VERSION ""

NS_ :

BS_:

BU_: MRRFR External_Tool CADM MRRFL

BO_ 680 MRR_FL_Radar_Reset_Msg: 1 MRRFL
 SG_ MRR_FL_Radar_Reset : 7|1@0+ (1,0) [0|1] ""  CADM

BO_ 679 MRR_FR_Radar_Reset_Msg: 1 MRRFR
 SG_ MRR_FR_Radar_Reset : 7|1@0+ (1,0) [0|1] ""  CADM

BO_ 762 MRR_FL_Radar_PartNumber: 64 MRRFL
 SG_ MRR_FL_EBOM_SW_PN_Part2 : 367|40@0+ (1,0) [0|1099511627775] ""  CADM
 SG_ MRR_FL_EBOM_SW_PN_Part1 : 327|40@0+ (1,0) [0|1099511627775] ""  CADM
 SG_ MRR_FL_ECU_SerialNumber_Part2 : 159|56@0+ (1,0) [0|7.20575940379279E+016] ""  CADM
 SG_ MRR_FL_ECU_SerialNumber_Part1 : 95|64@0+ (1,0) [0|1.84467440737096E+019] ""  CADM
 SG_ MRR_FL_EBOM_ECU_PN_Part2 : 447|40@0+ (1,0) [0|1099511627775] ""  CADM
 SG_ MRR_FL_EBOM_ECU_PN_Part1 : 407|40@0+ (1,0) [0|1099511627775] ""  CADM
 SG_ MRR_FL_SupplManuf_ECU_SW_VesrNum : 311|16@0+ (1,0) [0|65535] ""  CADM
 SG_ MRR_FL_SupplManuf_ECU_HW_VesrNum : 303|8@0+ (1,0) [0|255] ""  CADM
 SG_ MRR_FL_SupplManuf_ECU_SW_PN_2 : 263|40@0+ (1,0) [0|1099511627775] ""  CADM
 SG_ MRR_FL_SupplManuf_ECU_SW_PN_1 : 215|48@0+ (1,0) [0|281474976710655] ""  CADM
 SG_ MRR_FL_SupplManuf_ECU_HW_PN_2 : 55|40@0+ (1,0) [0|1099511627775] ""  CADM
 SG_ MRR_FL_SupplManuf_ECU_HW_PN_1 : 7|48@0+ (1,0) [0|281474976710655] ""  CADM

BO_ 692 MRR_FR_Radar_PartNumber: 64 MRRFR
 SG_ MRR_FR_EBOM_SW_PN_Part2 : 367|40@0+ (1,0) [0|1099511627775] ""  CADM
 SG_ MRR_FR_EBOM_SW_PN_Part1 : 327|40@0+ (1,0) [0|1099511627775] ""  CADM
 SG_ MRR_FR_ECU_SerialNumber_Part2 : 159|56@0+ (1,0) [0|7.20575940379279E+016] ""  CADM
 SG_ MRR_FR_ECU_SerialNumber_Part1 : 95|64@0+ (1,0) [0|1.84467440737096E+019] ""  CADM
 SG_ MRR_FR_EBOM_ECU_PN_Part2 : 447|40@0+ (1,0) [0|1099511627775] ""  CADM
 SG_ MRR_FR_EBOM_ECU_PN_Part1 : 407|40@0+ (1,0) [0|1099511627775] ""  CADM
 SG_ MRR_FR_SupplManuf_ECU_SW_VesrNum : 311|16@0+ (1,0) [0|65535] ""  CADM
 SG_ MRR_FR_SupplManuf_ECU_HW_VesrNum : 303|8@0+ (1,0) [0|255] ""  CADM
 SG_ MRR_FR_SupplManuf_ECU_SW_PN_2 : 263|40@0+ (1,0) [0|1099511627775] ""  CADM
 SG_ MRR_FR_SupplManuf_ECU_SW_PN_1 : 215|48@0+ (1,0) [0|281474976710655] ""  CADM
 SG_ MRR_FR_SupplManuf_ECU_HW_PN_2 : 55|40@0+ (1,0) [0|1099511627775] ""  CADM
 SG_ MRR_FR_SupplManuf_ECU_HW_PN_1 : 7|48@0+ (1,0) [0|281474976710655] ""  CADM

BO_ 37 MRR_FR_Angle_Adjustment_Table: 20 CADM
 SG_ MRR_FR_AAT_MC : 139|4@0+ (1,0) [0|15] ""  MRRFR
 SG_ MRR_FR_AAT_CRC : 151|16@0+ (1,0) [0|65535] ""  MRRFR
 SG_ MRR_FR_POS_80 : 135|8@0- (0.1,0) [-5|5] "deg"  MRRFR
 SG_ MRR_FR_POS_70 : 127|8@0- (0.1,0) [-5|5] "deg"  MRRFR
 SG_ MRR_FR_POS_60 : 119|8@0- (0.1,0) [-5|5] "deg"  MRRFR
 SG_ MRR_FR_POS_50 : 111|8@0- (0.1,0) [-5|5] "deg"  MRRFR
 SG_ MRR_FR_POS_40 : 103|8@0- (0.1,0) [-5|5] "deg"  MRRFR
 SG_ MRR_FR_POS_30 : 95|8@0- (0.1,0) [-5|5] "deg"  MRRFR
 SG_ MRR_FR_POS_20 : 87|8@0- (0.1,0) [-5|5] "deg"  MRRFR
 SG_ MRR_FR_POS_10 : 79|8@0- (0.1,0) [-5|5] "deg"  MRRFR
 SG_ MRR_FR_0 : 71|8@0- (0.1,0) [-5|5] "deg"  MRRFR
 SG_ MRR_FR_NEG_10 : 63|8@0- (0.1,0) [-5|5] "deg"  MRRFR
 SG_ MRR_FR_NEG_20 : 55|8@0- (0.1,0) [-5|5] "deg"  MRRFR
 SG_ MRR_FR_NEG_30 : 47|8@0- (0.1,0) [-5|5] "deg"  MRRFR
 SG_ MRR_FR_NEG_40 : 39|8@0- (0.1,0) [-5|5] "deg"  MRRFR
 SG_ MRR_FR_NEG_50 : 31|8@0- (0.1,0) [-5|5] "deg"  MRRFR
 SG_ MRR_FR_NEG_60 : 23|8@0- (0.1,0) [-5|5] "deg"  MRRFR
 SG_ MRR_FR_NEG_70 : 15|8@0- (0.1,0) [-5|5] "deg"  MRRFR
 SG_ MRR_FR_NEG_80 : 7|8@0- (0.1,0) [-5|5] "deg"  MRRFR

BO_ 36 MRR_FL_Angle_Adjustment_Table: 20 CADM
 SG_ MRR_FL_AAT_CRC : 151|16@0+ (1,0) [0|65535] ""  MRRFL
 SG_ MRR_FL_AAT_MC : 139|4@0+ (1,0) [0|15] ""  MRRFL
 SG_ MRR_FL_POS_80 : 135|8@0- (0.1,0) [-5|5] "deg"  MRRFL
 SG_ MRR_FL_POS_70 : 127|8@0- (0.1,0) [-5|5] "deg"  MRRFL
 SG_ MRR_FL_POS_60 : 119|8@0- (0.1,0) [-5|5] "deg"  MRRFL
 SG_ MRR_FL_POS_50 : 111|8@0- (0.1,0) [-5|5] "deg"  MRRFL
 SG_ MRR_FL_POS_40 : 103|8@0- (0.1,0) [-5|5] "deg"  MRRFL
 SG_ MRR_FL_POS_30 : 95|8@0- (0.1,0) [-5|5] "deg"  MRRFL
 SG_ MRR_FL_POS_20 : 87|8@0- (0.1,0) [-5|5] "deg"  MRRFL
 SG_ MRR_FL_POS_10 : 79|8@0- (0.1,0) [-5|5] "deg"  MRRFL
 SG_ MRR_FL_0 : 71|8@0- (0.1,0) [-5|5] "deg"  MRRFL
 SG_ MRR_FL_NEG_80 : 7|8@0- (0.1,0) [-5|5] "deg"  MRRFL
 SG_ MRR_FL_NEG_70 : 15|8@0- (0.1,0) [-5|5] "deg"  MRRFL
 SG_ MRR_FL_NEG_60 : 23|8@0- (0.1,0) [-5|5] "deg"  MRRFL
 SG_ MRR_FL_NEG_50 : 31|8@0- (0.1,0) [-5|5] "deg"  MRRFL
 SG_ MRR_FL_NEG_40 : 39|8@0- (0.1,0) [-5|5] "deg"  MRRFL
 SG_ MRR_FL_NEG_30 : 47|8@0- (0.1,0) [-5|5] "deg"  MRRFL
 SG_ MRR_FL_NEG_20 : 55|8@0- (0.1,0) [-5|5] "deg"  MRRFL
 SG_ MRR_FL_NEG_10 : 63|8@0- (0.1,0) [-5|5] "deg"  MRRFL

BO_ 673 MRR_CADM_TracksChange: 1 CADM
 SG_ MRR_f_Radar_Unreasonable : 7|1@0+ (1,0) [0|1] ""  MRRFL,MRRFR

BO_ 768 MRR_FL_Detection_001_007: 64 MRRFL
 SG_ MRR_FL_CAN_DET_MID_TARGET_007 : 462|1@0+ (1,0) [0|1] ""  CADM
 SG_ MRR_FL_CAN_DET_MID_TARGET_006 : 461|1@0+ (1,0) [0|1] ""  CADM
 SG_ MRR_FL_CAN_DET_MID_TARGET_005 : 460|1@0+ (1,0) [0|1] ""  CADM
 SG_ MRR_FL_CAN_DET_MID_TARGET_004 : 459|1@0+ (1,0) [0|1] ""  CADM
 SG_ MRR_FL_CAN_DET_MID_TARGET_003 : 458|1@0+ (1,0) [0|1] ""  CADM
 SG_ MRR_FL_CAN_DET_MID_TARGET_002 : 457|1@0+ (1,0) [0|1] ""  CADM
 SG_ MRR_FL_CAN_DET_MID_TARGET_001 : 456|1@0+ (1,0) [0|1] ""  CADM
 SG_ MRR_FL_CAN_DET_Near_TARGET_007 : 454|1@0+ (1,0) [0|1] ""  CADM
 SG_ MRR_FL_CAN_DET_Near_TARGET_006 : 453|1@0+ (1,0) [0|1] ""  CADM
 SG_ MRR_FL_CAN_DET_Near_TARGET_005 : 452|1@0+ (1,0) [0|1] ""  CADM
 SG_ MRR_FL_CAN_DET_Near_TARGET_004 : 451|1@0+ (1,0) [0|1] ""  CADM
 SG_ MRR_FL_CAN_DET_Near_TARGET_003 : 450|1@0+ (1,0) [0|1] ""  CADM
 SG_ MRR_FL_CAN_DET_Near_TARGET_002 : 449|1@0+ (1,0) [0|1] ""  CADM
 SG_ MRR_FL_CAN_DET_Near_TARGET_001 : 448|1@0+ (1,0) [0|1] ""  CADM
 SG_ MRR_FL_CAN_DET_ELEVATION_001 : 63|7@0+ (0.002748,-0.1745) [-0.1745|0.174496] "rad"  CADM
 SG_ MRR_FL_CAN_DET_CONFID_AZIMUTH_00 : 33|2@0+ (1,0) [0|3] ""  CADM
 SG_ MRR_FL_CAN_DET_SUPER_RES_TARGET_ : 56|1@0+ (1,0) [0|1] ""  CADM
 SG_ MRR_FL_CAN_DET_CONFID_ELEVATION_ : 49|1@0+ (1,0) [0|1] ""  CADM
 SG_ MRR_FL_CAN_DET_HOST_VEH_CLUTTER_ : 48|1@0+ (1,0) [0|1] ""  CADM
 SG_ MRR_FL_CAN_DET_VALID_LEVEL_001 : 0|1@0+ (1,0) [0|1] ""  CADM
 SG_ MRR_FL_CAN_DET_AZIMUTH_001 : 47|14@0+ (0.0003834,-3.1416) [-3.1416|3.1396422] "rad"  CADM
 SG_ MRR_FL_CAN_DET_RANGE_001 : 31|14@0+ (0.015625,0) [0|255.984375] "m"  CADM
 SG_ MRR_FL_CAN_DET_RANGE_RATE_001 : 15|14@0+ (0.015625,-128) [-128|127.984375] "m/s"  CADM
 SG_ MRR_FL_CAN_DET_AMPLITUDE_001 : 7|7@0+ (1,-64) [-64|63] "dBsm"  CADM
 SG_ MRR_FL_CAN_SCAN_INDEX_2LSB_001 : 17|2@0+ (1,0) [0|3] ""  CADM
 SG_ MRR_FL_DET_MC_001 : 491|4@0+ (1,0) [0|15] ""  CADM
 SG_ MRR_FL_DET_CRC_001 : 503|16@0+ (1,0) [0|65535] ""  CADM
 SG_ MRR_FL_CAN_DET_ELEVATION_007 : 447|7@0+ (0.002748,-0.1745) [-0.1745|0.174496] "rad"  CADM
 SG_ MRR_FL_CAN_DET_SUPER_RES_TA_0000 : 440|1@0+ (1,0) [0|1] ""  CADM
 SG_ MRR_FL_CAN_DET_AZIMUTH_007 : 431|14@0+ (0.0003834,-3.1416) [-3.1416|3.1396422] "rad"  CADM
 SG_ MRR_FL_CAN_DET_CONFID_ELEVA_0000 : 433|1@0+ (1,0) [0|1] ""  CADM
 SG_ MRR_FL_CAN_DET_HOST_VEH_CLU_0000 : 432|1@0+ (1,0) [0|1] ""  CADM
 SG_ MRR_FL_CAN_DET_RANGE_007 : 415|14@0+ (0.015625,0) [0|255.984375] "m"  CADM
 SG_ MRR_FL_CAN_DET_CONFID_AZIMU_0000 : 417|2@0+ (1,0) [0|3] ""  CADM
 SG_ MRR_FL_CAN_DET_RANGE_RATE_007 : 399|14@0+ (0.015625,-128) [-128|127.984375] "m/s"  CADM
 SG_ MRR_FL_CAN_SCAN_INDEX_2LSB_007 : 401|2@0+ (1,0) [0|3] ""  CADM
 SG_ MRR_FL_CAN_DET_AMPLITUDE_007 : 391|7@0+ (1,-64) [-64|63] "dBsm"  CADM
 SG_ MRR_FL_CAN_DET_VALID_LEVEL_007 : 384|1@0+ (1,0) [0|1] ""  CADM
 SG_ MRR_FL_CAN_DET_ELEVATION_006 : 383|7@0+ (0.002748,-0.1745) [-0.1745|0.174496] "rad"  CADM
 SG_ MRR_FL_CAN_DET_SUPER_RES_TA_0001 : 376|1@0+ (1,0) [0|1] ""  CADM
 SG_ MRR_FL_CAN_DET_AZIMUTH_006 : 367|14@0+ (0.0003834,-3.1416) [-3.1416|3.1396422] "rad"  CADM
 SG_ MRR_FL_CAN_DET_CONFID_ELEVA_0001 : 369|1@0+ (1,0) [0|1] ""  CADM
 SG_ MRR_FL_CAN_DET_HOST_VEH_CLU_0001 : 368|1@0+ (1,0) [0|1] ""  CADM
 SG_ MRR_FL_CAN_DET_RANGE_006 : 351|14@0+ (0.015625,0) [0|255.984375] "m"  CADM
 SG_ MRR_FL_CAN_DET_CONFID_AZIMU_0001 : 353|2@0+ (1,0) [0|3] ""  CADM
 SG_ MRR_FL_CAN_DET_RANGE_RATE_006 : 335|14@0+ (0.015625,-128) [-128|127.984375] "m/s"  CADM
 SG_ MRR_FL_CAN_SCAN_INDEX_2LSB_006 : 337|2@0+ (1,0) [0|3] ""  CADM
 SG_ MRR_FL_CAN_DET_AMPLITUDE_006 : 327|7@0+ (1,-64) [-64|63] "dBsm"  CADM
 SG_ MRR_FL_CAN_DET_VALID_LEVEL_006 : 320|1@0+ (1,0) [0|1] ""  CADM
 SG_ MRR_FL_CAN_DET_ELEVATION_005 : 319|7@0+ (0.002748,-0.1745) [-0.1745|0.174496] "rad"  CADM
 SG_ MRR_FL_CAN_DET_SUPER_RES_TA_0002 : 312|1@0+ (1,0) [0|1] ""  CADM
 SG_ MRR_FL_CAN_DET_AZIMUTH_005 : 303|14@0+ (0.0003834,-3.1416) [-3.1416|3.1396422] "rad"  CADM
 SG_ MRR_FL_CAN_DET_CONFID_ELEVA_0002 : 305|1@0+ (1,0) [0|1] ""  CADM
 SG_ MRR_FL_CAN_DET_HOST_VEH_CLU_0002 : 304|1@0+ (1,0) [0|1] ""  CADM
 SG_ MRR_FL_CAN_DET_RANGE_005 : 287|14@0+ (0.015625,0) [0|255.984375] "m"  CADM
 SG_ MRR_FL_CAN_DET_CONFID_AZIMU_0002 : 289|2@0+ (1,0) [0|3] ""  CADM
 SG_ MRR_FL_CAN_DET_RANGE_RATE_005 : 271|14@0+ (0.015625,-128) [-128|127.984375] "m/s"  CADM
 SG_ MRR_FL_CAN_SCAN_INDEX_2LSB_005 : 273|2@0+ (1,0) [0|3] ""  CADM
 SG_ MRR_FL_CAN_DET_AMPLITUDE_005 : 263|7@0+ (1,-64) [-64|63] "dBsm"  CADM
 SG_ MRR_FL_CAN_DET_VALID_LEVEL_005 : 256|1@0+ (1,0) [0|1] ""  CADM
 SG_ MRR_FL_CAN_DET_ELEVATION_004 : 255|7@0+ (0.002748,-0.1745) [-0.1745|0.174496] "rad"  CADM
 SG_ MRR_FL_CAN_DET_SUPER_RES_TA_0003 : 248|1@0+ (1,0) [0|1] ""  CADM
 SG_ MRR_FL_CAN_DET_AZIMUTH_004 : 239|14@0+ (0.0003834,-3.1416) [-3.1416|3.1396422] "rad"  CADM
 SG_ MRR_FL_CAN_DET_CONFID_ELEVA_0003 : 241|1@0+ (1,0) [0|1] ""  CADM
 SG_ MRR_FL_CAN_DET_HOST_VEH_CLU_0003 : 240|1@0+ (1,0) [0|1] ""  CADM
 SG_ MRR_FL_CAN_DET_RANGE_004 : 223|14@0+ (0.015625,0) [0|255.984375] "m"  CADM
 SG_ MRR_FL_CAN_DET_CONFID_AZIMU_0003 : 225|2@0+ (1,0) [0|3] ""  CADM
 SG_ MRR_FL_CAN_DET_RANGE_RATE_004 : 207|14@0+ (0.015625,-128) [-128|127.984375] "m/s"  CADM
 SG_ MRR_FL_CAN_SCAN_INDEX_2LSB_004 : 209|2@0+ (1,0) [0|3] ""  CADM
 SG_ MRR_FL_CAN_DET_AMPLITUDE_004 : 199|7@0+ (1,-64) [-64|63] "dBsm"  CADM
 SG_ MRR_FL_CAN_DET_VALID_LEVEL_004 : 192|1@0+ (1,0) [0|1] ""  CADM
 SG_ MRR_FL_CAN_DET_ELEVATION_003 : 191|7@0+ (0.002748,-0.1745) [-0.1745|0.174496] "rad"  CADM
 SG_ MRR_FL_CAN_DET_SUPER_RES_TA_0004 : 184|1@0+ (1,0) [0|1] ""  CADM
 SG_ MRR_FL_CAN_DET_AZIMUTH_003 : 175|14@0+ (0.0003834,-3.1416) [-3.1416|3.1396422] "rad"  CADM
 SG_ MRR_FL_CAN_DET_CONFID_ELEVA_0004 : 177|1@0+ (1,0) [0|1] ""  CADM
 SG_ MRR_FL_CAN_DET_HOST_VEH_CLU_0004 : 176|1@0+ (1,0) [0|1] ""  CADM
 SG_ MRR_FL_CAN_DET_RANGE_003 : 159|14@0+ (0.015625,0) [0|255.984375] "m"  CADM
 SG_ MRR_FL_CAN_DET_CONFID_AZIMU_0004 : 161|2@0+ (1,0) [0|3] ""  CADM
 SG_ MRR_FL_CAN_DET_RANGE_RATE_003 : 143|14@0+ (0.015625,-128) [-128|127.984375] "m/s"  CADM
 SG_ MRR_FL_CAN_SCAN_INDEX_2LSB_003 : 145|2@0+ (1,0) [0|3] ""  CADM
 SG_ MRR_FL_CAN_DET_AMPLITUDE_003 : 135|7@0+ (1,-64) [-64|63] "dBsm"  CADM
 SG_ MRR_FL_CAN_DET_VALID_LEVEL_003 : 128|1@0+ (1,0) [0|1] ""  CADM
 SG_ MRR_FL_CAN_DET_ELEVATION_002 : 127|7@0+ (0.002748,-0.1745) [-0.1745|0.174496] "rad"  CADM
 SG_ MRR_FL_CAN_DET_SUPER_RES_TA_0005 : 120|1@0+ (1,0) [0|1] ""  CADM
 SG_ MRR_FL_CAN_DET_AZIMUTH_002 : 111|14@0+ (0.0003834,-3.1416) [-3.1416|3.1396422] "rad"  CADM
 SG_ MRR_FL_CAN_DET_CONFID_ELEVA_0005 : 113|1@0+ (1,0) [0|1] ""  CADM
 SG_ MRR_FL_CAN_DET_HOST_VEH_CLU_0005 : 112|1@0+ (1,0) [0|1] ""  CADM
 SG_ MRR_FL_CAN_DET_RANGE_002 : 95|14@0+ (0.015625,0) [0|255.984375] "m"  CADM
 SG_ MRR_FL_CAN_DET_CONFID_AZIMU_0005 : 97|2@0+ (1,0) [0|3] ""  CADM
 SG_ MRR_FL_CAN_DET_RANGE_RATE_002 : 79|14@0+ (0.015625,-128) [-128|127.984375] "m/s"  CADM
 SG_ MRR_FL_CAN_SCAN_INDEX_2LSB_002 : 81|2@0+ (1,0) [0|3] ""  CADM
 SG_ MRR_FL_CAN_DET_AMPLITUDE_002 : 71|7@0+ (1,-64) [-64|63] "dBsm"  CADM
 SG_ MRR_FL_CAN_DET_VALID_LEVEL_002 : 64|1@0+ (1,0) [0|1] ""  CADM

BO_ 1346 MRR_Radar_Cfg_Parameters: 64 CADM
 SG_ SensorCfg_MRRFR_AlignRngTolVert : 431|8@0- (0.1,0) [-8|8] "deg"  MRRFL,MRRFR
 SG_ SensorCfg_MRRFL_AlignRngTolVert : 423|8@0- (0.1,0) [-8|8] "deg"  MRRFL,MRRFR
 SG_ SensorCfg_MRRRR_AlignRngTolVert : 415|8@0- (0.1,0) [-8|8] "deg" Vector__XXX
 SG_ SensorCfg_MRRRL_AlignRngTolVert : 407|8@0- (0.1,0) [-8|8] "deg" Vector__XXX
 SG_ SensorCfg_MRRFR_AlignRngTolHorz : 399|8@0- (0.1,0) [-8|8] "deg"  MRRFL,MRRFR
 SG_ SensorCfg_MRRFL_AlignRngTolHorz : 391|8@0- (0.1,0) [-8|8] "deg"  MRRFR,MRRFL
 SG_ SensorCfg_MRRRR_AlignRngTolHorz : 383|8@0- (0.1,0) [-8|8] "deg" Vector__XXX
 SG_ SensorCfg_MRRRL_AlignRngTolHorz : 375|8@0- (0.1,0) [-8|8] "deg" Vector__XXX
 SG_ MRR_SENSR_CFG_CRC : 503|16@0+ (1,0) [0|65535] ""  MRRFL,MRRFR
 SG_ SensorCfg_MRRRR_Pitch : 211|20@0- (1.526E-005,0) [-6|6] "deg" Vector__XXX
 SG_ SensorCfg_MRRFL_Pitch : 239|20@0- (1.526E-005,0) [-6|6] "deg"  MRRFL,MRRFR
 SG_ SensorCfg_MRRFR_Pitch : 251|20@0- (1.526E-005,0) [-6|6] "deg"  MRRFL,MRRFR
 SG_ SensorCfg_MRRRL_Pitch : 199|20@0- (1.526E-005,0) [-6|6] "deg" Vector__XXX
 SG_ SensorCfg_MRRRL_LatPos : 7|16@0- (1,0) [-1000|1000] "mm" Vector__XXX
 SG_ SensorCfg_MRRRR_LatPos : 23|16@0- (1,0) [-1000|1000] "mm" Vector__XXX
 SG_ SensorCfg_MRRFL_LatPos : 39|16@0- (1,0) [-1000|1000] "mm"  MRRFR,MRRFL
 SG_ SensorCfg_MRRFR_LatPos : 55|16@0- (1,0) [-1000|1000] "mm"  MRRFR,MRRFL
 SG_ SensorCfg_MRRRL_LongPos : 71|16@0- (1,0) [-6300|0] "mm" Vector__XXX
 SG_ SensorCfg_MRRRR_LongPos : 87|16@0- (1,0) [-6300|0] "mm" Vector__XXX
 SG_ SensorCfg_MRRFL_LongPos : 103|16@0- (1,0) [-6300|0] "mm"  MRRFR,MRRFL
 SG_ SensorCfg_MRRFR_LongPos : 119|16@0- (1,0) [-6300|0] "mm"  MRRFR,MRRFL
 SG_ SensorCfg_MRRRL_VertPos : 135|16@0+ (1,0) [0|2550] "mm" Vector__XXX
 SG_ SensorCfg_MRRRR_VertPos : 151|16@0+ (1,0) [0|2550] "mm" Vector__XXX
 SG_ SensorCfg_MRRFL_VertPos : 167|16@0+ (1,0) [0|2550] "mm"  MRRFR,MRRFL
 SG_ SensorCfg_MRRFR_VertPos : 183|16@0+ (1,0) [0|2550] "mm"  MRRFR,MRRFL
 SG_ SensorCfg_MRRRL_Yaw : 279|16@0- (0.01,0) [-180|180] "deg" Vector__XXX
 SG_ SensorCfg_MRRRR_Yaw : 295|16@0- (0.01,0) [-180|180] "deg" Vector__XXX
 SG_ SensorCfg_MRRFL_Yaw : 311|16@0- (0.01,0) [-180|180] "deg"  MRRFR,MRRFL
 SG_ SensorCfg_MRRFR_Yaw : 327|16@0- (0.01,0) [-180|180] "deg"  MRRFR,MRRFL
 SG_ SensorCfg_MRRRL_Orientation : 343|8@0- (1,0) [-1|1] "" Vector__XXX
 SG_ SensorCfg_MRRRR_Orientation : 351|8@0- (1,0) [-1|1] "" Vector__XXX
 SG_ SensorCfg_MRRFL_Orientation : 359|8@0- (1,0) [-1|1] ""  MRRFR,MRRFL
 SG_ SensorCfg_MRRFR_Orientation : 367|8@0- (1,0) [-1|1] ""  MRRFR,MRRFL

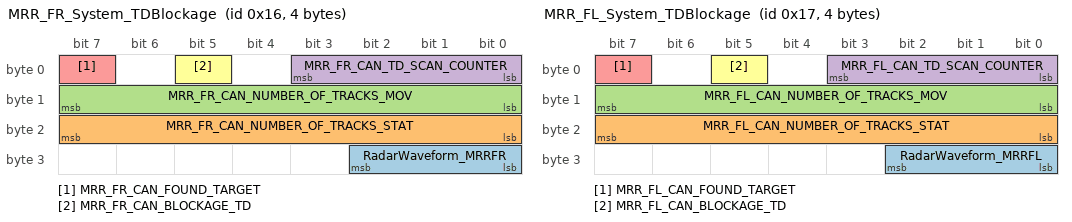
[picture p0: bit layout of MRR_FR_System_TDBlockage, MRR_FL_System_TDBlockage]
BO_ 22 MRR_FR_System_TDBlockage: 4 CADM
 SG_ RadarWaveform_MRRFR : 26|3@0+ (1,0) [0|7] ""  External_Tool,MRRFR
 SG_ MRR_FR_CAN_NUMBER_OF_TRACKS_STAT : 23|8@0+ (1,0) [0|255] ""  MRRFR,External_Tool
 SG_ MRR_FR_CAN_NUMBER_OF_TRACKS_MOV : 15|8@0+ (1,0) [0|255] ""  MRRFR,External_Tool
 SG_ MRR_FR_CAN_TD_SCAN_COUNTER : 3|4@0+ (1,0) [0|15] ""  MRRFR,External_Tool
 SG_ MRR_FR_CAN_FOUND_TARGET : 7|1@0+ (1,0) [0|1] ""  MRRFR,External_Tool
 SG_ MRR_FR_CAN_BLOCKAGE_TD : 5|1@0+ (1,0) [0|1] ""  MRRFR,External_Tool

BO_ 23 MRR_FL_System_TDBlockage: 4 CADM
 SG_ RadarWaveform_MRRFL : 26|3@0+ (1,0) [0|7] ""  External_Tool,MRRFL
 SG_ MRR_FL_CAN_NUMBER_OF_TRACKS_STAT : 23|8@0+ (1,0) [0|255] ""  MRRFL,External_Tool
 SG_ MRR_FL_CAN_NUMBER_OF_TRACKS_MOV : 15|8@0+ (1,0) [0|255] ""  MRRFL,External_Tool
 SG_ MRR_FL_CAN_TD_SCAN_COUNTER : 3|4@0+ (1,0) [0|15] ""  External_Tool,MRRFL
 SG_ MRR_FL_CAN_FOUND_TARGET : 7|1@0+ (1,0) [0|1] ""  External_Tool,MRRFL
 SG_ MRR_FL_CAN_BLOCKAGE_TD : 5|1@0+ (1,0) [0|1] ""  External_Tool,MRRFL

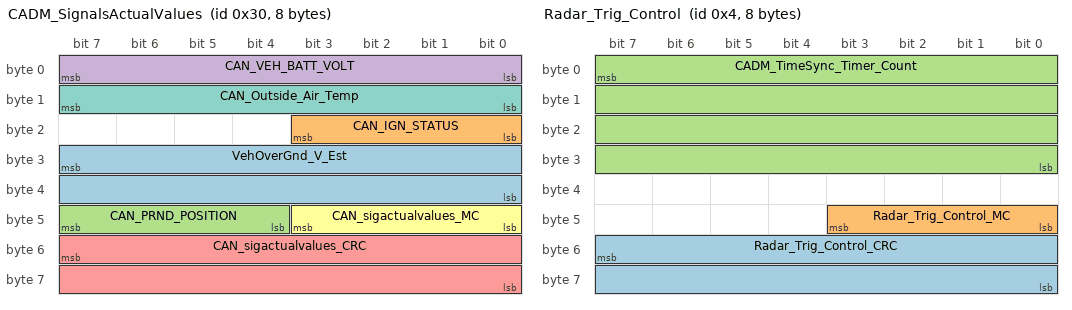
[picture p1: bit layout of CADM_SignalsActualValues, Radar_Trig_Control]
BO_ 48 CADM_SignalsActualValues: 8 CADM
 SG_ VehOverGnd_V_Est : 31|16@0+ (0.01,0) [0|655.35] "kph"  MRRFL,MRRFR
 SG_ CAN_IGN_STATUS : 19|4@0+ (1,0) [0|15] ""  MRRFL,MRRFR
 SG_ CAN_PRND_POSITION : 47|4@0+ (1,0) [0|15] ""  MRRFL,MRRFR
 SG_ CAN_VEH_BATT_VOLT : 7|8@0+ (0.0625,0) [0|15.875] "V"  MRRFL,MRRFR
 SG_ CAN_sigactualvalues_CRC : 55|16@0+ (1,0) [0|65535] ""  MRRFL,MRRFR
 SG_ CAN_sigactualvalues_MC : 43|4@0+ (1,0) [0|15] ""  MRRFL,MRRFR
 SG_ CAN_Outside_Air_Temp : 15|8@0+ (0.5,-40) [-40|87.5] "C"  MRRFR,MRRFL

BO_ 185 VEHICLE_STATE_MSG: 24 CADM
 SG_ CAN_CADM_Master : 57|2@0+ (1,0) [0|3] ""  External_Tool,MRRFL,MRRFR
 SG_ CAN_VEHICLE_SPEED : 135|11@0+ (0.0625,0) [0|127.9375] "m/s"  External_Tool,MRRFL,MRRFR
 SG_ CAN_STEERING_ANGLE : 119|14@0+ (0.1,0) [0|1638.3] "deg"  External_Tool,MRRFL,MRRFR
 SG_ CAN_VEHICLE_MODE : 107|4@0+ (1,0) [0|15] ""  External_Tool,MRRFL,MRRFR
 SG_ CAN_WIPER_STATUS : 42|1@0+ (1,0) [0|1] ""  External_Tool,MRRFL,MRRFR
 SG_ CAN_YAW_RATE : 103|12@0+ (0.0625,-128) [-128|127.9375] "deg/s"  External_Tool,MRRFL,MRRFR
 SG_ CAN_STEERING_ANGLE_SIGN : 7|1@0+ (1,0) [0|1] ""  External_Tool,MRRFL,MRRFR
 SG_ CAN_YAW_RATE_VALIDITY : 5|1@0+ (1,0) [0|1] ""  External_Tool,MRRFL,MRRFR
 SG_ CAN_VEHICLE_STAT : 6|1@0+ (1,0) [0|1] ""  External_Tool,MRRFL,MRRFR
 SG_ CAN_CADM_DrivingDirection : 9|2@0+ (1,0) [0|1] ""  External_Tool,MRRFL,MRRFR
 SG_ CAN_VEHICLE_SPEED_VALIDITY : 11|1@0+ (1,0) [0|1] ""  External_Tool,MRRFL,MRRFR
 SG_ CAN_VEHICLE_SPEED_DIRECTION : 10|1@0+ (1,0) [0|1] ""  External_Tool,MRRFL,MRRFR
 SG_ CAN_VEHICLE_SPEED_CALC_QF : 41|2@0+ (1,0) [0|3] ""  External_Tool,MRRFL,MRRFR
 SG_ CAN_VEHICLE_SPEED_CALC : 87|14@0+ (0.01,0) [0|100] "m/s"  External_Tool,MRRFL,MRRFR
 SG_ CAN_YAW_RATE_CALC : 71|13@0+ (0.03125,-100) [-100|100] "deg/s"  External_Tool,MRRFL,MRRFR
 SG_ CAN_YAW_RATE_CALC_QF : 59|2@0+ (1,0) [0|3] ""  External_Tool,MRRFL,MRRFR
 SG_ VEH_STATE_MSG_CRC : 183|16@0+ (1,0) [0|65535] ""  External_Tool,MRRFL,MRRFR
 SG_ VEH_STATE_MSG_MC : 171|4@0+ (1,0) [0|15] ""  External_Tool,MRRFL,MRRFR
 SG_ Yaw_Rate_Reference : 55|12@0- (0.03663,0) [-75|75] "deg/s"  MRRFL,MRRFR
 SG_ Yaw_Rate_Reference_Valid : 12|1@0+ (1,0) [0|1] "boolean"  MRRFL,MRRFR
 SG_ CAN_VEH_LONG_ACCEL_QF : 14|2@0+ (1,0) [0|3] ""  MRRFR,MRRFL,External_Tool
 SG_ CAN_VEH_LONG_ACCEL : 39|13@0+ (0.01,-40) [-40|41.89] "m/s^2"  MRRFR,MRRFL,External_Tool
 SG_ CAN_STEERING_WHL_ANGLE : 23|15@0+ (0.1,-1600) [-1600|1676.7] "deg"  MRRFR,MRRFL,External_Tool
 SG_ CAN_STEERING_WHL_ANGLE_QF : 2|1@0+ (1,0) [0|1] ""  MRRFR,MRRFL,External_Tool
 SG_ CAN_BRAKE_PEDAL : 1|2@0+ (1,0) [0|2] ""  MRRFR,MRRFL,External_Tool
 SG_ CAN_TURN_SIGNAL_STATUS : 4|2@0+ (1,0) [0|3] ""  MRRFR,MRRFL,External_Tool

BO_ 1795 SAT_CADM_VIN: 32 CADM
 SG_ k_radar_azimuth_polarity : 207|8@0- (1,0) [-2|1] ""  MRRFL,MRRFR
 SG_ CAN_FA_VERT_UPPER_LIMIT : 199|8@0- (0.0625,0) [-8|7.9375] ""  MRRFL,MRRFR
 SG_ CAN_FA_VERT_LOWER_LIMIT : 191|8@0- (0.0625,0) [-8|7.9375] ""  MRRFL,MRRFR
 SG_ CAN_FA_VERT_GROUND_OFFSET : 183|8@0- (0.0625,0) [-8|7.9375] ""  MRRFL,MRRFR
 SG_ SAT_CAN_ODOMETER : 143|20@0+ (1,0) [0|1048575] "km"  MRRFL,MRRFR
 SG_ SAT_VIN_part3 : 135|8@0+ (1,0) [0|255] ""  MRRFR,MRRFL
 SG_ SAT_VIN_part2 : 71|64@0+ (1,0) [0|1.84467E+019] ""  MRRFR,MRRFL
 SG_ SAT_VIN_part1 : 7|64@0+ (1,0) [0|1.84467E+019] ""  MRRFR,MRRFL

BO_ 16 MRR_FL_System_Control: 8 External_Tool
 SG_ MRR_FL_CAN_INST_MODE : 7|16@0+ (1,0) [0|65535] ""  MRRFL

BO_ 17 MRR_FR_System_Control: 8 External_Tool
 SG_ MRR_FR_CAN_INST_MODE : 7|16@0+ (1,0) [0|65535] ""  MRRFR

BO_ 1796 CADM_SWVersion: 12 CADM
 SG_ CAN_INTF_MINOR_VERSION : 74|3@0+ (1,0) [0|7] ""  MRRFL,MRRFR
 SG_ CAN_INTF_MAJOR_VERSION : 79|5@0+ (1,0) [0|31] ""  MRRFL,MRRFR
 SG_ CAN_PCAN_MINOR_CADM_HOST : 67|4@0+ (1,0) [0|15] ""  MRRFL,MRRFR
 SG_ CAN_PCAN_MAJOR_CADM_HOST : 71|4@0+ (1,0) [0|15] ""  MRRFL,MRRFR
 SG_ CADM_Field_Rev : 55|16@0+ (1,0) [0|65535] ""  MRRFR,MRRFL
 SG_ CADM_SW_Promote_Rev : 39|16@0+ (1,0) [0|65535] ""  MRRFR,MRRFL
 SG_ CADM_SW_Release_Rev : 23|16@0+ (1,0) [0|65535] ""  MRRFR,MRRFL
 SG_ CAN_PCAN_MINOR_VER : 15|8@0+ (1,0) [0|255] ""  MRRFR,MRRFL
 SG_ CAN_PCAN_MAJOR_VER : 7|8@0+ (1,0) [0|255] ""  MRRFR,MRRFL

BO_ 395 MRR_FL_Header_AlignmentState: 16 MRRFL
 SG_ MRR_FL_CAN_VRTCL_ALIGN_UPDATES_N : 87|16@0+ (1,0) [0|65535] ""  CADM,External_Tool
 SG_ MRR_FL_CAN_HRZNTL_ALIGN_UPDATES_ : 71|16@0+ (1,0) [0|65535] ""  CADM,External_Tool
 SG_ MRR_FL_Header_AlignmentState_CRC : 119|16@0+ (1,0) [0|65535] ""  CADM,External_Tool
 SG_ MRR_FL_Header_AlignmentState_MC : 107|4@0+ (1,0) [0|15] ""  CADM,External_Tool
 SG_ MRR_FL_Horizontal_Alignment_Stat : 27|4@0+ (1,0) [0|15] ""  CADM,External_Tool
 SG_ MRR_FL_Vertical_Alignment_Status : 59|4@0+ (1,0) [0|15] ""  CADM,External_Tool
 SG_ MRR_FL_Vertical_Alignment_State : 44|3@0+ (1,0) [0|7] ""  CADM,External_Tool
 SG_ MRR_FL_Horizontal_Alignment_0000 : 12|3@0+ (1,0) [0|7] ""  CADM,External_Tool
 SG_ MRR_FL_Align_Vertical_Ref : 55|10@0+ (0.000170608920038546,-0.0872664625997165) [-0.0872664625997165|0.0872664625997165] "Rad"  CADM,External_Tool
 SG_ MRR_FL_Align_Vertical_QF : 41|2@0+ (1,0) [0|3] ""  CADM,External_Tool
 SG_ MRR_FL_Align_Vertical_Angle : 39|10@0+ (0.000170608920038546,-0.0872664625997165) [-0.0872664625997165|0.0872664625997165] "Rad"  CADM,External_Tool
 SG_ MRR_FL_Align_Horizontal_Angle : 7|10@0+ (0.000341217840077093,-0.174532925199433) [-0.174532925199433|0.174532925199433] "Rad"  CADM,External_Tool
 SG_ MRR_FL_Align_Horizontal_Ref : 23|10@0+ (0.000341217840077093,-0.174532925199433) [-0.174532925199433|0.174532925199433] "Rad"  CADM,External_Tool
 SG_ MRR_FL_Align_Horizontal_QF : 9|2@0+ (1,0) [0|3] ""  CADM,External_Tool

BO_ 459 MRR_FR_Header_AlignmentState: 16 MRRFR
 SG_ MRR_FR_CAN_VRTCL_ALIGN_UPDATES_N : 87|16@0+ (1,0) [0|65535] ""  CADM,External_Tool
 SG_ MRR_FR_CAN_HRZNTL_ALIGN_UPDATES_ : 71|16@0+ (1,0) [0|65535] ""  CADM,External_Tool
 SG_ MRR_FR_Header_AlignmentState_CRC : 119|16@0+ (1,0) [0|65535] ""  CADM,External_Tool
 SG_ MRR_FR_Header_AlignmentState_MC : 107|4@0+ (1,0) [0|15] ""  CADM,External_Tool
 SG_ MRR_FR_Horizontal_Alignment_Stat : 27|4@0+ (1,0) [0|15] ""  CADM,External_Tool
 SG_ MRR_FR_Vertical_Alignment_Status : 59|4@0+ (1,0) [0|15] ""  CADM,External_Tool
 SG_ MRR_FR_Vertical_Alignment_State : 44|3@0+ (1,0) [0|7] ""  CADM,External_Tool
 SG_ MRR_FR_Horizontal_Alignment_0000 : 12|3@0+ (1,0) [0|7] ""  CADM,External_Tool
 SG_ MRR_FR_Align_Vertical_Ref : 55|10@0+ (0.000170608920038546,-0.0872664625997165) [-0.0872664625997165|0.0872664625997165] "Rad"  CADM,External_Tool
 SG_ MRR_FR_Align_Vertical_QF : 41|2@0+ (1,0) [0|3] ""  CADM,External_Tool
 SG_ MRR_FR_Align_Vertical_Angle : 39|10@0+ (0.000170608920038546,-0.0872664625997165) [-0.0872664625997165|0.0872664625997165] "Rad"  CADM,External_Tool
 SG_ MRR_FR_Align_Horizontal_Angle : 7|10@0+ (0.000341217840077093,-0.174532925199433) [-0.174532925199433|0.174532925199433] "Rad"  CADM,External_Tool
 SG_ MRR_FR_Align_Horizontal_Ref : 23|10@0+ (0.000341217840077093,-0.174532925199433) [-0.174532925199433|0.174532925199433] "Rad"  CADM,External_Tool
 SG_ MRR_FR_Align_Horizontal_QF : 9|2@0+ (1,0) [0|3] ""  CADM,External_Tool

BO_ 4 Radar_Trig_Control: 8 CADM
 SG_ Radar_Trig_Control_CRC : 55|16@0+ (1,0) [0|65535] ""  MRRFL,MRRFR
 SG_ Radar_Trig_Control_MC : 43|4@0+ (1,0) [0|15] ""  MRRFL,MRRFR
 SG_ CADM_TimeSync_Timer_Count : 7|32@0+ (1,0) [0|4294967295] "us"  MRRFR,MRRFL

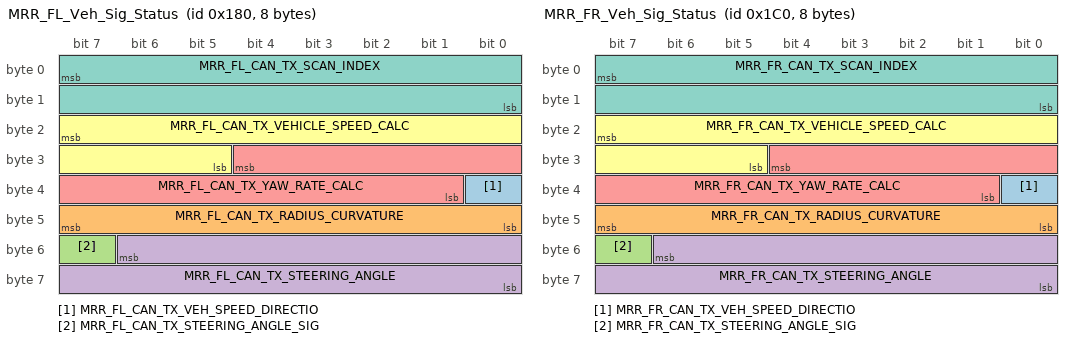
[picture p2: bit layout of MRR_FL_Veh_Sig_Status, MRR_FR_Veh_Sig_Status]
BO_ 384 MRR_FL_Veh_Sig_Status: 8 MRRFL
 SG_ MRR_FL_CAN_TX_VEH_SPEED_DIRECTIO : 32|1@0+ (1,0) [0|1] ""  CADM
 SG_ MRR_FL_CAN_TX_RADIUS_CURVATURE : 47|8@0- (25,0) [-3200|3175] "m"  CADM
 SG_ MRR_FL_CAN_TX_STEERING_ANGLE_SIG : 55|1@0+ (1,0) [0|1] ""  CADM
 SG_ MRR_FL_CAN_TX_STEERING_ANGLE : 54|15@0+ (1,0) [0|32767] "deg"  CADM
 SG_ MRR_FL_CAN_TX_YAW_RATE_CALC : 28|12@0- (0.0625,0) [-128|127.9375] "deg/s"  CADM
 SG_ MRR_FL_CAN_TX_VEHICLE_SPEED_CALC : 23|11@0+ (0.0625,0) [0|127.9375] "m/s"  CADM
 SG_ MRR_FL_CAN_TX_SCAN_INDEX : 7|16@0+ (1,0) [0|65535] ""  CADM

BO_ 385 MRR_FL_HW_Version_Status: 64 MRRFL
 SG_ MRR_FL_Dolphin_Chip_ID_Part2 : 327|64@0+ (1,0) [0|1.84467440737096E+019] ""  CADM,External_Tool
 SG_ MRR_FL_Dolphin_Chip_ID_Part1 : 263|64@0+ (1,0) [0|1.84467440737096E+019] ""  CADM,External_Tool
 SG_ MRR_FL_RRU_Chip_ID_Part4 : 199|64@0+ (1,0) [0|1.84467440737096E+019] ""  CADM,External_Tool
 SG_ MRR_FL_RRU_Chip_ID_Part3 : 135|64@0+ (1,0) [0|1.84467440737096E+019] ""  CADM,External_Tool
 SG_ MRR_FL_RRU_Chip_ID_Part2 : 71|64@0+ (1,0) [0|1.84467440737096E+019] ""  CADM,External_Tool
 SG_ MRR_FL_RRU_Chip_ID_Part1 : 7|64@0+ (1,0) [0|1.84467440737096E+019] ""  CADM,External_Tool
 SG_ MRR_FL_CAN_TX_HW_VERSION : 391|4@0+ (1,0) [0|15] ""  CADM,External_Tool

BO_ 386 MRR_FL_SW_Version_Status: 48 MRRFL
 SG_ MRR_FL_CAN_PCAN_PROTOCOL_PROMOTE : 263|8@0+ (1,0) [0|255] ""  CADM,External_Tool
 SG_ MRR_FL_CAN_TX_SW_VERSION_DSP : 295|24@0+ (1,0) [0|16777215] ""  CADM
 SG_ MRR_FL_CAN_TX_SW_VERSION_ARM : 271|24@0+ (1,0) [0|16777215] ""  CADM
 SG_ MRR_FL_CAN_TX_PCAN_PROTOCOL_MINO : 243|8@0+ (1,0) [0|255] ""  CADM
 SG_ MRR_FL_CAN_TX_PCAN_PROTOCOL_MAJO : 247|4@0+ (1,0) [0|15] ""  CADM
 SG_ MRR_FL_CAN_Dyn_Align_Algorithm_V : 223|8@0+ (1,0) [0|255] ""  External_Tool,CADM
 SG_ MRR_FL_CAN_Dyn_Align_Algori_0000 : 231|8@0+ (1,0) [0|255] ""  External_Tool,CADM
 SG_ MRR_FL_CAN_Dyn_Align_Algori_0001 : 239|8@0+ (1,0) [0|255] ""  External_Tool,CADM
 SG_ MRR_FL_Core_Radar_BB_Version_Fie : 215|8@0+ (1,0) [0|255] ""  CADM
 SG_ MRR_FL_Core_Radar_BB_Version_Pro : 207|8@0+ (1,0) [0|255] ""  CADM
 SG_ MRR_FL_Core_Radar_BB_Version_Min : 199|8@0+ (1,0) [0|255] ""  CADM
 SG_ MRR_FL_Core_Radar_BB_Version_Maj : 191|8@0+ (1,0) [0|255] ""  CADM
 SG_ MRR_FL_CAN_USC_Field : 183|8@0+ (1,0) [0|255] ""  CADM
 SG_ MRR_FL_CAN_USC_Promote : 175|8@0+ (1,0) [0|255] ""  CADM
 SG_ MRR_FL_CAN_USC_Minor : 167|8@0+ (1,0) [0|255] ""  CADM
 SG_ MRR_FL_CAN_USC_Major : 159|8@0+ (1,0) [0|255] ""  CADM
 SG_ MRR_FL_CAN_SMC_Field : 151|8@0+ (1,0) [0|255] ""  CADM
 SG_ MRR_FL_CAN_SMC_Promote : 143|8@0+ (1,0) [0|255] ""  CADM
 SG_ MRR_FL_CAN_SMC_Minor : 135|8@0+ (1,0) [0|255] ""  CADM
 SG_ MRR_FL_CAN_SMC_Major : 127|8@0+ (1,0) [0|255] ""  CADM
 SG_ MRR_FL_CAN_TX_Field : 23|8@0+ (1,0) [0|255] ""  CADM
 SG_ MRR_FL_CAN_TX_Promote : 13|6@0+ (1,0) [0|63] ""  CADM
 SG_ MRR_FL_CAN_TX_Major : 3|6@0+ (1,0) [0|63] ""  CADM
 SG_ MRR_FL_CAN_TX_Hardware : 7|4@0+ (1,0) [0|15] ""  CADM
 SG_ MRR_FL_CAN_TX_SERIAL_NUMBER_SEQU : 35|12@0+ (1,0) [0|4095] ""  CADM
 SG_ MRR_FL_CAN_TX_SERIAL_NUM_JULIAN_ : 38|3@0+ (1,2014) [2014|2021] ""  CADM
 SG_ MRR_FL_CAN_TX_SERIAL_NUM_JU_0000 : 31|9@0+ (1,0) [0|511] ""  CADM
 SG_ MRR_FL_CAN_TX_ARM_THROUGHPUT : 63|5@0+ (3.2258,0) [0|99.9998] ""  CADM
 SG_ MRR_FL_CAN_TX_SYSTEM_STATUS : 58|3@0+ (1,0) [0|7] ""  CADM
 SG_ MRR_FL_CAN_TX_LOOK_TYPE_1 : 50|1@0+ (1,0) [0|1] ""  CADM
 SG_ MRR_FL_CAN_TX_OVERHEAT_ERROR : 51|1@0+ (1,0) [0|1] ""  CADM
 SG_ MRR_FL_CAN_TX_RANGE_PERF_ERROR : 52|1@0+ (1,0) [0|1] ""  CADM
 SG_ MRR_FL_CAN_TX_COMM_ERROR : 53|1@0+ (1,0) [0|1] ""  CADM
 SG_ MRR_FL_CAN_TX_INTERNAL_ERROR : 54|1@0+ (1,0) [0|1] ""  CADM
 SG_ MRR_FL_CAN_TX_XCVR_OPERATIONAL : 55|1@0+ (1,0) [0|1] ""  CADM
 SG_ MRR_FL_CAN_PBL_Field_Revision : 119|8@0+ (1,0) [0|255] ""  CADM
 SG_ MRR_FL_CAN_PBL_Promote_Revision : 111|8@0+ (1,0) [0|255] ""  CADM
 SG_ MRR_FL_CAN_SW_Field_Revision : 87|8@0+ (1,0) [0|255] ""  CADM
 SG_ MRR_FL_CAN_SW_Promote_Revision : 79|8@0+ (1,0) [0|255] ""  CADM
 SG_ MRR_FL_CAN_SW_Field : 95|8@0+ (1,0) [0|255] ""  CADM
 SG_ MRR_FL_CAN_SW_Release_Revision : 71|8@0+ (1,0) [0|255] ""  CADM
 SG_ MRR_FL_CAN_PBL_Release_Revision : 103|8@0+ (1,0) [0|255] ""  CADM

BO_ 387 MRR_FL_Alignment_Status: 12 MRRFL
 SG_ MRR_FL_Alignment_Status_CRC : 87|16@0+ (1,0) [0|65535] ""  CADM
 SG_ MRR_FL_Alignment_Status_MC : 75|4@0+ (1,0) [0|15] ""  CADM
 SG_ MRR_FL_CAN_TX_DRIVING_ENVIRONMEN : 41|2@0+ (1,0) [0|3] ""  CADM
 SG_ MRR_FL_CAN_TX_ROLLING_COUNT_1 : 33|2@0+ (1,0) [0|3] ""  CADM
 SG_ MRR_FL_CAN_TX_Temperature : 63|8@0+ (1,-50) [-50|205] "degC"  CADM
 SG_ MRR_FL_CAN_TX_YAW_RATE_BIAS : 55|8@0- (0.125,0) [-16|15.875] ""  CADM
 SG_ MRR_FL_CAN_TX_VEH_SPD_COMP_FACTO : 47|6@0- (0.001953125,1) [0.9375|1.060546875] ""  CADM
 SG_ MRR_FL_CAN_TX_AUTO_ALIGN_QUA_FAC : 35|2@0+ (1,0) [0|3] ""  CADM
 SG_ MRR_FL_CAN_TX_Alignment_MODE : 39|4@0+ (1,0) [0|15] ""  CADM
 SG_ MRR_FL_CAN_TX_CURRENT_MISALIGN_A : 23|16@0- (0.0009765625,0) [-32|31.9990234375] "Deg"  CADM
 SG_ MRR_FL_CAN_TX_SAVED_MISALIGN_ANG : 7|16@0- (0.0009765625,0) [-32|31.9990234375] "Deg"  CADM

BO_ 388 MRR_FL_Active_Fault_Status: 20 MRRFL
 SG_ MRR_FL_TO_SystemTDBlockage_Flt : 87|1@0+ (1,0) [0|1] ""  CADM
 SG_ MRR_FL_TO_CADMSWVersion_Flt : 95|1@0+ (1,0) [0|1] ""  CADM
 SG_ MRR_FL_TO_RADARCfgParameter_Flt : 94|1@0+ (1,0) [0|1] ""  CADM
 SG_ MRR_FL_TO_SATCADMVIN_Flt : 93|1@0+ (1,0) [0|1] ""  CADM
 SG_ MRR_FL_TO_CADMTracksChange_Flt : 92|1@0+ (1,0) [0|1] ""  CADM
 SG_ MRR_FL_Active_Fault_Status_CRC : 151|16@0+ (1,0) [0|65535] ""  CADM
 SG_ MRR_FL_Active_Fault_Status_MC : 139|4@0+ (1,0) [0|15] ""  CADM
 SG_ MRR_FL_Dolphin_Flt : 71|1@0+ (1,0) [0|1] ""  CADM
 SG_ MRR_FL_RRUCore_Flt : 70|1@0+ (1,0) [0|1] ""  CADM
 SG_ MRR_FL_RRUBIST_Flt : 72|1@0+ (1,0) [0|1] ""  CADM
 SG_ MRR_FL_PINPosition_Flt : 69|1@0+ (1,0) [0|1] ""  CADM
 SG_ MRR_FL_PCANDataRangeChk_Flt : 68|1@0+ (1,0) [0|1] ""  CADM
 SG_ MRR_FL_TO_AngleAdjustmentTable_F : 88|1@0+ (1,0) [0|1] ""  CADM
 SG_ MRR_FL_TO_CADMSgnlActlVal_Flt : 86|1@0+ (1,0) [0|1] ""  CADM
 SG_ MRR_FL_TO_TrigControl_Flt : 85|1@0+ (1,0) [0|1] ""  CADM
 SG_ MRR_FL_TO_VehicleState_Flt : 84|1@0+ (1,0) [0|1] ""  CADM
 SG_ MRR_FL_MC_AngleAdjTable_Flt : 83|1@0+ (1,0) [0|1] ""  CADM
 SG_ MRR_FL_CRC_AngleAdjTable_Flt : 82|1@0+ (1,0) [0|1] ""  CADM
 SG_ MRR_FL_MC_VehicleState_Flt : 81|1@0+ (1,0) [0|1] ""  CADM
 SG_ MRR_FL_CRC_VehicleState_Flt : 80|1@0+ (1,0) [0|1] ""  CADM
 SG_ MRR_FL_MC_TrigControl_Flt : 79|1@0+ (1,0) [0|1] ""  CADM
 SG_ MRR_FL_CRC_TrigControl_Flt : 78|1@0+ (1,0) [0|1] ""  CADM
 SG_ MRR_FL_CRC_RadarCfgParameter_Flt : 75|1@0+ (1,0) [0|1] ""  CADM
 SG_ MRR_FL_MC_CADMSgnlActlVal_Flt : 74|1@0+ (1,0) [0|1] ""  CADM
 SG_ MRR_FL_CRC_CADMSgnlActlVal_Flt : 73|1@0+ (1,0) [0|1] ""  CADM
 SG_ MRR_FL_VINSignalCompare_Flt : 66|1@0+ (1,0) [0|1] ""  CADM
 SG_ MRR_FL_BatteryLow_Flt : 63|1@0+ (1,0) [0|1] ""  CADM
 SG_ MRR_FL_BatteryHigh_Flt : 62|1@0+ (1,0) [0|1] ""  CADM
 SG_ MRR_FL_Core0_To_Core1_IPC_Flt : 60|1@0+ (1,0) [0|1] ""  CADM
 SG_ MRR_FL_Core1_To_Core0_IPC_Flt : 61|1@0+ (1,0) [0|1] ""  CADM
 SG_ MRR_FL_Core1_To_Core2_IPC_Flt : 59|1@0+ (1,0) [0|1] ""  CADM
 SG_ MRR_FL_Core2_To_Core1_IPC_Flt : 58|1@0+ (1,0) [0|1] ""  CADM
 SG_ MRR_FL_Core2_To_Core0_IPC_Flt : 57|1@0+ (1,0) [0|1] ""  CADM
 SG_ MRR_FL_Core2Halted_Flt : 19|1@0+ (1,0) [0|1] ""  CADM
 SG_ MRR_FL_Core1Halted_Flt : 18|1@0+ (1,0) [0|1] ""  CADM
 SG_ MRR_FL_LocalOscPower_Flt : 50|1@0+ (1,0) [0|1] ""  CADM
 SG_ MRR_FL_DSPLoopOverrun_Flt : 54|1@0+ (1,0) [0|1] ""  CADM
 SG_ MRR_FL_TransmitterPower_Flt : 49|1@0+ (1,0) [0|1] ""  CADM
 SG_ MRR_FL_Core0_To_Core2_IPC_Flt : 56|1@0+ (1,0) [0|1] ""  CADM
 SG_ MRR_FL_XCVRDeviceSPI_Flt : 45|1@0+ (1,0) [0|1] ""  CADM
 SG_ MRR_FL_MNRBlockage_Flt : 40|1@0+ (1,0) [0|1] ""  CADM
 SG_ MRR_FL_TransmitterTempHigh_Flt : 38|1@0+ (1,0) [0|1] ""  CADM
 SG_ MRR_FL_AlignRoutineFailed_Flt : 37|1@0+ (1,0) [0|1] ""  CADM
 SG_ MRR_FL_MicroTempHigh_Flt : 35|1@0+ (1,0) [0|1] ""  CADM
 SG_ MRR_FL_HAlignOutofRange_Flt : 33|1@0+ (1,0) [0|1] ""  CADM
 SG_ MRR_FL_v1p1_SupplyOutOfRange_Flt : 30|1@0+ (1,0) [0|1] ""  CADM
 SG_ MRR_FL_v1p25_SupplyOutOfRange_Fl : 29|1@0+ (1,0) [0|1] ""  CADM
 SG_ MRR_FL_v1p8_SupplyOutOfRange_Flt : 28|1@0+ (1,0) [0|1] ""  CADM
 SG_ MRR_FL_v2p3_SupplyOutOfRange_Flt : 27|1@0+ (1,0) [0|1] ""  CADM
 SG_ MRR_FL_v_5_SupplyOutOfRange_Flt : 24|1@0+ (1,0) [0|1] ""  CADM
 SG_ MRR_FL_TransmitterID_Flt : 23|1@0+ (1,0) [0|1] ""  CADM
 SG_ MRR_FL_PCANBusOff_Flt : 16|1@0+ (1,0) [0|1] ""  CADM
 SG_ MRR_FL_InstructionSetCheck_Flt : 13|1@0+ (1,0) [0|1] ""  CADM
 SG_ MRR_FL_StackOverflow_Flt : 12|1@0+ (1,0) [0|1] ""  CADM
 SG_ MRR_FL_Watchdog_Flt : 11|1@0+ (1,0) [0|1] ""  CADM
 SG_ MRR_FL_PLLLock_Flt : 10|1@0+ (1,0) [0|1] ""  CADM
 SG_ MRR_FL_RAMMemoryTest_Flt : 8|1@0+ (1,0) [0|1] ""  CADM
 SG_ MRR_FL_USCValidation_Flt : 7|1@0+ (1,0) [0|1] ""  CADM
 SG_ MRR_FL_SMCChecksum_Flt : 4|1@0+ (1,0) [0|1] ""  CADM
 SG_ MRR_FL_KeepAliveChecksum_Flt : 2|1@0+ (1,0) [0|1] ""  CADM
 SG_ MRR_FL_ApplicationFlashChksum_Fl : 0|1@0+ (1,0) [0|1] ""  CADM

BO_ 389 MRR_FL_Error_Status: 32 MRRFL
 SG_ MRR_FL_XBAR_cfg_failure : 255|1@0+ (1,0) [0|1] ""  External_Tool
 SG_ MRR_FL_Stack_OVF_fault_reason : 247|3@0+ (1,0) [0|7] ""  External_Tool
 SG_ MRR_FL_App_flash_checksum_reason : 244|3@0+ (1,0) [0|7] ""  External_Tool
 SG_ MRR_FL_KAM_fault_reason : 241|2@0+ (1,0) [0|3] ""  External_Tool
 SG_ MRR_FL_RRU_Self_Test_Faults_reas : 239|8@0+ (1,0) [0|255] ""  External_Tool
 SG_ MRR_FL_RRU_Core_Faults_reason3 : 231|8@0+ (1,0) [0|255] ""  External_Tool
 SG_ MRR_FL_RRU_Core_Faults_reason2 : 167|64@0+ (1,0) [0|1.84467440737096E+019] ""  External_Tool
 SG_ MRR_FL_RRU_Core_Faults_reason1 : 103|64@0+ (1,0) [0|1.84467440737096E+019] ""  External_Tool
 SG_ MRR_FL_Rx_Radar_Mount_Msg_Fault : 88|1@0+ (1,0) [0|1] ""  External_Tool
 SG_ MRR_FL_Dolphin_Fault_Detection : 87|8@0+ (1,0) [0|63] ""  External_Tool
 SG_ MRR_FL_RRU_Self_Test_Faults_0000 : 79|8@0+ (1,0) [0|255] ""  External_Tool
 SG_ MRR_FL_RRU_Core_Faults_reason0 : 71|8@0+ (1,0) [0|255] ""  External_Tool
 SG_ MRR_FL_USC_Load_Error : 59|1@0+ (1,0) [0|1] ""  External_Tool
 SG_ MRR_FL_SMC_Load_Error : 58|1@0+ (1,0) [0|1] ""  External_Tool
 SG_ MRR_FL_TX_Temperature_Flt : 57|1@0+ (1,0) [0|1] ""  External_Tool
 SG_ MRR_FL_Dsp_Unit_Cal_Blk_Chcksm_E : 56|1@0+ (1,0) [0|1] ""  External_Tool
 SG_ MRR_FL_Dsp_Unit_Cal_Checksum_Err : 55|1@0+ (1,0) [0|1] ""  External_Tool
 SG_ MRR_FL_Vertical_Misalignment_err : 54|1@0+ (1,0) [0|1] ""  External_Tool
 SG_ MRR_FL_RTN_SPI_Transfer_Error : 53|1@0+ (1,0) [0|1] ""  External_Tool
 SG_ MRR_FL_RRN_SPI_Transfer_Error : 52|1@0+ (1,0) [0|1] ""  External_Tool
 SG_ MRR_FL_Linearizer_SPI_Transfer_E : 51|1@0+ (1,0) [0|1] ""  External_Tool
 SG_ MRR_FL_ADC_SPI_Transfer_Error : 50|1@0+ (1,0) [0|1] ""  External_Tool
 SG_ MRR_FL_Transmitter_ID_Error : 49|1@0+ (1,0) [0|1] ""  External_Tool
 SG_ MRR_FL_Dsp_Loop_Overrun_Error : 48|1@0+ (1,0) [0|1] ""  External_Tool
 SG_ MRR_FL_Saturated_Tuning_Freq_Err : 47|1@0+ (1,0) [0|1] ""  External_Tool
 SG_ MRR_FL_Radar_Data_sync_error : 46|1@0+ (1,0) [0|1] ""  External_Tool
 SG_ MRR_FL_Dsp_Tuning_Sensitivity_Er : 45|1@0+ (1,0) [0|1] ""  External_Tool
 SG_ MRR_FL_Radar_LO_Power_Error : 44|1@0+ (1,0) [0|1] ""  External_Tool
 SG_ MRR_FL_Radar_TX_Power_Error : 43|1@0+ (1,0) [0|1] ""  External_Tool
 SG_ MRR_FL_Timer_Create_Error : 6|1@0+ (1,0) [0|1] ""  External_Tool
 SG_ MRR_FL_Thread_Create_Error : 2|1@0+ (1,0) [0|1] ""  External_Tool
 SG_ MRR_FL_ARM_Calibration_Error : 9|1@0+ (1,0) [0|1] ""  External_Tool
 SG_ MRR_FL_SPI_FEE_Error : 14|1@0+ (1,0) [0|1] ""  External_Tool
 SG_ MRR_FL_SPI_Comm_Error : 13|1@0+ (1,0) [0|1] ""  External_Tool
 SG_ MRR_FL_Socket_Write_Error : 39|1@0+ (1,0) [0|1] ""  External_Tool
 SG_ MRR_FL_Socket_Read_error : 38|1@0+ (1,0) [0|1] ""  External_Tool
 SG_ MRR_FL_Socket_Init_Error : 37|1@0+ (1,0) [0|1] ""  External_Tool
 SG_ MRR_FL_Signal_Wait_Error : 4|1@0+ (1,0) [0|1] ""  External_Tool
 SG_ MRR_FL_Signal_Send_Error : 5|1@0+ (1,0) [0|1] ""  External_Tool
 SG_ MRR_FL_Signal_Create_Error : 3|1@0+ (1,0) [0|1] ""  External_Tool
 SG_ MRR_FL_Shared_Mem_Write_Error : 21|1@0+ (1,0) [0|1] ""  External_Tool
 SG_ MRR_FL_Shared_Mem_Read_Error : 20|1@0+ (1,0) [0|1] ""  External_Tool
 SG_ MRR_FL_Shared_Mem_Config_Error : 19|1@0+ (1,0) [0|1] ""  External_Tool
 SG_ MRR_FL_Share_Mem_Init_Error : 18|1@0+ (1,0) [0|1] ""  External_Tool
 SG_ MRR_FL_RAM_Test_Error : 1|1@0+ (1,0) [0|1] ""  External_Tool
 SG_ MRR_FL_Num_Errors : 63|1@0+ (1,0) [0|1] ""  External_Tool
 SG_ MRR_FL_MMAP_Memory_Error : 40|1@0+ (1,0) [0|1] ""  External_Tool
 SG_ MRR_FL_ISR_Attach_Error : 36|1@0+ (1,0) [0|1] ""  External_Tool
 SG_ MRR_FL_IPC_DRV_Write_Error : 29|1@0+ (1,0) [0|1] ""  External_Tool
 SG_ MRR_FL_IPC_DRV_Trigger_Error : 31|1@0+ (1,0) [0|1] ""  External_Tool
 SG_ MRR_FL_IPC_DRV_Sync_Error : 30|1@0+ (1,0) [0|1] ""  External_Tool
 SG_ MRR_FL_IPC_DRV_Read_Error : 28|1@0+ (1,0) [0|1] ""  External_Tool
 SG_ MRR_FL_IPC_DRV_Init_Error : 27|1@0+ (1,0) [0|1] ""  External_Tool
 SG_ MRR_FL_Interrupt_Enable_Error : 42|1@0+ (1,0) [0|1] ""  External_Tool
 SG_ MRR_FL_HIL_Format_Error : 41|1@0+ (1,0) [0|1] ""  External_Tool
 SG_ MRR_FL_Flash_Filesystem_Error : 7|1@0+ (1,0) [0|1] ""  External_Tool
 SG_ MRR_FL_Error_none : 0|1@0+ (1,0) [0|1] ""  External_Tool
 SG_ MRR_FL_Dsp_Load_Read_Error : 34|1@0+ (1,0) [0|1] ""  External_Tool
 SG_ MRR_FL_Dsp_Load_Open_Error : 33|1@0+ (1,0) [0|1] ""  External_Tool
 SG_ MRR_FL_Dsp_Load_Address_Error : 35|1@0+ (1,0) [0|1] ""  External_Tool
 SG_ MRR_FL_Dsp_ISP_Write_Error : 17|1@0+ (1,0) [0|1] ""  External_Tool
 SG_ MRR_FL_Dsp_IPC_Read_Error : 16|1@0+ (1,0) [0|1] ""  External_Tool
 SG_ MRR_FL_Dsp_IPC_Init : 15|1@0+ (1,0) [0|1] ""  External_Tool
 SG_ MRR_FL_Dsp_Init_Error : 32|1@0+ (1,0) [0|1] ""  External_Tool
 SG_ MRR_FL_Dsp_DRV_Start_Error : 26|1@0+ (1,0) [0|1] ""  External_Tool
 SG_ MRR_FL_Dsp_DRV_Load_Error : 25|1@0+ (1,0) [0|1] ""  External_Tool
 SG_ MRR_FL_Dsp_DRV_Init_Error : 22|1@0+ (1,0) [0|1] ""  External_Tool
 SG_ MRR_FL_Dsp_DRV_Init2_error : 24|1@0+ (1,0) [0|1] ""  External_Tool
 SG_ MRR_FL_Dsp_DRV_Init1_error : 23|1@0+ (1,0) [0|1] ""  External_Tool
 SG_ MRR_FL_CAN_XMT_Error : 10|1@0+ (1,0) [0|1] ""  External_Tool
 SG_ MRR_FL_CAN_RCV_Error : 11|1@0+ (1,0) [0|1] ""  External_Tool
 SG_ MRR_FL_CAN_Hardware_Error : 12|1@0+ (1,0) [0|1] ""  External_Tool
 SG_ MRR_FL_Always_True : 62|1@0+ (1,0) [0|1] ""  External_Tool

BO_ 392 MRR_FL_Header_SensorCoverage: 12 MRRFL
 SG_ MRR_FL_Radar_Spec_Status_MC : 75|4@0+ (1,0) [0|15] ""  External_Tool,CADM
 SG_ MRR_FL_Radar_Spec_Status_CRC : 87|16@0+ (1,0) [0|65535] ""  CADM,External_Tool
 SG_ MRR_CAN_RadarWaveform_FL : 79|3@0+ (1,0) [0|7] ""  CADM,External_Tool
 SG_ MRR_FL_CAN_RANGE_COVERAGE : 7|14@0+ (0.015625,0) [0|255.984375] "m"  External_Tool,CADM
 SG_ MRR_FL_CAN_DOPPLER_COVERAGE : 23|14@0+ (0.015625,0) [0|255.984375] "m/s"  External_Tool,CADM
 SG_ MRR_FL_CAN_FOV_HOR : 39|8@0+ (1,0) [0|255] "deg"  External_Tool,CADM
 SG_ MRR_FL_CAN_FOV_VER : 47|8@0+ (1,0) [0|255] "deg"  External_Tool,CADM

BO_ 397 MRR_FL_Status_Temp_Volt: 12 MRRFL
 SG_ MRR_FL_CAN_Dolphin_AFC : 95|8@0+ (1,-50) [-50|205] "C"  CADM,External_Tool
 SG_ MRR_FL_CAN_Dolphin_Tx3 : 87|8@0+ (1,-50) [-50|205] "C"  CADM,External_Tool
 SG_ MRR_FL_CAN_Dolphin_Tx2 : 79|8@0+ (1,-50) [-50|205] "C"  CADM,External_Tool
 SG_ MRR_FL_CAN_1_8_V : 71|8@0+ (0.08,0) [0|20.4] "V"  External_Tool
 SG_ MRR_FL_CAN_BATT_VOLTS : 63|8@0+ (0.08,0) [0|20.4] "V"  External_Tool
 SG_ MRR_FL_CAN_1_25_V : 55|8@0+ (0.08,0) [0|20.4] "V"  External_Tool
 SG_ MRR_FL_CAN_5_V : 47|8@0+ (0.08,0) [0|20.4] "V"  External_Tool
 SG_ MRR_FL_CAN_1_1_V : 31|8@0+ (0.08,0) [0|20.4] "V"  External_Tool
 SG_ MRR_FL_CAN_2_3_V : 15|8@0+ (0.08,0) [0|20.4] "V"  External_Tool
 SG_ MRR_FL_CAN_Dolphin_Tx1 : 39|8@0+ (1,-50) [-50|205] "C"  CADM,External_Tool
 SG_ MRR_FL_CAN_RRU_Temp1 : 7|8@0+ (1,-50) [-50|205] "C"  CADM,External_Tool

BO_ 448 MRR_FR_Veh_Sig_Status: 8 MRRFR
 SG_ MRR_FR_CAN_TX_VEH_SPEED_DIRECTIO : 32|1@0+ (1,0) [0|1] ""  CADM
 SG_ MRR_FR_CAN_TX_RADIUS_CURVATURE : 47|8@0- (25,0) [-3200|3175] "m"  CADM
 SG_ MRR_FR_CAN_TX_STEERING_ANGLE_SIG : 55|1@0+ (1,0) [0|1] ""  CADM
 SG_ MRR_FR_CAN_TX_STEERING_ANGLE : 54|15@0+ (1,0) [0|32767] "deg"  CADM
 SG_ MRR_FR_CAN_TX_YAW_RATE_CALC : 28|12@0- (0.0625,0) [-128|127.9375] "deg/s"  CADM
 SG_ MRR_FR_CAN_TX_VEHICLE_SPEED_CALC : 23|11@0+ (0.0625,0) [0|127.9375] "m/s"  CADM
 SG_ MRR_FR_CAN_TX_SCAN_INDEX : 7|16@0+ (1,0) [0|65535] ""  CADM

BO_ 449 MRR_FR_HW_Version_Status: 64 MRRFR
 SG_ MRR_FR_Dolphin_Chip_ID_Part2 : 327|64@0+ (1,0) [0|1.84467440737096E+019] ""  CADM,External_Tool
 SG_ MRR_FR_Dolphin_Chip_ID_Part1 : 263|64@0+ (1,0) [0|1.84467440737096E+019] ""  CADM,External_Tool
 SG_ MRR_FR_RRU_Chip_ID_Part4 : 199|64@0+ (1,0) [0|1.84467440737096E+019] ""  CADM,External_Tool
 SG_ MRR_FR_RRU_Chip_ID_Part3 : 135|64@0+ (1,0) [0|1.84467440737096E+019] ""  CADM,External_Tool
 SG_ MRR_FR_RRU_Chip_ID_Part2 : 71|64@0+ (1,0) [0|1.84467440737096E+019] ""  CADM,External_Tool
 SG_ MRR_FR_RRU_Chip_ID_Part1 : 7|64@0+ (1,0) [0|1.84467440737096E+019] ""  CADM,External_Tool
 SG_ MRR_FR_CAN_TX_HW_VERSION : 391|4@0+ (1,0) [0|15] ""  CADM,External_Tool

BO_ 450 MRR_FR_SW_Version_Status: 48 MRRFR
 SG_ MRR_FR_CAN_PCAN_PROTOCOL_PROMOTE : 263|8@0+ (1,0) [0|255] ""  CADM,External_Tool
 SG_ MRR_FR_CAN_TX_SW_VERSION_DSP : 295|24@0+ (1,0) [0|16777215] ""  External_Tool,CADM
 SG_ MRR_FR_CAN_TX_SW_VERSION_ARM : 271|24@0+ (1,0) [0|16777215] ""  External_Tool,CADM
 SG_ MRR_FR_CAN_TX_PCAN_PROTOCOL_MINO : 243|8@0+ (1,0) [0|255] ""  External_Tool,CADM
 SG_ MRR_FR_CAN_TX_PCAN_PROTOCOL_MAJO : 247|4@0+ (1,0) [0|15] ""  External_Tool,CADM
 SG_ MRR_FR_CAN_Dyn_Align_Algorithm_V : 223|8@0+ (1,0) [0|255] ""  External_Tool,CADM
 SG_ MRR_FR_CAN_Dyn_Align_Algori_0000 : 231|8@0+ (1,0) [0|255] ""  External_Tool,CADM
 SG_ MRR_FR_CAN_Dyn_Align_Algori_0001 : 239|8@0+ (1,0) [0|255] ""  External_Tool,CADM
 SG_ MRR_FR_Core_Radar_BB_Version_Fie : 215|8@0+ (1,0) [0|255] ""  CADM
 SG_ MRR_FR_Core_Radar_BB_Version_Pro : 207|8@0+ (1,0) [0|255] ""  CADM
 SG_ MRR_FR_Core_Radar_BB_Version_Min : 199|8@0+ (1,0) [0|255] ""  CADM
 SG_ MRR_FR_Core_Radar_BB_Version_Maj : 191|8@0+ (1,0) [0|255] ""  CADM
 SG_ MRR_FR_CAN_USC_Field : 183|8@0+ (1,0) [0|255] ""  CADM
 SG_ MRR_FR_CAN_USC_Promote : 175|8@0+ (1,0) [0|255] ""  CADM
 SG_ MRR_FR_CAN_USC_Minor : 167|8@0+ (1,0) [0|255] ""  CADM
 SG_ MRR_FR_CAN_USC_Major : 159|8@0+ (1,0) [0|255] ""  CADM
 SG_ MRR_FR_CAN_SMC_Field : 151|8@0+ (1,0) [0|255] ""  CADM
 SG_ MRR_FR_CAN_SMC_Promote : 143|8@0+ (1,0) [0|255] ""  CADM
 SG_ MRR_FR_CAN_SMC_Minor : 135|8@0+ (1,0) [0|255] ""  CADM
 SG_ MRR_FR_CAN_SMC_Major : 127|8@0+ (1,0) [0|255] ""  CADM
 SG_ MRR_FR_CAN_TX_Field : 23|8@0+ (1,0) [0|255] ""  CADM
 SG_ MRR_FR_CAN_TX_Promote : 13|6@0+ (1,0) [0|63] ""  CADM
 SG_ MRR_FR_CAN_TX_Major : 3|6@0+ (1,0) [0|63] ""  CADM
 SG_ MRR_FR_CAN_TX_Hardware : 7|4@0+ (1,0) [0|15] ""  CADM
 SG_ MRR_FR_CAN_TX_SERIAL_NUMBER_SEQU : 35|12@0+ (1,0) [0|4095] ""  CADM
 SG_ MRR_FR_CAN_TX_SERIAL_NUM_JULIAN_ : 38|3@0+ (1,2014) [2014|2021] ""  CADM
 SG_ MRR_FR_CAN_TX_SERIAL_NUM_JU_0000 : 31|9@0+ (1,0) [0|511] ""  CADM
 SG_ MRR_FR_CAN_TX_ARM_THROUGHPUT : 63|5@0+ (3.2258,0) [0|99.9998] ""  CADM
 SG_ MRR_FR_CAN_TX_SYSTEM_STATUS : 58|3@0+ (1,0) [0|7] ""  CADM
 SG_ MRR_FR_CAN_TX_LOOK_TYPE_1 : 50|1@0+ (1,0) [0|1] ""  CADM
 SG_ MRR_FR_CAN_TX_OVERHEAT_ERROR : 51|1@0+ (1,0) [0|1] ""  CADM
 SG_ MRR_FR_CAN_TX_RANGE_PERF_ERROR : 52|1@0+ (1,0) [0|1] ""  CADM
 SG_ MRR_FR_CAN_TX_COMM_ERROR : 53|1@0+ (1,0) [0|1] ""  CADM
 SG_ MRR_FR_CAN_TX_INTERNAL_ERROR : 54|1@0+ (1,0) [0|1] ""  CADM
 SG_ MRR_FR_CAN_TX_XCVR_OPERATIONAL : 55|1@0+ (1,0) [0|1] ""  CADM
 SG_ MRR_FR_CAN_PBL_Field_Revision : 119|8@0+ (1,0) [0|255] ""  CADM
 SG_ MRR_FR_CAN_PBL_Promote_Revision : 111|8@0+ (1,0) [0|255] ""  CADM
 SG_ MRR_FR_CAN_SW_Field_Revision : 87|8@0+ (1,0) [0|255] ""  CADM
 SG_ MRR_FR_CAN_SW_Promote_Revision : 79|8@0+ (1,0) [0|255] ""  CADM
 SG_ MRR_FR_CAN_SW_Field : 95|8@0+ (1,0) [0|255] ""  CADM
 SG_ MRR_FR_CAN_SW_Release_Revision : 71|8@0+ (1,0) [0|255] ""  CADM
 SG_ MRR_FR_CAN_PBL_Release_Revision : 103|8@0+ (1,0) [0|255] ""  CADM

BO_ 451 MRR_FR_Alignment_Status: 12 MRRFR
 SG_ MRR_FR_Alignment_Status_CRC : 87|16@0+ (1,0) [0|65535] ""  CADM
 SG_ MRR_FR_Alignment_Status_MC : 75|4@0+ (1,0) [0|15] ""  CADM
 SG_ MRR_FR_CAN_TX_DRIVING_ENVIRONMEN : 41|2@0+ (1,0) [0|3] ""  CADM
 SG_ MRR_FR_CAN_TX_ROLLING_COUNT_1 : 33|2@0+ (1,0) [0|3] ""  CADM
 SG_ MRR_FR_CAN_TX_Temperature : 63|8@0+ (1,-50) [-50|205] "degC"  CADM
 SG_ MRR_FR_CAN_TX_YAW_RATE_BIAS : 55|8@0- (0.125,0) [-16|15.875] ""  CADM
 SG_ MRR_FR_CAN_TX_VEH_SPD_COMP_FACTO : 47|6@0- (0.001953125,1) [0.9375|1.060546875] ""  CADM
 SG_ MRR_FR_CAN_TX_AUTO_ALIGN_QUA_FAC : 35|2@0+ (1,0) [0|3] ""  CADM
 SG_ MRR_FR_CAN_TX_Alignment_MODE : 39|4@0+ (1,0) [0|15] ""  CADM
 SG_ MRR_FR_CAN_TX_CURRENT_MISALIGN_A : 23|16@0- (0.0009765625,0) [-32|31.9990234375] "Deg"  CADM
 SG_ MRR_FR_CAN_TX_SAVED_MISALIGN_ANG : 7|16@0- (0.0009765625,0) [-32|31.9990234375] "Deg"  CADM

BO_ 452 MRR_FR_Active_Fault_Status: 20 MRRFR
 SG_ MRR_FR_TO_SystemTDBlockage_Flt : 87|1@0+ (1,0) [0|1] ""  CADM
 SG_ MRR_FR_TO_CADMSWVersion_Flt : 95|1@0+ (1,0) [0|1] ""  CADM
 SG_ MRR_FR_TO_RADARCfgParameter_Flt : 94|1@0+ (1,0) [0|1] ""  CADM
 SG_ MRR_FR_TO_SATCADMVIN_Flt : 93|1@0+ (1,0) [0|1] ""  CADM
 SG_ MRR_FR_TO_CADMTracksChange_Flt : 92|1@0+ (1,0) [0|1] ""  CADM
 SG_ MRR_FR_Active_Fault_Status_CRC : 151|16@0+ (1,0) [0|65535] ""  CADM
 SG_ MRR_FR_Active_Fault_Status_MC : 139|4@0+ (1,0) [0|15] ""  CADM
 SG_ MRR_FR_Dolphin_Flt : 71|1@0+ (1,0) [0|1] ""  CADM
 SG_ MRR_FR_RRUCore_Flt : 70|1@0+ (1,0) [0|1] ""  CADM
 SG_ MRR_FR_RRUBIST_Flt : 72|1@0+ (1,0) [0|1] ""  CADM
 SG_ MRR_FR_PINPosition_Flt : 69|1@0+ (1,0) [0|1] ""  CADM
 SG_ MRR_FR_PCANDataRangeChk_Flt : 68|1@0+ (1,0) [0|1] ""  CADM
 SG_ MRR_FR_TO_AngleAdjustmentTable_F : 88|1@0+ (1,0) [0|1] ""  CADM
 SG_ MRR_FR_TO_CADMSgnlActlVal_Flt : 86|1@0+ (1,0) [0|1] ""  CADM
 SG_ MRR_FR_TO_TrigControl_Flt : 85|1@0+ (1,0) [0|1] ""  CADM
 SG_ MRR_FR_TO_VehicleState_Flt : 84|1@0+ (1,0) [0|1] ""  CADM
 SG_ MRR_FR_MC_AngleAdjTable_Flt : 83|1@0+ (1,0) [0|1] ""  CADM
 SG_ MRR_FR_CRC_AngleAdjTable_Flt : 82|1@0+ (1,0) [0|1] ""  CADM
 SG_ MRR_FR_MC_VehicleState_Flt : 81|1@0+ (1,0) [0|1] ""  CADM
 SG_ MRR_FR_CRC_VehicleState_Flt : 80|1@0+ (1,0) [0|1] ""  CADM
 SG_ MRR_FR_MC_TrigControl_Flt : 79|1@0+ (1,0) [0|1] ""  CADM
 SG_ MRR_FR_CRC_TrigControl_Flt : 78|1@0+ (1,0) [0|1] ""  CADM
 SG_ MRR_FR_CRC_RadarCfgParameter_Flt : 75|1@0+ (1,0) [0|1] ""  CADM
 SG_ MRR_FR_MC_CADMSgnlActlVal_Flt : 74|1@0+ (1,0) [0|1] ""  CADM
 SG_ MRR_FR_CRC_CADMSgnlActlVal_Flt : 73|1@0+ (1,0) [0|1] ""  CADM
 SG_ MRR_FR_VINSignalCompare_Flt : 66|1@0+ (1,0) [0|1] ""  CADM
 SG_ MRR_FR_BatteryLow_Flt : 63|1@0+ (1,0) [0|1] ""  CADM
 SG_ MRR_FR_BatteryHigh_Flt : 62|1@0+ (1,0) [0|1] ""  CADM
 SG_ MRR_FR_Core0_To_Core1_IPC_Flt : 60|1@0+ (1,0) [0|1] ""  CADM
 SG_ MRR_FR_Core1_To_Core0_IPC_Flt : 61|1@0+ (1,0) [0|1] ""  CADM
 SG_ MRR_FR_Core1_To_Core2_IPC_Flt : 59|1@0+ (1,0) [0|1] ""  CADM
 SG_ MRR_FR_Core2_To_Core1_IPC_Flt : 58|1@0+ (1,0) [0|1] ""  CADM
 SG_ MRR_FR_Core2_To_Core0_IPC_Flt : 57|1@0+ (1,0) [0|1] ""  CADM
 SG_ MRR_FR_Core2Halted_Flt : 19|1@0+ (1,0) [0|1] ""  CADM
 SG_ MRR_FR_Core1Halted_Flt : 18|1@0+ (1,0) [0|1] ""  CADM
 SG_ MRR_FR_LocalOscPower_Flt : 50|1@0+ (1,0) [0|1] ""  CADM
 SG_ MRR_FR_DSPLoopOverrun_Flt : 54|1@0+ (1,0) [0|1] ""  CADM
 SG_ MRR_FR_TransmitterPower_Flt : 49|1@0+ (1,0) [0|1] ""  CADM
 SG_ MRR_FR_Core0_To_Core2_IPC_Flt : 56|1@0+ (1,0) [0|1] ""  CADM
 SG_ MRR_FR_XCVRDeviceSPI_Flt : 45|1@0+ (1,0) [0|1] ""  CADM
 SG_ MRR_FR_MNRBlockage_Flt : 40|1@0+ (1,0) [0|1] ""  CADM
 SG_ MRR_FR_TransmitterTempHigh_Flt : 38|1@0+ (1,0) [0|1] ""  CADM
 SG_ MRR_FR_AlignRoutineFailed_Flt : 37|1@0+ (1,0) [0|1] ""  CADM
 SG_ MRR_FR_MicroTempHigh_Flt : 35|1@0+ (1,0) [0|1] ""  CADM
 SG_ MRR_FR_HAlignOutofRange_Flt : 33|1@0+ (1,0) [0|1] ""  CADM
 SG_ MRR_FR_v1p1_SupplyOutOfRange_Flt : 30|1@0+ (1,0) [0|1] ""  CADM
 SG_ MRR_FR_v1p25_SupplyOutOfRange_Fl : 29|1@0+ (1,0) [0|1] ""  CADM
 SG_ MRR_FR_v1p8_SupplyOutOfRange_Flt : 28|1@0+ (1,0) [0|1] ""  CADM
 SG_ MRR_FR_v2p3_SupplyOutOfRange_Flt : 27|1@0+ (1,0) [0|1] ""  CADM
 SG_ MRR_FR_v_5_SupplyOutOfRange_Flt : 24|1@0+ (1,0) [0|1] ""  CADM
 SG_ MRR_FR_TransmitterID_Flt : 23|1@0+ (1,0) [0|1] ""  CADM
 SG_ MRR_FR_PCANBusOff_Flt : 16|1@0+ (1,0) [0|1] ""  CADM
 SG_ MRR_FR_InstructionSetCheck_Flt : 13|1@0+ (1,0) [0|1] ""  CADM
 SG_ MRR_FR_StackOverflow_Flt : 12|1@0+ (1,0) [0|1] ""  CADM
 SG_ MRR_FR_Watchdog_Flt : 11|1@0+ (1,0) [0|1] ""  CADM
 SG_ MRR_FR_PLLLock_Flt : 10|1@0+ (1,0) [0|1] ""  CADM
 SG_ MRR_FR_RAMMemoryTest_Flt : 8|1@0+ (1,0) [0|1] ""  CADM
 SG_ MRR_FR_USCValidation_Flt : 7|1@0+ (1,0) [0|1] ""  CADM
 SG_ MRR_FR_SMCChecksum_Flt : 4|1@0+ (1,0) [0|1] ""  CADM
 SG_ MRR_FR_KeepAliveChecksum_Flt : 2|1@0+ (1,0) [0|1] ""  CADM
 SG_ MRR_FR_ApplicationFlashChksum_Fl : 0|1@0+ (1,0) [0|1] ""  CADM

BO_ 453 MRR_FR_Error_Status: 32 MRRFR
 SG_ MRR_FR_XBAR_cfg_failure : 255|1@0+ (1,0) [0|1] ""  External_Tool
 SG_ MRR_FR_Stack_OVF_fault_reason : 247|3@0+ (1,0) [0|7] ""  External_Tool
 SG_ MRR_FR_App_flash_checksum_reason : 244|3@0+ (1,0) [0|7] ""  External_Tool
 SG_ MRR_FR_KAM_fault_reason : 241|2@0+ (1,0) [0|3] ""  External_Tool
 SG_ MRR_FR_RRU_Self_Test_Faults_reas : 239|8@0+ (1,0) [0|255] ""  External_Tool
 SG_ MRR_FR_RRU_Core_Faults_reason3 : 231|8@0+ (1,0) [0|255] ""  External_Tool
 SG_ MRR_FR_RRU_Core_Faults_reason2 : 167|64@0+ (1,0) [0|1.84467440737096E+019] ""  External_Tool
 SG_ MRR_FR_RRU_Core_Faults_reason1 : 103|64@0+ (1,0) [0|1.84467440737096E+019] ""  External_Tool
 SG_ MRR_FR_Rx_Radar_Mount_Msg_Fault : 88|1@0+ (1,0) [0|1] ""  External_Tool
 SG_ MRR_FR_Dolphin_Fault_Detection : 87|8@0+ (1,0) [0|63] ""  External_Tool
 SG_ MRR_FR_RRU_Self_Test_Faults_0000 : 79|8@0+ (1,0) [0|255] ""  External_Tool
 SG_ MRR_FR_RRU_Core_Faults_reason0 : 71|8@0+ (1,0) [0|255] ""  External_Tool
 SG_ MRR_FR_USC_Load_Error : 59|1@0+ (1,0) [0|1] ""  External_Tool
 SG_ MRR_FR_SMC_Load_Error : 58|1@0+ (1,0) [0|1] ""  External_Tool
 SG_ MRR_FR_TX_Temperature_Flt : 57|1@0+ (1,0) [0|1] ""  External_Tool
 SG_ MRR_FR_Dsp_Unit_Cal_Blk_Chcksm_E : 56|1@0+ (1,0) [0|1] ""  External_Tool
 SG_ MRR_FR_Dsp_Unit_Cal_Checksum_Err : 55|1@0+ (1,0) [0|1] ""  External_Tool
 SG_ MRR_FR_Vertical_Misalignment_err : 54|1@0+ (1,0) [0|1] ""  External_Tool
 SG_ MRR_FR_RTN_SPI_Transfer_Error : 53|1@0+ (1,0) [0|1] ""  External_Tool
 SG_ MRR_FR_RRN_SPI_Transfer_Error : 52|1@0+ (1,0) [0|1] ""  External_Tool
 SG_ MRR_FR_Linearizer_SPI_Transfer_E : 51|1@0+ (1,0) [0|1] ""  External_Tool
 SG_ MRR_FR_ADC_SPI_Transfer_Error : 50|1@0+ (1,0) [0|1] ""  External_Tool
 SG_ MRR_FR_Transmitter_ID_Error : 49|1@0+ (1,0) [0|1] ""  External_Tool
 SG_ MRR_FR_Dsp_Loop_Overrun_Error : 48|1@0+ (1,0) [0|1] ""  External_Tool
 SG_ MRR_FR_Saturated_Tuning_Freq_Err : 47|1@0+ (1,0) [0|1] ""  External_Tool
 SG_ MRR_FR_Radar_Data_sync_error : 46|1@0+ (1,0) [0|1] ""  External_Tool
 SG_ MRR_FR_Dsp_Tuning_Sensitivity_Er : 45|1@0+ (1,0) [0|1] ""  External_Tool
 SG_ MRR_FR_Radar_LO_Power_Error : 44|1@0+ (1,0) [0|1] ""  External_Tool
 SG_ MRR_FR_Radar_TX_Power_Error : 43|1@0+ (1,0) [0|1] ""  External_Tool
 SG_ MRR_FR_Timer_Create_Error : 6|1@0+ (1,0) [0|1] ""  External_Tool
 SG_ MRR_FR_Thread_Create_Error : 2|1@0+ (1,0) [0|1] ""  External_Tool
 SG_ MRR_FR_ARM_Calibration_Error : 9|1@0+ (1,0) [0|1] ""  External_Tool
 SG_ MRR_FR_SPI_FEE_Error : 14|1@0+ (1,0) [0|1] ""  External_Tool
 SG_ MRR_FR_SPI_Comm_Error : 13|1@0+ (1,0) [0|1] ""  External_Tool
 SG_ MRR_FR_Socket_Write_Error : 39|1@0+ (1,0) [0|1] ""  External_Tool
 SG_ MRR_FR_Socket_Read_error : 38|1@0+ (1,0) [0|1] ""  External_Tool
 SG_ MRR_FR_Socket_Init_Error : 37|1@0+ (1,0) [0|1] ""  External_Tool
 SG_ MRR_FR_Signal_Wait_Error : 4|1@0+ (1,0) [0|1] ""  External_Tool
 SG_ MRR_FR_Signal_Send_Error : 5|1@0+ (1,0) [0|1] ""  External_Tool
 SG_ MRR_FR_Signal_Create_Error : 3|1@0+ (1,0) [0|1] ""  External_Tool
 SG_ MRR_FR_Shared_Mem_Write_Error : 21|1@0+ (1,0) [0|1] ""  External_Tool
 SG_ MRR_FR_Shared_Mem_Read_Error : 20|1@0+ (1,0) [0|1] ""  External_Tool
 SG_ MRR_FR_Shared_Mem_Config_Error : 19|1@0+ (1,0) [0|1] ""  External_Tool
 SG_ MRR_FR_Share_Mem_Init_Error : 18|1@0+ (1,0) [0|1] ""  External_Tool
 SG_ MRR_FR_RAM_Test_Error : 1|1@0+ (1,0) [0|1] ""  External_Tool
 SG_ MRR_FR_Num_Errors : 63|1@0+ (1,0) [0|1] ""  External_Tool
 SG_ MRR_FR_MMAP_Memory_Error : 40|1@0+ (1,0) [0|1] ""  External_Tool
 SG_ MRR_FR_ISR_Attach_Error : 36|1@0+ (1,0) [0|1] ""  External_Tool
 SG_ MRR_FR_IPC_DRV_Write_Error : 29|1@0+ (1,0) [0|1] ""  External_Tool
 SG_ MRR_FR_IPC_DRV_Trigger_Error : 31|1@0+ (1,0) [0|1] ""  External_Tool
 SG_ MRR_FR_IPC_DRV_Sync_Error : 30|1@0+ (1,0) [0|1] ""  External_Tool
 SG_ MRR_FR_IPC_DRV_Read_Error : 28|1@0+ (1,0) [0|1] ""  External_Tool
 SG_ MRR_FR_IPC_DRV_Init_Error : 27|1@0+ (1,0) [0|1] ""  External_Tool
 SG_ MRR_FR_Interrupt_Enable_Error : 42|1@0+ (1,0) [0|1] ""  External_Tool
 SG_ MRR_FR_HIL_Format_Error : 41|1@0+ (1,0) [0|1] ""  External_Tool
 SG_ MRR_FR_Flash_Filesystem_Error : 7|1@0+ (1,0) [0|1] ""  External_Tool
 SG_ MRR_FR_Error_none : 0|1@0+ (1,0) [0|1] ""  External_Tool
 SG_ MRR_FR_Dsp_Load_Read_Error : 34|1@0+ (1,0) [0|1] ""  External_Tool
 SG_ MRR_FR_Dsp_Load_Open_Error : 33|1@0+ (1,0) [0|1] ""  External_Tool
 SG_ MRR_FR_Dsp_Load_Address_Error : 35|1@0+ (1,0) [0|1] ""  External_Tool
 SG_ MRR_FR_Dsp_ISP_Write_Error : 17|1@0+ (1,0) [0|1] ""  External_Tool
 SG_ MRR_FR_Dsp_IPC_Read_Error : 16|1@0+ (1,0) [0|1] ""  External_Tool
 SG_ MRR_FR_Dsp_IPC_Init : 15|1@0+ (1,0) [0|1] ""  External_Tool
 SG_ MRR_FR_Dsp_Init_Error : 32|1@0+ (1,0) [0|1] ""  External_Tool
 SG_ MRR_FR_Dsp_DRV_Start_Error : 26|1@0+ (1,0) [0|1] ""  External_Tool
 SG_ MRR_FR_Dsp_DRV_Load_Error : 25|1@0+ (1,0) [0|1] ""  External_Tool
 SG_ MRR_FR_Dsp_DRV_Init_Error : 22|1@0+ (1,0) [0|1] ""  External_Tool
 SG_ MRR_FR_Dsp_DRV_Init2_error : 24|1@0+ (1,0) [0|1] ""  External_Tool
 SG_ MRR_FR_Dsp_DRV_Init1_error : 23|1@0+ (1,0) [0|1] ""  External_Tool
 SG_ MRR_FR_CAN_XMT_Error : 10|1@0+ (1,0) [0|1] ""  External_Tool
 SG_ MRR_FR_CAN_RCV_Error : 11|1@0+ (1,0) [0|1] ""  External_Tool
 SG_ MRR_FR_CAN_Hardware_Error : 12|1@0+ (1,0) [0|1] ""  External_Tool
 SG_ MRR_FR_Always_True : 62|1@0+ (1,0) [0|1] ""  External_Tool

CM_ "CAN bus that communicates the Short Range Radars with CADM";
BA_DEF_ SG_  "NWM_WakeupAllowed" ENUM  "0 No","1 Yes";
BA_DEF_ BO_  "GenMsgTimeoutTime" INT 0 2500;
BA_DEF_ BO_  "WakeupMessage" ENUM  "0 No","1 Yes";
BA_DEF_ BU_  "NmNodeType" ENUM  "0 Master","1 Slave15","2 Slave30","3 None";
BA_DEF_  "NmAsrBaseAddress" HEX 1280 1343;
BA_DEF_ SG_  "SignalDescription" STRING ;
BA_DEF_ SG_  "GenSigTimeoutTime_ABS_ESC" INT 0 100000;
BA_DEF_ SG_  "UsedOnPgmDBC" ENUM  "No","Yes";
BA_DEF_ BU_  "IL" ENUM  "No","Yes";
BA_DEF_  "VersionNumber_B" STRING ;
BA_DEF_ BU_  "NodeLayerModules" STRING ;
BA_DEF_ BO_  "VFrameFormat" ENUM  "StandardCAN","ExtendedCAN","reserved","reserved","reserved","reserved","reserved","reserved","reserved","reserved","reserved","reserved","reserved","reserved","StandardCAN_FD","ExtendedCAN_FD";
BA_DEF_ BO_  "DiagConnection" INT 0 65535;
BA_DEF_ BO_  "CanTpBs" INT 0 255;
BA_DEF_ BO_  "EventRateOfChange" INT 10 10000;
BA_DEF_ BO_  "DiagState" ENUM  "No","Yes";
BA_DEF_ BO_  "DiagRequest" ENUM  "No","Yes";
BA_DEF_ BO_  "DiagResponse" ENUM  "No","Yes";
BA_DEF_ BU_  "NmNode" ENUM  "Yes";
BA_DEF_ BU_  "TpOwnSystemEcuNumber" HEX 0 255;
BA_DEF_  "NetworkSpeed" ENUM  "500kBits/s","125kBit/s","2MBits/s";
BA_DEF_  "NmAsrMessageCount" INT 1 256;
BA_DEF_  "VersionDay" INT 1 31;
BA_DEF_  "Manufacturer" STRING ;
BA_DEF_  "VersionMonth" INT 1 12;
BA_DEF_  "VersionYear" INT 2000 3000;
BA_DEF_ SG_  "GenSigCycleTime" INT 0 0;
BA_DEF_ SG_  "GenSigVtName" STRING ;
BA_DEF_ SG_  "GenSigVtEn" STRING ;
BA_DEF_  "GenNetworkMuxEn" STRING ;
BA_DEF_  "GenNetworkBaudrate" STRING ;
BA_DEF_  "GenNetworkName" STRING ;
BA_DEF_ SG_  "GenSigCmt" STRING ;
BA_DEF_  "GenRevisionDate" STRING ;
BA_DEF_  "GenRevision" STRING ;
BA_DEF_  "GenDescription" STRING ;
BA_DEF_  "GenCompany" STRING ;
BA_DEF_  "GenAuthor" STRING ;
BA_DEF_ SG_  "GenSigSendType" ENUM  "Cyclic","OnWrite","vector_leerstring","OnChange","vector_leerstring","IfActive","vector_leerstring","NoSigSendType";
BA_DEF_ SG_  "GenSigInactiveValue" INT 0 100000;
BA_DEF_ SG_  "GenSigMissingSourceValue" INT 0 1000000000;
BA_DEF_ SG_  "GenSigStartValue" INT 0 1000000000;
BA_DEF_ BO_  "GenMsgILSupport" ENUM  "No","Yes";
BA_DEF_ BO_  "GenMsgSendType" ENUM  "FixedPeriodic","Event","EnabledPeriodic","NotUsed","NotUsed","EventPeriodic","NotUsed","NotUsed","NoMsgSendType";
BA_DEF_ BO_  "GenMsgCycleTime" INT 0 100000;
BA_DEF_ BO_  "GenMsgNrOfRepetition" INT 0 100;
BA_DEF_ BU_  "PowerType" ENUM  "Switched","Latched","Sleep","vector_leerstring","vector_leerstring";
BA_DEF_ BU_  "NodeStartUpTime" INT 0 10000;
BA_DEF_ BU_  "NodeWakeUpTime" INT 0 10000;
BA_DEF_  "DBName" STRING ;
BA_DEF_  "BusType" STRING ;
BA_DEF_ SG_  "SystemSignalLongSymbol" STRING ;
BA_DEF_DEF_  "NWM_WakeupAllowed" "0 No";
BA_DEF_DEF_  "GenMsgTimeoutTime" 2500;
BA_DEF_DEF_  "WakeupMessage" "0 No";
BA_DEF_DEF_  "NmNodeType" "3 None";
BA_DEF_DEF_  "NmAsrBaseAddress" 1280;
BA_DEF_DEF_  "SignalDescription" "";
BA_DEF_DEF_  "GenSigTimeoutTime_ABS_ESC" 0;
BA_DEF_DEF_  "UsedOnPgmDBC" "Yes";
BA_DEF_DEF_  "IL" "Yes";
BA_DEF_DEF_  "VersionNumber_B" "B_1";
BA_DEF_DEF_  "NodeLayerModules" "CANoeILNLFiat.dll";
BA_DEF_DEF_  "VFrameFormat" "StandardCAN_FD";
BA_DEF_DEF_  "DiagConnection" 0;
BA_DEF_DEF_  "CanTpBs" 255;
BA_DEF_DEF_  "EventRateOfChange" 10000;
BA_DEF_DEF_  "DiagState" "No";
BA_DEF_DEF_  "DiagRequest" "No";
BA_DEF_DEF_  "DiagResponse" "No";
BA_DEF_DEF_  "NmNode" "Yes";
BA_DEF_DEF_  "TpOwnSystemEcuNumber" 0;
BA_DEF_DEF_  "NetworkSpeed" "2MBits/s";
BA_DEF_DEF_  "NmAsrMessageCount" 256;
BA_DEF_DEF_  "VersionDay" 29;
BA_DEF_DEF_  "Manufacturer" "FCA";
BA_DEF_DEF_  "VersionMonth" 6;
BA_DEF_DEF_  "VersionYear" 2020;
BA_DEF_DEF_  "GenSigCycleTime" 0;
BA_DEF_DEF_  "GenSigVtName" "";
BA_DEF_DEF_  "GenSigVtEn" "";
BA_DEF_DEF_  "GenNetworkMuxEn" "FALSE";
BA_DEF_DEF_  "GenNetworkBaudrate" "500 kbps";
BA_DEF_DEF_  "GenNetworkName" "CADM_PCAN_SB2";
BA_DEF_DEF_  "GenSigCmt" "";
BA_DEF_DEF_  "GenRevisionDate" "29th June 2020";
BA_DEF_DEF_  "GenRevision" "v07.01.00";
BA_DEF_DEF_  "GenDescription" "SB2 CAN bus that supports communication between Radars and CADM Lo";
BA_DEF_DEF_  "GenCompany" "APTIV";
BA_DEF_DEF_  "GenAuthor" "Pradyumna Vasudevan";
BA_DEF_DEF_  "GenSigSendType" "NoSigSendType";
BA_DEF_DEF_  "GenSigInactiveValue" 0;
BA_DEF_DEF_  "GenSigMissingSourceValue" 0;
BA_DEF_DEF_  "GenSigStartValue" 0;
BA_DEF_DEF_  "GenMsgILSupport" "Yes";
BA_DEF_DEF_  "GenMsgSendType" "NoMsgSendType";
BA_DEF_DEF_  "GenMsgCycleTime" 0;
BA_DEF_DEF_  "GenMsgNrOfRepetition" 0;
BA_DEF_DEF_  "PowerType" "Switched";
BA_DEF_DEF_  "NodeStartUpTime" 250;
BA_DEF_DEF_  "NodeWakeUpTime" 10;
BA_DEF_DEF_  "DBName" "";
BA_DEF_DEF_  "BusType" "CAN FD";
BA_DEF_DEF_  "SystemSignalLongSymbol" "";
BA_ "GenRevision" "v07.02.01";
BA_ "VersionMonth" 9;
BA_ "VersionYear" 2021;
BA_ "GenCompany" "Aptiv";
BA_ "GenDescription" "The CAN that communicates  data between Corner Radars and CADM";
BA_ "GenNetworkBaudrate" "500000";
BA_ "VersionDay" 13;
BA_ "GenRevisionDate" "September 13th 2021";
BA_ "GenAuthor" "Victor M. Gonzalez";
BA_ "DBName" "CADM_PCAN_SB2";
BA_ "GenMsgTimeoutTime" BO_ 680 0;
BA_ "GenMsgCycleTime" BO_ 680 100;
BA_ "GenMsgSendType" BO_ 680 0;
BA_ "GenMsgTimeoutTime" BO_ 679 0;
BA_ "GenMsgCycleTime" BO_ 679 100;
BA_ "GenMsgSendType" BO_ 679 0;
BA_ "GenMsgTimeoutTime" BO_ 762 0;
BA_ "GenMsgCycleTime" BO_ 762 1000;
BA_ "GenMsgSendType" BO_ 762 0;
BA_ "GenMsgTimeoutTime" BO_ 692 0;
BA_ "GenMsgCycleTime" BO_ 692 1000;
BA_ "GenMsgSendType" BO_ 692 0;
BA_ "GenMsgTimeoutTime" BO_ 37 0;
BA_ "GenMsgSendType" BO_ 37 0;
BA_ "GenMsgCycleTime" BO_ 37 50;
BA_ "GenMsgTimeoutTime" BO_ 36 0;
BA_ "GenMsgSendType" BO_ 36 0;
BA_ "GenMsgCycleTime" BO_ 36 50;
BA_ "GenMsgTimeoutTime" BO_ 673 0;
BA_ "GenMsgSendType" BO_ 673 0;
BA_ "GenMsgCycleTime" BO_ 673 1000;
BA_ "GenMsgTimeoutTime" BO_ 768 0;
BA_ "GenMsgSendType" BO_ 768 1;
BA_ "GenMsgTimeoutTime" BO_ 1346 0;
BA_ "GenMsgSendType" BO_ 1346 0;
BA_ "GenMsgCycleTime" BO_ 1346 1000;
BA_ "GenMsgTimeoutTime" BO_ 22 0;
BA_ "GenMsgCycleTime" BO_ 22 25;
BA_ "GenMsgSendType" BO_ 22 0;
BA_ "GenMsgTimeoutTime" BO_ 23 0;
BA_ "GenMsgCycleTime" BO_ 23 25;
BA_ "GenMsgSendType" BO_ 23 0;
BA_ "GenMsgTimeoutTime" BO_ 48 0;
BA_ "GenMsgCycleTime" BO_ 48 25;
BA_ "GenMsgSendType" BO_ 48 0;
BA_ "GenMsgTimeoutTime" BO_ 185 0;
BA_ "GenMsgCycleTime" BO_ 185 10;
BA_ "GenMsgSendType" BO_ 185 0;
BA_ "GenMsgTimeoutTime" BO_ 1795 0;
BA_ "GenMsgCycleTime" BO_ 1795 1000;
BA_ "GenMsgSendType" BO_ 1795 0;
BA_ "GenMsgTimeoutTime" BO_ 16 0;
BA_ "GenMsgSendType" BO_ 16 1;
BA_ "GenMsgTimeoutTime" BO_ 17 0;
BA_ "GenMsgSendType" BO_ 17 1;
BA_ "GenMsgTimeoutTime" BO_ 1796 0;
BA_ "GenMsgCycleTime" BO_ 1796 1000;
BA_ "GenMsgSendType" BO_ 1796 0;
BA_ "GenMsgTimeoutTime" BO_ 395 0;
BA_ "GenMsgSendType" BO_ 395 1;
BA_ "GenMsgTimeoutTime" BO_ 459 0;
BA_ "GenMsgSendType" BO_ 459 1;
BA_ "GenMsgTimeoutTime" BO_ 4 0;
BA_ "GenMsgSendType" BO_ 4 0;
BA_ "GenMsgCycleTime" BO_ 4 50;
BA_ "GenMsgTimeoutTime" BO_ 384 0;
BA_ "GenMsgSendType" BO_ 384 1;
BA_ "GenMsgTimeoutTime" BO_ 385 0;
BA_ "GenMsgSendType" BO_ 385 0;
BA_ "GenMsgCycleTime" BO_ 385 1000;
BA_ "GenMsgTimeoutTime" BO_ 386 0;
BA_ "GenMsgSendType" BO_ 386 0;
BA_ "GenMsgCycleTime" BO_ 386 1000;
BA_ "GenMsgTimeoutTime" BO_ 387 0;
BA_ "GenMsgSendType" BO_ 387 0;
BA_ "GenMsgCycleTime" BO_ 387 50;
BA_ "GenMsgTimeoutTime" BO_ 388 0;
BA_ "GenMsgSendType" BO_ 388 0;
BA_ "GenMsgCycleTime" BO_ 388 20;
BA_ "GenMsgTimeoutTime" BO_ 389 0;
BA_ "GenMsgSendType" BO_ 389 0;
BA_ "GenMsgCycleTime" BO_ 389 20;
BA_ "GenMsgTimeoutTime" BO_ 392 0;
BA_ "GenMsgSendType" BO_ 392 1;
BA_ "GenMsgTimeoutTime" BO_ 397 0;
BA_ "GenMsgCycleTime" BO_ 397 100;
BA_ "GenMsgSendType" BO_ 397 0;
BA_ "GenMsgTimeoutTime" BO_ 448 0;
BA_ "GenMsgSendType" BO_ 448 1;
BA_ "GenMsgTimeoutTime" BO_ 449 0;
BA_ "GenMsgSendType" BO_ 449 0;
BA_ "GenMsgCycleTime" BO_ 449 1000;
BA_ "GenMsgTimeoutTime" BO_ 450 0;
BA_ "GenMsgSendType" BO_ 450 0;
BA_ "GenMsgCycleTime" BO_ 450 1000;
BA_ "GenMsgTimeoutTime" BO_ 451 0;
BA_ "GenMsgSendType" BO_ 451 0;
BA_ "GenMsgCycleTime" BO_ 451 50;
BA_ "GenMsgTimeoutTime" BO_ 452 0;
BA_ "GenMsgSendType" BO_ 452 0;
BA_ "GenMsgCycleTime" BO_ 452 20;
BA_ "GenMsgTimeoutTime" BO_ 453 0;
BA_ "GenMsgSendType" BO_ 453 0;
BA_ "GenMsgCycleTime" BO_ 453 20;
BA_ "GenSigCycleTime" SG_ 680 MRR_FL_Radar_Reset 100;
BA_ "GenSigSendType" SG_ 680 MRR_FL_Radar_Reset 0;
BA_ "GenSigCycleTime" SG_ 679 MRR_FR_Radar_Reset 100;
BA_ "GenSigSendType" SG_ 679 MRR_FR_Radar_Reset 0;
BA_ "GenSigSendType" SG_ 762 MRR_FL_EBOM_SW_PN_Part2 0;
BA_ "GenSigCycleTime" SG_ 762 MRR_FL_EBOM_SW_PN_Part2 1000;
BA_ "GenSigCycleTime" SG_ 762 MRR_FL_EBOM_SW_PN_Part1 1000;
BA_ "GenSigSendType" SG_ 762 MRR_FL_EBOM_SW_PN_Part1 0;
BA_ "GenSigCycleTime" SG_ 762 MRR_FL_ECU_SerialNumber_Part2 1000;
BA_ "GenSigSendType" SG_ 762 MRR_FL_ECU_SerialNumber_Part2 0;
BA_ "GenSigCycleTime" SG_ 762 MRR_FL_ECU_SerialNumber_Part1 1000;
BA_ "GenSigSendType" SG_ 762 MRR_FL_ECU_SerialNumber_Part1 0;
BA_ "GenSigCycleTime" SG_ 762 MRR_FL_EBOM_ECU_PN_Part2 1000;
BA_ "GenSigSendType" SG_ 762 MRR_FL_EBOM_ECU_PN_Part2 0;
BA_ "GenSigCycleTime" SG_ 762 MRR_FL_EBOM_ECU_PN_Part1 1000;
BA_ "GenSigSendType" SG_ 762 MRR_FL_EBOM_ECU_PN_Part1 0;
BA_ "GenSigSendType" SG_ 762 MRR_FL_SupplManuf_ECU_SW_VesrNum 0;
BA_ "GenSigCycleTime" SG_ 762 MRR_FL_SupplManuf_ECU_SW_VesrNum 1000;
BA_ "GenSigSendType" SG_ 762 MRR_FL_SupplManuf_ECU_HW_VesrNum 0;
BA_ "GenSigCycleTime" SG_ 762 MRR_FL_SupplManuf_ECU_HW_VesrNum 1000;
BA_ "GenSigSendType" SG_ 762 MRR_FL_SupplManuf_ECU_SW_PN_2 0;
BA_ "GenSigCycleTime" SG_ 762 MRR_FL_SupplManuf_ECU_SW_PN_2 1000;
BA_ "GenSigSendType" SG_ 762 MRR_FL_SupplManuf_ECU_SW_PN_1 0;
BA_ "GenSigCycleTime" SG_ 762 MRR_FL_SupplManuf_ECU_SW_PN_1 1000;
BA_ "GenSigSendType" SG_ 762 MRR_FL_SupplManuf_ECU_HW_PN_2 0;
BA_ "GenSigCycleTime" SG_ 762 MRR_FL_SupplManuf_ECU_HW_PN_2 1000;
BA_ "GenSigSendType" SG_ 762 MRR_FL_SupplManuf_ECU_HW_PN_1 0;
BA_ "GenSigCycleTime" SG_ 762 MRR_FL_SupplManuf_ECU_HW_PN_1 1000;
BA_ "GenSigSendType" SG_ 692 MRR_FR_EBOM_SW_PN_Part2 0;
BA_ "GenSigCycleTime" SG_ 692 MRR_FR_EBOM_SW_PN_Part2 1000;
BA_ "GenSigSendType" SG_ 692 MRR_FR_EBOM_SW_PN_Part1 0;
BA_ "GenSigCycleTime" SG_ 692 MRR_FR_EBOM_SW_PN_Part1 1000;
BA_ "GenSigSendType" SG_ 692 MRR_FR_ECU_SerialNumber_Part2 0;
BA_ "GenSigCycleTime" SG_ 692 MRR_FR_ECU_SerialNumber_Part2 1000;
BA_ "GenSigSendType" SG_ 692 MRR_FR_ECU_SerialNumber_Part1 0;
BA_ "GenSigCycleTime" SG_ 692 MRR_FR_ECU_SerialNumber_Part1 1000;
BA_ "GenSigSendType" SG_ 692 MRR_FR_EBOM_ECU_PN_Part2 0;
BA_ "GenSigCycleTime" SG_ 692 MRR_FR_EBOM_ECU_PN_Part2 1000;
BA_ "GenSigSendType" SG_ 692 MRR_FR_EBOM_ECU_PN_Part1 0;
BA_ "GenSigCycleTime" SG_ 692 MRR_FR_EBOM_ECU_PN_Part1 1000;
BA_ "GenSigSendType" SG_ 692 MRR_FR_SupplManuf_ECU_SW_VesrNum 0;
BA_ "GenSigCycleTime" SG_ 692 MRR_FR_SupplManuf_ECU_SW_VesrNum 1000;
BA_ "GenSigCycleTime" SG_ 692 MRR_FR_SupplManuf_ECU_HW_VesrNum 1000;
BA_ "GenSigSendType" SG_ 692 MRR_FR_SupplManuf_ECU_HW_VesrNum 0;
BA_ "GenSigCycleTime" SG_ 692 MRR_FR_SupplManuf_ECU_SW_PN_2 1000;
BA_ "GenSigSendType" SG_ 692 MRR_FR_SupplManuf_ECU_SW_PN_2 0;
BA_ "GenSigCycleTime" SG_ 692 MRR_FR_SupplManuf_ECU_SW_PN_1 1000;
BA_ "GenSigSendType" SG_ 692 MRR_FR_SupplManuf_ECU_SW_PN_1 0;
BA_ "GenSigCycleTime" SG_ 692 MRR_FR_SupplManuf_ECU_HW_PN_2 1000;
BA_ "GenSigSendType" SG_ 692 MRR_FR_SupplManuf_ECU_HW_PN_2 0;
BA_ "GenSigCycleTime" SG_ 692 MRR_FR_SupplManuf_ECU_HW_PN_1 1000;
BA_ "GenSigSendType" SG_ 692 MRR_FR_SupplManuf_ECU_HW_PN_1 0;
BA_ "GenSigCycleTime" SG_ 37 MRR_FR_AAT_MC 50;
BA_ "GenSigSendType" SG_ 37 MRR_FR_AAT_MC 0;
BA_ "GenSigCycleTime" SG_ 37 MRR_FR_AAT_CRC 50;
BA_ "GenSigSendType" SG_ 37 MRR_FR_AAT_CRC 0;
BA_ "GenSigCycleTime" SG_ 37 MRR_FR_POS_80 50;
BA_ "GenSigSendType" SG_ 37 MRR_FR_POS_80 0;
BA_ "GenSigCycleTime" SG_ 37 MRR_FR_POS_70 50;
BA_ "GenSigSendType" SG_ 37 MRR_FR_POS_70 0;
BA_ "GenSigCycleTime" SG_ 37 MRR_FR_POS_60 50;
BA_ "GenSigSendType" SG_ 37 MRR_FR_POS_60 0;
BA_ "GenSigCycleTime" SG_ 37 MRR_FR_POS_50 50;
BA_ "GenSigSendType" SG_ 37 MRR_FR_POS_50 0;
BA_ "GenSigCycleTime" SG_ 37 MRR_FR_POS_40 50;
BA_ "GenSigSendType" SG_ 37 MRR_FR_POS_40 0;
BA_ "GenSigCycleTime" SG_ 37 MRR_FR_POS_30 50;
BA_ "GenSigSendType" SG_ 37 MRR_FR_POS_30 0;
BA_ "GenSigCycleTime" SG_ 37 MRR_FR_POS_20 50;
BA_ "GenSigSendType" SG_ 37 MRR_FR_POS_20 0;
BA_ "GenSigCycleTime" SG_ 37 MRR_FR_POS_10 50;
BA_ "GenSigSendType" SG_ 37 MRR_FR_POS_10 0;
BA_ "GenSigCycleTime" SG_ 37 MRR_FR_0 50;
BA_ "GenSigSendType" SG_ 37 MRR_FR_0 0;
BA_ "GenSigCycleTime" SG_ 37 MRR_FR_NEG_10 50;
BA_ "GenSigSendType" SG_ 37 MRR_FR_NEG_10 0;
BA_ "GenSigCycleTime" SG_ 37 MRR_FR_NEG_20 50;
BA_ "GenSigSendType" SG_ 37 MRR_FR_NEG_20 0;
BA_ "GenSigCycleTime" SG_ 37 MRR_FR_NEG_30 50;
BA_ "GenSigSendType" SG_ 37 MRR_FR_NEG_30 0;
BA_ "GenSigCycleTime" SG_ 37 MRR_FR_NEG_40 50;
BA_ "GenSigSendType" SG_ 37 MRR_FR_NEG_40 0;
BA_ "GenSigCycleTime" SG_ 37 MRR_FR_NEG_50 50;
BA_ "GenSigSendType" SG_ 37 MRR_FR_NEG_50 0;
BA_ "GenSigCycleTime" SG_ 37 MRR_FR_NEG_60 50;
BA_ "GenSigSendType" SG_ 37 MRR_FR_NEG_60 0;
BA_ "GenSigCycleTime" SG_ 37 MRR_FR_NEG_70 50;
BA_ "GenSigSendType" SG_ 37 MRR_FR_NEG_70 0;
BA_ "GenSigCycleTime" SG_ 37 MRR_FR_NEG_80 50;
BA_ "GenSigSendType" SG_ 37 MRR_FR_NEG_80 0;
BA_ "GenSigSendType" SG_ 36 MRR_FL_AAT_CRC 0;
BA_ "GenSigCycleTime" SG_ 36 MRR_FL_AAT_CRC 50;
BA_ "GenSigCycleTime" SG_ 36 MRR_FL_AAT_MC 50;
BA_ "GenSigSendType" SG_ 36 MRR_FL_AAT_MC 0;
BA_ "GenSigCycleTime" SG_ 36 MRR_FL_POS_80 50;
BA_ "GenSigSendType" SG_ 36 MRR_FL_POS_80 0;
BA_ "GenSigCycleTime" SG_ 36 MRR_FL_POS_70 50;
BA_ "GenSigSendType" SG_ 36 MRR_FL_POS_70 0;
BA_ "GenSigCycleTime" SG_ 36 MRR_FL_POS_60 50;
BA_ "GenSigSendType" SG_ 36 MRR_FL_POS_60 0;
BA_ "GenSigCycleTime" SG_ 36 MRR_FL_POS_50 50;
BA_ "GenSigSendType" SG_ 36 MRR_FL_POS_50 0;
BA_ "GenSigCycleTime" SG_ 36 MRR_FL_POS_40 50;
BA_ "GenSigSendType" SG_ 36 MRR_FL_POS_40 0;
BA_ "GenSigCycleTime" SG_ 36 MRR_FL_POS_30 50;
BA_ "GenSigSendType" SG_ 36 MRR_FL_POS_30 0;
BA_ "GenSigCycleTime" SG_ 36 MRR_FL_POS_20 50;
BA_ "GenSigSendType" SG_ 36 MRR_FL_POS_20 0;
BA_ "GenSigCycleTime" SG_ 36 MRR_FL_POS_10 50;
BA_ "GenSigSendType" SG_ 36 MRR_FL_POS_10 0;
BA_ "GenSigCycleTime" SG_ 36 MRR_FL_0 50;
BA_ "GenSigSendType" SG_ 36 MRR_FL_0 0;
BA_ "GenSigCycleTime" SG_ 36 MRR_FL_NEG_80 50;
BA_ "GenSigSendType" SG_ 36 MRR_FL_NEG_80 0;
BA_ "GenSigCycleTime" SG_ 36 MRR_FL_NEG_70 50;
BA_ "GenSigSendType" SG_ 36 MRR_FL_NEG_70 0;
BA_ "GenSigCycleTime" SG_ 36 MRR_FL_NEG_60 50;
BA_ "GenSigSendType" SG_ 36 MRR_FL_NEG_60 0;
BA_ "GenSigCycleTime" SG_ 36 MRR_FL_NEG_50 50;
BA_ "GenSigSendType" SG_ 36 MRR_FL_NEG_50 0;
BA_ "GenSigCycleTime" SG_ 36 MRR_FL_NEG_40 50;
BA_ "GenSigSendType" SG_ 36 MRR_FL_NEG_40 0;
BA_ "GenSigCycleTime" SG_ 36 MRR_FL_NEG_30 50;
BA_ "GenSigSendType" SG_ 36 MRR_FL_NEG_30 0;
BA_ "GenSigCycleTime" SG_ 36 MRR_FL_NEG_20 50;
BA_ "GenSigSendType" SG_ 36 MRR_FL_NEG_20 0;
BA_ "GenSigCycleTime" SG_ 36 MRR_FL_NEG_10 50;
BA_ "GenSigSendType" SG_ 36 MRR_FL_NEG_10 0;
BA_ "GenSigSendType" SG_ 673 MRR_f_Radar_Unreasonable 0;
BA_ "GenSigCycleTime" SG_ 673 MRR_f_Radar_Unreasonable 1000;
BA_ "SignalDescription" SG_ 768 MRR_FL_CAN_DET_MID_TARGET_007 "MID_Target_Discrimination";
BA_ "GenSigSendType" SG_ 768 MRR_FL_CAN_DET_MID_TARGET_007 1;
BA_ "SignalDescription" SG_ 768 MRR_FL_CAN_DET_MID_TARGET_006 "MID_Target_Discrimination";
BA_ "SignalDescription" SG_ 768 MRR_FL_CAN_DET_MID_TARGET_005 "MID_Target_Discrimination";
BA_ "SignalDescription" SG_ 768 MRR_FL_CAN_DET_MID_TARGET_004 "MID_Target_Discrimination";
BA_ "SignalDescription" SG_ 768 MRR_FL_CAN_DET_MID_TARGET_003 "MID_Target_Discrimination";
BA_ "SignalDescription" SG_ 768 MRR_FL_CAN_DET_MID_TARGET_002 "MID_Target_Discrimination";
BA_ "SignalDescription" SG_ 768 MRR_FL_CAN_DET_MID_TARGET_001 "MID_Target_Discrimination";
BA_ "SignalDescription" SG_ 768 MRR_FL_CAN_DET_Near_TARGET_007 "Near_Target_Discrimination";
BA_ "SignalDescription" SG_ 768 MRR_FL_CAN_DET_Near_TARGET_006 "Near_Target_Discrimination";
BA_ "SignalDescription" SG_ 768 MRR_FL_CAN_DET_Near_TARGET_005 "Near_Target_Discrimination";
BA_ "SignalDescription" SG_ 768 MRR_FL_CAN_DET_Near_TARGET_004 "Near_Target_Discrimination";
BA_ "SignalDescription" SG_ 768 MRR_FL_CAN_DET_Near_TARGET_003 "Near_Target_Discrimination";
BA_ "SignalDescription" SG_ 768 MRR_FL_CAN_DET_Near_TARGET_002 "Near_Target_Discrimination";
BA_ "SignalDescription" SG_ 768 MRR_FL_CAN_DET_Near_TARGET_001 "Near_Target_Discrimination";
BA_ "GenSigCmt" SG_ 768 MRR_FL_CAN_DET_ELEVATION_001 "Detected object elevation position";
BA_ "GenSigStartValue" SG_ 768 MRR_FL_CAN_DET_ELEVATION_001 63.8646288209607;
BA_ "GenSigVtEn" SG_ 768 MRR_FL_CAN_DET_CONFID_AZIMUTH_00 "TRUE";
BA_ "GenSigCmt" SG_ 768 MRR_FL_CAN_DET_CONFID_AZIMUTH_00 "Signal to noise level";
BA_ "SystemSignalLongSymbol" SG_ 768 MRR_FL_CAN_DET_CONFID_AZIMUTH_00 "MRR_FL_CAN_DET_CONFID_AZIMUTH_001";
BA_ "GenSigCmt" SG_ 768 MRR_FL_CAN_DET_SUPER_RES_TARGET_ "Super resolution target";
BA_ "SystemSignalLongSymbol" SG_ 768 MRR_FL_CAN_DET_SUPER_RES_TARGET_ "MRR_FL_CAN_DET_SUPER_RES_TARGET_001";
BA_ "GenSigCmt" SG_ 768 MRR_FL_CAN_DET_CONFID_ELEVATION_ "Elevation Angle Confidence";
BA_ "SystemSignalLongSymbol" SG_ 768 MRR_FL_CAN_DET_CONFID_ELEVATION_ "MRR_FL_CAN_DET_CONFID_ELEVATION_001";
BA_ "GenSigCmt" SG_ 768 MRR_FL_CAN_DET_HOST_VEH_CLUTTER_ "Host vehicle clutter";
BA_ "SystemSignalLongSymbol" SG_ 768 MRR_FL_CAN_DET_HOST_VEH_CLUTTER_ "MRR_FL_CAN_DET_HOST_VEH_CLUTTER_001";
BA_ "GenSigCmt" SG_ 768 MRR_FL_CAN_DET_VALID_LEVEL_001 "Detected object valid level";
BA_ "GenSigCmt" SG_ 768 MRR_FL_CAN_DET_AZIMUTH_001 "Detected object azimuth position";
BA_ "GenSigStartValue" SG_ 768 MRR_FL_CAN_DET_AZIMUTH_001 8194.05320813772;
BA_ "GenSigCmt" SG_ 768 MRR_FL_CAN_DET_RANGE_001 "Detected object range";
BA_ "GenSigCmt" SG_ 768 MRR_FL_CAN_DET_RANGE_RATE_001 "Detected object range rate";
BA_ "GenSigStartValue" SG_ 768 MRR_FL_CAN_DET_RANGE_RATE_001 8192;
BA_ "GenSigStartValue" SG_ 768 MRR_FL_CAN_DET_AMPLITUDE_001 64;
BA_ "GenSigCmt" SG_ 768 MRR_FL_CAN_DET_AMPLITUDE_001 "Detected object amplitude";
BA_ "GenSigCmt" SG_ 768 MRR_FL_CAN_SCAN_INDEX_2LSB_001 "The two LSB of scan index";
BA_ "GenSigStartValue" SG_ 768 MRR_FL_CAN_DET_ELEVATION_007 63.8646288209607;
BA_ "GenSigCmt" SG_ 768 MRR_FL_CAN_DET_ELEVATION_007 "Detected object elevation position";
BA_ "GenSigCmt" SG_ 768 MRR_FL_CAN_DET_SUPER_RES_TA_0000 "Super resolution target";
BA_ "SystemSignalLongSymbol" SG_ 768 MRR_FL_CAN_DET_SUPER_RES_TA_0000 "MRR_FL_CAN_DET_SUPER_RES_TARGET_007";
BA_ "GenSigCmt" SG_ 768 MRR_FL_CAN_DET_AZIMUTH_007 "Detected object azimuth position";
BA_ "GenSigStartValue" SG_ 768 MRR_FL_CAN_DET_AZIMUTH_007 8194.05320813772;
BA_ "GenSigCmt" SG_ 768 MRR_FL_CAN_DET_CONFID_ELEVA_0000 "Elevation Angle Confidence";
BA_ "SystemSignalLongSymbol" SG_ 768 MRR_FL_CAN_DET_CONFID_ELEVA_0000 "MRR_FL_CAN_DET_CONFID_ELEVATION_007";
BA_ "GenSigCmt" SG_ 768 MRR_FL_CAN_DET_HOST_VEH_CLU_0000 "Host vehicle clutter";
BA_ "SystemSignalLongSymbol" SG_ 768 MRR_FL_CAN_DET_HOST_VEH_CLU_0000 "MRR_FL_CAN_DET_HOST_VEH_CLUTTER_007";
BA_ "GenSigCmt" SG_ 768 MRR_FL_CAN_DET_RANGE_007 "Detected object range";
BA_ "GenSigVtEn" SG_ 768 MRR_FL_CAN_DET_CONFID_AZIMU_0000 "TRUE";
BA_ "GenSigCmt" SG_ 768 MRR_FL_CAN_DET_CONFID_AZIMU_0000 "Signal to noise level";
BA_ "SystemSignalLongSymbol" SG_ 768 MRR_FL_CAN_DET_CONFID_AZIMU_0000 "MRR_FL_CAN_DET_CONFID_AZIMUTH_007";
BA_ "GenSigCmt" SG_ 768 MRR_FL_CAN_DET_RANGE_RATE_007 "Detected object range rate";
BA_ "GenSigStartValue" SG_ 768 MRR_FL_CAN_DET_RANGE_RATE_007 8192;
BA_ "GenSigCmt" SG_ 768 MRR_FL_CAN_SCAN_INDEX_2LSB_007 "The two LSB of scan index";
BA_ "GenSigStartValue" SG_ 768 MRR_FL_CAN_DET_AMPLITUDE_007 64;
BA_ "GenSigCmt" SG_ 768 MRR_FL_CAN_DET_AMPLITUDE_007 "Detected object amplitude";
BA_ "GenSigCmt" SG_ 768 MRR_FL_CAN_DET_VALID_LEVEL_007 "Detected object valid level";
BA_ "GenSigCmt" SG_ 768 MRR_FL_CAN_DET_ELEVATION_006 "Detected object elevation position";
BA_ "GenSigStartValue" SG_ 768 MRR_FL_CAN_DET_ELEVATION_006 63.8646288209607;
BA_ "GenSigCmt" SG_ 768 MRR_FL_CAN_DET_SUPER_RES_TA_0001 "Super resolution target";
BA_ "SystemSignalLongSymbol" SG_ 768 MRR_FL_CAN_DET_SUPER_RES_TA_0001 "MRR_FL_CAN_DET_SUPER_RES_TARGET_006";
BA_ "GenSigCmt" SG_ 768 MRR_FL_CAN_DET_AZIMUTH_006 "Detected object azimuth position";
BA_ "GenSigStartValue" SG_ 768 MRR_FL_CAN_DET_AZIMUTH_006 8194.05320813772;
BA_ "GenSigCmt" SG_ 768 MRR_FL_CAN_DET_CONFID_ELEVA_0001 "Elevation Angle Confidence";
BA_ "SystemSignalLongSymbol" SG_ 768 MRR_FL_CAN_DET_CONFID_ELEVA_0001 "MRR_FL_CAN_DET_CONFID_ELEVATION_006";
BA_ "GenSigCmt" SG_ 768 MRR_FL_CAN_DET_HOST_VEH_CLU_0001 "Host vehicle clutter";
BA_ "SystemSignalLongSymbol" SG_ 768 MRR_FL_CAN_DET_HOST_VEH_CLU_0001 "MRR_FL_CAN_DET_HOST_VEH_CLUTTER_006";
BA_ "GenSigCmt" SG_ 768 MRR_FL_CAN_DET_RANGE_006 "Detected object range";
BA_ "GenSigVtEn" SG_ 768 MRR_FL_CAN_DET_CONFID_AZIMU_0001 "TRUE";
BA_ "GenSigCmt" SG_ 768 MRR_FL_CAN_DET_CONFID_AZIMU_0001 "Signal to noise level";
BA_ "SystemSignalLongSymbol" SG_ 768 MRR_FL_CAN_DET_CONFID_AZIMU_0001 "MRR_FL_CAN_DET_CONFID_AZIMUTH_006";
BA_ "GenSigCmt" SG_ 768 MRR_FL_CAN_DET_RANGE_RATE_006 "Detected object range rate";
BA_ "GenSigStartValue" SG_ 768 MRR_FL_CAN_DET_RANGE_RATE_006 8192;
BA_ "GenSigCmt" SG_ 768 MRR_FL_CAN_SCAN_INDEX_2LSB_006 "The two LSB of scan index";
BA_ "GenSigStartValue" SG_ 768 MRR_FL_CAN_DET_AMPLITUDE_006 64;
BA_ "GenSigCmt" SG_ 768 MRR_FL_CAN_DET_AMPLITUDE_006 "Detected object amplitude";
BA_ "GenSigCmt" SG_ 768 MRR_FL_CAN_DET_VALID_LEVEL_006 "Detected object valid level";
BA_ "GenSigCmt" SG_ 768 MRR_FL_CAN_DET_ELEVATION_005 "Detected object elevation position";
BA_ "GenSigStartValue" SG_ 768 MRR_FL_CAN_DET_ELEVATION_005 63.8646288209607;
BA_ "GenSigCmt" SG_ 768 MRR_FL_CAN_DET_SUPER_RES_TA_0002 "Super resolution target";
BA_ "SystemSignalLongSymbol" SG_ 768 MRR_FL_CAN_DET_SUPER_RES_TA_0002 "MRR_FL_CAN_DET_SUPER_RES_TARGET_005";
BA_ "GenSigCmt" SG_ 768 MRR_FL_CAN_DET_AZIMUTH_005 "Detected object azimuth position";
BA_ "GenSigStartValue" SG_ 768 MRR_FL_CAN_DET_AZIMUTH_005 8194.05320813772;
BA_ "GenSigCmt" SG_ 768 MRR_FL_CAN_DET_CONFID_ELEVA_0002 "Elevation Angle Confidence";
BA_ "SystemSignalLongSymbol" SG_ 768 MRR_FL_CAN_DET_CONFID_ELEVA_0002 "MRR_FL_CAN_DET_CONFID_ELEVATION_005";
BA_ "GenSigCmt" SG_ 768 MRR_FL_CAN_DET_HOST_VEH_CLU_0002 "Host vehicle clutter";
BA_ "SystemSignalLongSymbol" SG_ 768 MRR_FL_CAN_DET_HOST_VEH_CLU_0002 "MRR_FL_CAN_DET_HOST_VEH_CLUTTER_005";
BA_ "GenSigCmt" SG_ 768 MRR_FL_CAN_DET_RANGE_005 "Detected object range";
BA_ "GenSigVtEn" SG_ 768 MRR_FL_CAN_DET_CONFID_AZIMU_0002 "TRUE";
BA_ "GenSigCmt" SG_ 768 MRR_FL_CAN_DET_CONFID_AZIMU_0002 "Signal to noise level";
BA_ "SystemSignalLongSymbol" SG_ 768 MRR_FL_CAN_DET_CONFID_AZIMU_0002 "MRR_FL_CAN_DET_CONFID_AZIMUTH_005";
BA_ "GenSigCmt" SG_ 768 MRR_FL_CAN_DET_RANGE_RATE_005 "Detected object range rate";
BA_ "GenSigStartValue" SG_ 768 MRR_FL_CAN_DET_RANGE_RATE_005 8192;
BA_ "GenSigCmt" SG_ 768 MRR_FL_CAN_SCAN_INDEX_2LSB_005 "The two LSB of scan index";
BA_ "GenSigStartValue" SG_ 768 MRR_FL_CAN_DET_AMPLITUDE_005 64;
BA_ "GenSigCmt" SG_ 768 MRR_FL_CAN_DET_AMPLITUDE_005 "Detected object amplitude";
BA_ "GenSigCmt" SG_ 768 MRR_FL_CAN_DET_VALID_LEVEL_005 "Detected object valid level";
BA_ "GenSigCmt" SG_ 768 MRR_FL_CAN_DET_ELEVATION_004 "Detected object elevation position";
BA_ "GenSigStartValue" SG_ 768 MRR_FL_CAN_DET_ELEVATION_004 63.8646288209607;
BA_ "GenSigCmt" SG_ 768 MRR_FL_CAN_DET_SUPER_RES_TA_0003 "Super resolution target";
BA_ "SystemSignalLongSymbol" SG_ 768 MRR_FL_CAN_DET_SUPER_RES_TA_0003 "MRR_FL_CAN_DET_SUPER_RES_TARGET_004";
BA_ "GenSigCmt" SG_ 768 MRR_FL_CAN_DET_AZIMUTH_004 "Detected object azimuth position";
BA_ "GenSigStartValue" SG_ 768 MRR_FL_CAN_DET_AZIMUTH_004 8194.05320813772;
BA_ "GenSigCmt" SG_ 768 MRR_FL_CAN_DET_CONFID_ELEVA_0003 "Elevation Angle Confidence";
BA_ "SystemSignalLongSymbol" SG_ 768 MRR_FL_CAN_DET_CONFID_ELEVA_0003 "MRR_FL_CAN_DET_CONFID_ELEVATION_004";
BA_ "GenSigCmt" SG_ 768 MRR_FL_CAN_DET_HOST_VEH_CLU_0003 "Host vehicle clutter";
BA_ "SystemSignalLongSymbol" SG_ 768 MRR_FL_CAN_DET_HOST_VEH_CLU_0003 "MRR_FL_CAN_DET_HOST_VEH_CLUTTER_004";
BA_ "GenSigCmt" SG_ 768 MRR_FL_CAN_DET_RANGE_004 "Detected object range";
BA_ "GenSigVtEn" SG_ 768 MRR_FL_CAN_DET_CONFID_AZIMU_0003 "TRUE";
BA_ "GenSigCmt" SG_ 768 MRR_FL_CAN_DET_CONFID_AZIMU_0003 "Signal to noise level";
BA_ "SystemSignalLongSymbol" SG_ 768 MRR_FL_CAN_DET_CONFID_AZIMU_0003 "MRR_FL_CAN_DET_CONFID_AZIMUTH_004";
BA_ "GenSigCmt" SG_ 768 MRR_FL_CAN_DET_RANGE_RATE_004 "Detected object range rate";
BA_ "GenSigStartValue" SG_ 768 MRR_FL_CAN_DET_RANGE_RATE_004 8192;
BA_ "GenSigCmt" SG_ 768 MRR_FL_CAN_SCAN_INDEX_2LSB_004 "The two LSB of scan index";
BA_ "GenSigStartValue" SG_ 768 MRR_FL_CAN_DET_AMPLITUDE_004 64;
BA_ "GenSigCmt" SG_ 768 MRR_FL_CAN_DET_AMPLITUDE_004 "Detected object amplitude";
BA_ "GenSigCmt" SG_ 768 MRR_FL_CAN_DET_VALID_LEVEL_004 "Detected object valid level";
BA_ "GenSigCmt" SG_ 768 MRR_FL_CAN_DET_ELEVATION_003 "Detected object elevation position";
BA_ "GenSigStartValue" SG_ 768 MRR_FL_CAN_DET_ELEVATION_003 63.8646288209607;
BA_ "GenSigCmt" SG_ 768 MRR_FL_CAN_DET_SUPER_RES_TA_0004 "Super resolution target";
BA_ "SystemSignalLongSymbol" SG_ 768 MRR_FL_CAN_DET_SUPER_RES_TA_0004 "MRR_FL_CAN_DET_SUPER_RES_TARGET_003";
BA_ "GenSigCmt" SG_ 768 MRR_FL_CAN_DET_AZIMUTH_003 "Detected object azimuth position";
BA_ "GenSigStartValue" SG_ 768 MRR_FL_CAN_DET_AZIMUTH_003 8194.05320813772;
BA_ "GenSigCmt" SG_ 768 MRR_FL_CAN_DET_CONFID_ELEVA_0004 "Elevation Angle Confidence";
BA_ "SystemSignalLongSymbol" SG_ 768 MRR_FL_CAN_DET_CONFID_ELEVA_0004 "MRR_FL_CAN_DET_CONFID_ELEVATION_003";
BA_ "GenSigCmt" SG_ 768 MRR_FL_CAN_DET_HOST_VEH_CLU_0004 "Host vehicle clutter";
BA_ "SystemSignalLongSymbol" SG_ 768 MRR_FL_CAN_DET_HOST_VEH_CLU_0004 "MRR_FL_CAN_DET_HOST_VEH_CLUTTER_003";
BA_ "GenSigCmt" SG_ 768 MRR_FL_CAN_DET_RANGE_003 "Detected object range";
BA_ "GenSigVtEn" SG_ 768 MRR_FL_CAN_DET_CONFID_AZIMU_0004 "TRUE";
BA_ "GenSigCmt" SG_ 768 MRR_FL_CAN_DET_CONFID_AZIMU_0004 "Signal to noise level";
BA_ "SystemSignalLongSymbol" SG_ 768 MRR_FL_CAN_DET_CONFID_AZIMU_0004 "MRR_FL_CAN_DET_CONFID_AZIMUTH_003";
BA_ "GenSigCmt" SG_ 768 MRR_FL_CAN_DET_RANGE_RATE_003 "Detected object range rate";
BA_ "GenSigStartValue" SG_ 768 MRR_FL_CAN_DET_RANGE_RATE_003 8192;
BA_ "GenSigCmt" SG_ 768 MRR_FL_CAN_SCAN_INDEX_2LSB_003 "The two LSB of scan index";
BA_ "GenSigStartValue" SG_ 768 MRR_FL_CAN_DET_AMPLITUDE_003 64;
BA_ "GenSigCmt" SG_ 768 MRR_FL_CAN_DET_AMPLITUDE_003 "Detected object amplitude";
BA_ "GenSigCmt" SG_ 768 MRR_FL_CAN_DET_VALID_LEVEL_003 "Detected object valid level";
BA_ "GenSigCmt" SG_ 768 MRR_FL_CAN_DET_ELEVATION_002 "Detected object elevation position";
BA_ "GenSigStartValue" SG_ 768 MRR_FL_CAN_DET_ELEVATION_002 63.8646288209607;
BA_ "GenSigCmt" SG_ 768 MRR_FL_CAN_DET_SUPER_RES_TA_0005 "Super resolution target";
BA_ "SystemSignalLongSymbol" SG_ 768 MRR_FL_CAN_DET_SUPER_RES_TA_0005 "MRR_FL_CAN_DET_SUPER_RES_TARGET_002";
BA_ "GenSigCmt" SG_ 768 MRR_FL_CAN_DET_AZIMUTH_002 "Detected object azimuth position";
BA_ "GenSigStartValue" SG_ 768 MRR_FL_CAN_DET_AZIMUTH_002 8194.05320813772;
BA_ "GenSigCmt" SG_ 768 MRR_FL_CAN_DET_CONFID_ELEVA_0005 "Elevation Angle Confidence";
BA_ "SystemSignalLongSymbol" SG_ 768 MRR_FL_CAN_DET_CONFID_ELEVA_0005 "MRR_FL_CAN_DET_CONFID_ELEVATION_002";
BA_ "GenSigCmt" SG_ 768 MRR_FL_CAN_DET_HOST_VEH_CLU_0005 "Host vehicle clutter";
BA_ "SystemSignalLongSymbol" SG_ 768 MRR_FL_CAN_DET_HOST_VEH_CLU_0005 "MRR_FL_CAN_DET_HOST_VEH_CLUTTER_002";
BA_ "GenSigCmt" SG_ 768 MRR_FL_CAN_DET_RANGE_002 "Detected object range";
BA_ "GenSigVtEn" SG_ 768 MRR_FL_CAN_DET_CONFID_AZIMU_0005 "TRUE";
BA_ "GenSigCmt" SG_ 768 MRR_FL_CAN_DET_CONFID_AZIMU_0005 "Signal to noise level";
BA_ "SystemSignalLongSymbol" SG_ 768 MRR_FL_CAN_DET_CONFID_AZIMU_0005 "MRR_FL_CAN_DET_CONFID_AZIMUTH_002";
BA_ "GenSigCmt" SG_ 768 MRR_FL_CAN_DET_RANGE_RATE_002 "Detected object range rate";
BA_ "GenSigStartValue" SG_ 768 MRR_FL_CAN_DET_RANGE_RATE_002 8192;
BA_ "GenSigCmt" SG_ 768 MRR_FL_CAN_SCAN_INDEX_2LSB_002 "The two LSB of scan index";
BA_ "GenSigStartValue" SG_ 768 MRR_FL_CAN_DET_AMPLITUDE_002 64;
BA_ "GenSigCmt" SG_ 768 MRR_FL_CAN_DET_AMPLITUDE_002 "Detected object amplitude";
BA_ "GenSigCmt" SG_ 768 MRR_FL_CAN_DET_VALID_LEVEL_002 "Detected object valid level";
BA_ "GenSigSendType" SG_ 1346 SensorCfg_MRRFR_AlignRngTolVert 0;
BA_ "GenSigCycleTime" SG_ 1346 SensorCfg_MRRFR_AlignRngTolVert 1000;
BA_ "GenSigSendType" SG_ 1346 SensorCfg_MRRFL_AlignRngTolVert 0;
BA_ "GenSigCycleTime" SG_ 1346 SensorCfg_MRRFL_AlignRngTolVert 1000;
BA_ "GenSigSendType" SG_ 1346 SensorCfg_MRRRR_AlignRngTolVert 0;
BA_ "GenSigCycleTime" SG_ 1346 SensorCfg_MRRRR_AlignRngTolVert 1000;
BA_ "GenSigSendType" SG_ 1346 SensorCfg_MRRRL_AlignRngTolVert 0;
BA_ "GenSigCycleTime" SG_ 1346 SensorCfg_MRRRL_AlignRngTolVert 1000;
BA_ "GenSigSendType" SG_ 1346 SensorCfg_MRRFR_AlignRngTolHorz 0;
BA_ "GenSigCycleTime" SG_ 1346 SensorCfg_MRRFR_AlignRngTolHorz 1000;
BA_ "GenSigSendType" SG_ 1346 SensorCfg_MRRFL_AlignRngTolHorz 0;
BA_ "GenSigCycleTime" SG_ 1346 SensorCfg_MRRFL_AlignRngTolHorz 1000;
BA_ "GenSigSendType" SG_ 1346 SensorCfg_MRRRR_AlignRngTolHorz 0;
BA_ "GenSigCycleTime" SG_ 1346 SensorCfg_MRRRR_AlignRngTolHorz 1000;
BA_ "GenSigSendType" SG_ 1346 SensorCfg_MRRRL_AlignRngTolHorz 0;
BA_ "GenSigCycleTime" SG_ 1346 SensorCfg_MRRRL_AlignRngTolHorz 1000;
BA_ "GenSigCycleTime" SG_ 1346 MRR_SENSR_CFG_CRC 1000;
BA_ "GenSigSendType" SG_ 1346 MRR_SENSR_CFG_CRC 0;
BA_ "GenSigSendType" SG_ 1346 SensorCfg_MRRRR_Pitch 0;
BA_ "GenSigCycleTime" SG_ 1346 SensorCfg_MRRRR_Pitch 1000;
BA_ "GenSigSendType" SG_ 1346 SensorCfg_MRRFL_Pitch 0;
BA_ "GenSigCycleTime" SG_ 1346 SensorCfg_MRRFL_Pitch 1000;
BA_ "GenSigSendType" SG_ 1346 SensorCfg_MRRFR_Pitch 0;
BA_ "GenSigCycleTime" SG_ 1346 SensorCfg_MRRFR_Pitch 1000;
BA_ "GenSigSendType" SG_ 1346 SensorCfg_MRRRL_Pitch 0;
BA_ "GenSigCycleTime" SG_ 1346 SensorCfg_MRRRL_Pitch 1000;
BA_ "GenSigSendType" SG_ 1346 SensorCfg_MRRRL_LatPos 0;
BA_ "GenSigCycleTime" SG_ 1346 SensorCfg_MRRRL_LatPos 1000;
BA_ "GenSigSendType" SG_ 1346 SensorCfg_MRRRR_LatPos 0;
BA_ "GenSigCycleTime" SG_ 1346 SensorCfg_MRRRR_LatPos 1000;
BA_ "GenSigSendType" SG_ 1346 SensorCfg_MRRFL_LatPos 0;
BA_ "GenSigCycleTime" SG_ 1346 SensorCfg_MRRFL_LatPos 1000;
BA_ "GenSigSendType" SG_ 1346 SensorCfg_MRRFR_LatPos 0;
BA_ "GenSigCycleTime" SG_ 1346 SensorCfg_MRRFR_LatPos 1000;
BA_ "GenSigSendType" SG_ 1346 SensorCfg_MRRRL_LongPos 0;
BA_ "GenSigCycleTime" SG_ 1346 SensorCfg_MRRRL_LongPos 1000;
BA_ "GenSigSendType" SG_ 1346 SensorCfg_MRRRR_LongPos 0;
BA_ "GenSigCycleTime" SG_ 1346 SensorCfg_MRRRR_LongPos 1000;
BA_ "GenSigSendType" SG_ 1346 SensorCfg_MRRFL_LongPos 0;
BA_ "GenSigCycleTime" SG_ 1346 SensorCfg_MRRFL_LongPos 1000;
BA_ "GenSigSendType" SG_ 1346 SensorCfg_MRRFR_LongPos 0;
BA_ "GenSigCycleTime" SG_ 1346 SensorCfg_MRRFR_LongPos 1000;
BA_ "GenSigSendType" SG_ 1346 SensorCfg_MRRRL_VertPos 0;
BA_ "GenSigCycleTime" SG_ 1346 SensorCfg_MRRRL_VertPos 1000;
BA_ "GenSigSendType" SG_ 1346 SensorCfg_MRRRR_VertPos 0;
BA_ "GenSigCycleTime" SG_ 1346 SensorCfg_MRRRR_VertPos 1000;
BA_ "GenSigSendType" SG_ 1346 SensorCfg_MRRFL_VertPos 0;
BA_ "GenSigCycleTime" SG_ 1346 SensorCfg_MRRFL_VertPos 1000;
BA_ "GenSigSendType" SG_ 1346 SensorCfg_MRRFR_VertPos 0;
BA_ "GenSigCycleTime" SG_ 1346 SensorCfg_MRRFR_VertPos 1000;
BA_ "GenSigSendType" SG_ 1346 SensorCfg_MRRRL_Yaw 0;
BA_ "GenSigCycleTime" SG_ 1346 SensorCfg_MRRRL_Yaw 1000;
BA_ "GenSigSendType" SG_ 1346 SensorCfg_MRRRR_Yaw 0;
BA_ "GenSigCycleTime" SG_ 1346 SensorCfg_MRRRR_Yaw 1000;
BA_ "GenSigSendType" SG_ 1346 SensorCfg_MRRFL_Yaw 0;
BA_ "GenSigCycleTime" SG_ 1346 SensorCfg_MRRFL_Yaw 1000;
BA_ "GenSigSendType" SG_ 1346 SensorCfg_MRRFR_Yaw 0;
BA_ "GenSigCycleTime" SG_ 1346 SensorCfg_MRRFR_Yaw 1000;
BA_ "GenSigSendType" SG_ 1346 SensorCfg_MRRRL_Orientation 0;
BA_ "GenSigCycleTime" SG_ 1346 SensorCfg_MRRRL_Orientation 1000;
BA_ "GenSigSendType" SG_ 1346 SensorCfg_MRRRR_Orientation 0;
BA_ "GenSigCycleTime" SG_ 1346 SensorCfg_MRRRR_Orientation 1000;
BA_ "GenSigSendType" SG_ 1346 SensorCfg_MRRFL_Orientation 0;
BA_ "GenSigCycleTime" SG_ 1346 SensorCfg_MRRFL_Orientation 1000;
BA_ "GenSigSendType" SG_ 1346 SensorCfg_MRRFR_Orientation 0;
BA_ "GenSigCycleTime" SG_ 1346 SensorCfg_MRRFR_Orientation 1000;
BA_ "GenSigSendType" SG_ 22 RadarWaveform_MRRFR 0;
BA_ "GenSigCycleTime" SG_ 22 RadarWaveform_MRRFR 25;
BA_ "GenSigSendType" SG_ 22 MRR_FR_CAN_NUMBER_OF_TRACKS_STAT 0;
BA_ "GenSigCycleTime" SG_ 22 MRR_FR_CAN_NUMBER_OF_TRACKS_STAT 25;
BA_ "GenSigSendType" SG_ 22 MRR_FR_CAN_NUMBER_OF_TRACKS_MOV 0;
BA_ "GenSigCycleTime" SG_ 22 MRR_FR_CAN_NUMBER_OF_TRACKS_MOV 25;
BA_ "GenSigSendType" SG_ 22 MRR_FR_CAN_TD_SCAN_COUNTER 0;
BA_ "GenSigCycleTime" SG_ 22 MRR_FR_CAN_TD_SCAN_COUNTER 25;
BA_ "GenSigSendType" SG_ 22 MRR_FR_CAN_FOUND_TARGET 0;
BA_ "GenSigCycleTime" SG_ 22 MRR_FR_CAN_FOUND_TARGET 25;
BA_ "GenSigSendType" SG_ 22 MRR_FR_CAN_BLOCKAGE_TD 0;
BA_ "GenSigCycleTime" SG_ 22 MRR_FR_CAN_BLOCKAGE_TD 25;
BA_ "GenSigSendType" SG_ 23 RadarWaveform_MRRFL 0;
BA_ "GenSigCycleTime" SG_ 23 RadarWaveform_MRRFL 25;
BA_ "GenSigSendType" SG_ 23 MRR_FL_CAN_NUMBER_OF_TRACKS_STAT 0;
BA_ "GenSigCycleTime" SG_ 23 MRR_FL_CAN_NUMBER_OF_TRACKS_STAT 25;
BA_ "GenSigSendType" SG_ 23 MRR_FL_CAN_NUMBER_OF_TRACKS_MOV 0;
BA_ "GenSigCycleTime" SG_ 23 MRR_FL_CAN_NUMBER_OF_TRACKS_MOV 25;
BA_ "GenSigSendType" SG_ 23 MRR_FL_CAN_TD_SCAN_COUNTER 0;
BA_ "GenSigCycleTime" SG_ 23 MRR_FL_CAN_TD_SCAN_COUNTER 25;
BA_ "GenSigSendType" SG_ 23 MRR_FL_CAN_FOUND_TARGET 0;
BA_ "GenSigCycleTime" SG_ 23 MRR_FL_CAN_FOUND_TARGET 25;
BA_ "GenSigSendType" SG_ 23 MRR_FL_CAN_BLOCKAGE_TD 0;
BA_ "GenSigCycleTime" SG_ 23 MRR_FL_CAN_BLOCKAGE_TD 25;
BA_ "GenSigSendType" SG_ 48 VehOverGnd_V_Est 0;
BA_ "GenSigCycleTime" SG_ 48 VehOverGnd_V_Est 25;
BA_ "SignalDescription" SG_ 48 CAN_IGN_STATUS "Ignition Status";
BA_ "GenSigSendType" SG_ 48 CAN_IGN_STATUS 0;
BA_ "GenSigCycleTime" SG_ 48 CAN_IGN_STATUS 25;
BA_ "GenSigVtEn" SG_ 48 CAN_IGN_STATUS "TRUE";
BA_ "SignalDescription" SG_ 48 CAN_PRND_POSITION "Gear Position";
BA_ "GenSigSendType" SG_ 48 CAN_PRND_POSITION 0;
BA_ "GenSigCmt" SG_ 48 CAN_PRND_POSITION "Gear Position";
BA_ "GenSigVtEn" SG_ 48 CAN_PRND_POSITION "TRUE";
BA_ "GenSigCycleTime" SG_ 48 CAN_PRND_POSITION 25;
BA_ "SignalDescription" SG_ 48 CAN_VEH_BATT_VOLT "Battery Voltage";
BA_ "GenSigSendType" SG_ 48 CAN_VEH_BATT_VOLT 0;
BA_ "GenSigCycleTime" SG_ 48 CAN_VEH_BATT_VOLT 25;
BA_ "GenSigVtEn" SG_ 48 CAN_VEH_BATT_VOLT "TRUE";
BA_ "GenSigTimeoutTime_ABS_ESC" SG_ 48 CAN_VEH_BATT_VOLT 300;
BA_ "GenSigCycleTime" SG_ 48 CAN_sigactualvalues_CRC 25;
BA_ "GenSigSendType" SG_ 48 CAN_sigactualvalues_CRC 0;
BA_ "GenSigCycleTime" SG_ 48 CAN_sigactualvalues_MC 25;
BA_ "GenSigSendType" SG_ 48 CAN_sigactualvalues_MC 0;
BA_ "SignalDescription" SG_ 48 CAN_Outside_Air_Temp "Ambient Temperature";
BA_ "GenSigSendType" SG_ 48 CAN_Outside_Air_Temp 0;
BA_ "GenSigCycleTime" SG_ 48 CAN_Outside_Air_Temp 25;
BA_ "GenSigStartValue" SG_ 48 CAN_Outside_Air_Temp 254;
BA_ "GenSigCycleTime" SG_ 185 CAN_CADM_Master 10;
BA_ "GenSigSendType" SG_ 185 CAN_CADM_Master 0;
BA_ "GenSigSendType" SG_ 185 CAN_VEHICLE_SPEED 0;
BA_ "GenSigCycleTime" SG_ 185 CAN_VEHICLE_SPEED 10;
BA_ "GenSigSendType" SG_ 185 CAN_STEERING_ANGLE 0;
BA_ "GenSigCycleTime" SG_ 185 CAN_STEERING_ANGLE 10;
BA_ "GenSigSendType" SG_ 185 CAN_VEHICLE_MODE 0;
BA_ "GenSigCycleTime" SG_ 185 CAN_VEHICLE_MODE 10;
BA_ "GenSigSendType" SG_ 185 CAN_WIPER_STATUS 0;
BA_ "GenSigCycleTime" SG_ 185 CAN_WIPER_STATUS 10;
BA_ "GenSigCmt" SG_ 185 CAN_WIPER_STATUS "Windshield wiper status";
BA_ "GenSigSendType" SG_ 185 CAN_YAW_RATE 0;
BA_ "GenSigCycleTime" SG_ 185 CAN_YAW_RATE 10;
BA_ "GenSigSendType" SG_ 185 CAN_STEERING_ANGLE_SIGN 0;
BA_ "GenSigCycleTime" SG_ 185 CAN_STEERING_ANGLE_SIGN 10;
BA_ "GenSigSendType" SG_ 185 CAN_YAW_RATE_VALIDITY 0;
BA_ "GenSigCycleTime" SG_ 185 CAN_YAW_RATE_VALIDITY 10;
BA_ "GenSigSendType" SG_ 185 CAN_VEHICLE_STAT 0;
BA_ "GenSigCycleTime" SG_ 185 CAN_VEHICLE_STAT 10;
BA_ "GenSigSendType" SG_ 185 CAN_CADM_DrivingDirection 0;
BA_ "GenSigCycleTime" SG_ 185 CAN_CADM_DrivingDirection 10;
BA_ "GenSigSendType" SG_ 185 CAN_VEHICLE_SPEED_VALIDITY 0;
BA_ "GenSigCycleTime" SG_ 185 CAN_VEHICLE_SPEED_VALIDITY 10;
BA_ "GenSigSendType" SG_ 185 CAN_VEHICLE_SPEED_DIRECTION 0;
BA_ "GenSigCycleTime" SG_ 185 CAN_VEHICLE_SPEED_DIRECTION 10;
BA_ "GenSigCmt" SG_ 185 CAN_VEHICLE_SPEED_CALC_QF "Quality factor of the CAN_VEHICLE_SPEED_CALC";
BA_ "GenSigSendType" SG_ 185 CAN_VEHICLE_SPEED_CALC_QF 0;
BA_ "GenSigCycleTime" SG_ 185 CAN_VEHICLE_SPEED_CALC_QF 10;
BA_ "GenSigSendType" SG_ 185 CAN_VEHICLE_SPEED_CALC 0;
BA_ "GenSigCycleTime" SG_ 185 CAN_VEHICLE_SPEED_CALC 10;
BA_ "GenSigCmt" SG_ 185 CAN_VEHICLE_SPEED_CALC "Contains the compensated vehicle speed used within the FCR";
BA_ "GenSigStartValue" SG_ 185 CAN_YAW_RATE_CALC 3200;
BA_ "GenSigCmt" SG_ 185 CAN_YAW_RATE_CALC "Contains the bias-compensated yaw rate";
BA_ "GenSigSendType" SG_ 185 CAN_YAW_RATE_CALC 0;
BA_ "GenSigCycleTime" SG_ 185 CAN_YAW_RATE_CALC 10;
BA_ "GenSigCmt" SG_ 185 CAN_YAW_RATE_CALC_QF "Quality factor of the CAN_YAW_RATE_CALC signal";
BA_ "GenSigSendType" SG_ 185 CAN_YAW_RATE_CALC_QF 0;
BA_ "GenSigCycleTime" SG_ 185 CAN_YAW_RATE_CALC_QF 10;
BA_ "GenSigCycleTime" SG_ 185 VEH_STATE_MSG_CRC 10;
BA_ "GenSigSendType" SG_ 185 VEH_STATE_MSG_CRC 0;
BA_ "GenSigCycleTime" SG_ 185 VEH_STATE_MSG_MC 10;
BA_ "GenSigSendType" SG_ 185 VEH_STATE_MSG_MC 0;
BA_ "GenSigSendType" SG_ 185 Yaw_Rate_Reference 0;
BA_ "GenSigCycleTime" SG_ 185 Yaw_Rate_Reference 10;
BA_ "SignalDescription" SG_ 185 Yaw_Rate_Reference "Yaw rate reference";
BA_ "GenSigVtEn" SG_ 185 Yaw_Rate_Reference_Valid "TRUE";
BA_ "GenSigSendType" SG_ 185 Yaw_Rate_Reference_Valid 0;
BA_ "GenSigCycleTime" SG_ 185 Yaw_Rate_Reference_Valid 10;
BA_ "SignalDescription" SG_ 185 Yaw_Rate_Reference_Valid "yaw rate reference validity";
BA_ "GenSigVtEn" SG_ 185 CAN_VEH_LONG_ACCEL_QF "TRUE";
BA_ "GenSigSendType" SG_ 185 CAN_VEH_LONG_ACCEL_QF 0;
BA_ "GenSigCycleTime" SG_ 185 CAN_VEH_LONG_ACCEL_QF 10;
BA_ "SignalDescription" SG_ 185 CAN_VEH_LONG_ACCEL_QF "Vehicle longitudinal acceleration quality factor";
BA_ "GenSigSendType" SG_ 185 CAN_VEH_LONG_ACCEL 0;
BA_ "GenSigCycleTime" SG_ 185 CAN_VEH_LONG_ACCEL 10;
BA_ "GenSigStartValue" SG_ 185 CAN_VEH_LONG_ACCEL 4000;
BA_ "SignalDescription" SG_ 185 CAN_VEH_LONG_ACCEL "Vehicle longitudinal acceleration";
BA_ "GenSigSendType" SG_ 185 CAN_STEERING_WHL_ANGLE 0;
BA_ "GenSigCycleTime" SG_ 185 CAN_STEERING_WHL_ANGLE 10;
BA_ "GenSigStartValue" SG_ 185 CAN_STEERING_WHL_ANGLE 16000;
BA_ "SignalDescription" SG_ 185 CAN_STEERING_WHL_ANGLE "Steering wheel angle";
BA_ "GenSigVtEn" SG_ 185 CAN_STEERING_WHL_ANGLE_QF "TRUE";
BA_ "GenSigSendType" SG_ 185 CAN_STEERING_WHL_ANGLE_QF 0;
BA_ "GenSigCycleTime" SG_ 185 CAN_STEERING_WHL_ANGLE_QF 10;
BA_ "SignalDescription" SG_ 185 CAN_STEERING_WHL_ANGLE_QF "Steering wheel angle quality factor";
BA_ "GenSigVtEn" SG_ 185 CAN_BRAKE_PEDAL "TRUE";
BA_ "GenSigSendType" SG_ 185 CAN_BRAKE_PEDAL 0;
BA_ "GenSigCycleTime" SG_ 185 CAN_BRAKE_PEDAL 10;
BA_ "SignalDescription" SG_ 185 CAN_BRAKE_PEDAL "Brake pedal";
BA_ "GenSigVtEn" SG_ 185 CAN_TURN_SIGNAL_STATUS "TRUE";
BA_ "GenSigSendType" SG_ 185 CAN_TURN_SIGNAL_STATUS 0;
BA_ "GenSigCycleTime" SG_ 185 CAN_TURN_SIGNAL_STATUS 10;
BA_ "SignalDescription" SG_ 185 CAN_TURN_SIGNAL_STATUS "Turn signal status";
BA_ "GenSigSendType" SG_ 1795 k_radar_azimuth_polarity 0;
BA_ "GenSigCycleTime" SG_ 1795 k_radar_azimuth_polarity 1000;
BA_ "SignalDescription" SG_ 1795 CAN_FA_VERT_UPPER_LIMIT "Upper limit of LRRF1 FA is in degrees";
BA_ "GenSigSendType" SG_ 1795 CAN_FA_VERT_UPPER_LIMIT 0;
BA_ "GenSigCycleTime" SG_ 1795 CAN_FA_VERT_UPPER_LIMIT 1000;
BA_ "SignalDescription" SG_ 1795 CAN_FA_VERT_LOWER_LIMIT "Lower limit of LRRF1 FA is in degrees";
BA_ "GenSigSendType" SG_ 1795 CAN_FA_VERT_LOWER_LIMIT 0;
BA_ "GenSigCycleTime" SG_ 1795 CAN_FA_VERT_LOWER_LIMIT 1000;
BA_ "SignalDescription" SG_ 1795 CAN_FA_VERT_GROUND_OFFSET "Ground Offset for LRRF1 FA is in degrees";
BA_ "GenSigSendType" SG_ 1795 CAN_FA_VERT_GROUND_OFFSET 0;
BA_ "GenSigCycleTime" SG_ 1795 CAN_FA_VERT_GROUND_OFFSET 1000;
BA_ "GenSigSendType" SG_ 1795 SAT_CAN_ODOMETER 0;
BA_ "GenSigCycleTime" SG_ 1795 SAT_CAN_ODOMETER 1000;
BA_ "GenSigSendType" SG_ 1795 SAT_VIN_part3 0;
BA_ "GenSigCycleTime" SG_ 1795 SAT_VIN_part3 1000;
BA_ "SignalDescription" SG_ 1795 SAT_VIN_part3 "Vehicle Identification Number Part 3";
BA_ "GenSigSendType" SG_ 1795 SAT_VIN_part2 0;
BA_ "GenSigCycleTime" SG_ 1795 SAT_VIN_part2 1000;
BA_ "SignalDescription" SG_ 1795 SAT_VIN_part2 "Vehicle Identification Number Part 2";
BA_ "GenSigSendType" SG_ 1795 SAT_VIN_part1 0;
BA_ "GenSigCycleTime" SG_ 1795 SAT_VIN_part1 1000;
BA_ "SignalDescription" SG_ 1795 SAT_VIN_part1 "Vehicle Identification Number Part 1";
BA_ "GenSigCmt" SG_ 16 MRR_FL_CAN_INST_MODE "Instrumentation mode";
BA_ "GenSigVtEn" SG_ 16 MRR_FL_CAN_INST_MODE "TRUE";
BA_ "GenSigSendType" SG_ 16 MRR_FL_CAN_INST_MODE 1;
BA_ "GenSigCmt" SG_ 17 MRR_FR_CAN_INST_MODE "Instrumentation mode";
BA_ "GenSigVtEn" SG_ 17 MRR_FR_CAN_INST_MODE "TRUE";
BA_ "GenSigSendType" SG_ 17 MRR_FR_CAN_INST_MODE 1;
BA_ "GenSigSendType" SG_ 1796 CAN_INTF_MINOR_VERSION 0;
BA_ "GenSigCycleTime" SG_ 1796 CAN_INTF_MINOR_VERSION 1000;
BA_ "GenSigSendType" SG_ 1796 CAN_INTF_MAJOR_VERSION 0;
BA_ "GenSigCycleTime" SG_ 1796 CAN_INTF_MAJOR_VERSION 1000;
BA_ "SignalDescription" SG_ 1796 CAN_PCAN_MINOR_CADM_HOST "PCAN protocol minor version used by the CADM";
BA_ "GenSigSendType" SG_ 1796 CAN_PCAN_MINOR_CADM_HOST 0;
BA_ "GenSigCycleTime" SG_ 1796 CAN_PCAN_MINOR_CADM_HOST 1000;
BA_ "SignalDescription" SG_ 1796 CAN_PCAN_MAJOR_CADM_HOST "PCAN protocol major version used by the CADM";
BA_ "GenSigSendType" SG_ 1796 CAN_PCAN_MAJOR_CADM_HOST 0;
BA_ "GenSigCycleTime" SG_ 1796 CAN_PCAN_MAJOR_CADM_HOST 1000;
BA_ "GenSigSendType" SG_ 1796 CADM_Field_Rev 0;
BA_ "GenSigCycleTime" SG_ 1796 CADM_Field_Rev 1000;
BA_ "GenSigSendType" SG_ 1796 CADM_SW_Promote_Rev 0;
BA_ "GenSigCycleTime" SG_ 1796 CADM_SW_Promote_Rev 1000;
BA_ "GenSigSendType" SG_ 1796 CADM_SW_Release_Rev 0;
BA_ "GenSigCycleTime" SG_ 1796 CADM_SW_Release_Rev 1000;
BA_ "GenSigSendType" SG_ 1796 CAN_PCAN_MINOR_VER 0;
BA_ "GenSigCycleTime" SG_ 1796 CAN_PCAN_MINOR_VER 1000;
BA_ "GenSigSendType" SG_ 1796 CAN_PCAN_MAJOR_VER 0;
BA_ "GenSigCycleTime" SG_ 1796 CAN_PCAN_MAJOR_VER 1000;
BA_ "GenSigSendType" SG_ 395 MRR_FL_CAN_VRTCL_ALIGN_UPDATES_N 1;
BA_ "GenSigCmt" SG_ 395 MRR_FL_CAN_VRTCL_ALIGN_UPDATES_N "Number of alignment updates done.";
BA_ "SystemSignalLongSymbol" SG_ 395 MRR_FL_CAN_VRTCL_ALIGN_UPDATES_N "MRR_FL_CAN_VRTCL_ALIGN_UPDATES_Nbr";
BA_ "GenSigCmt" SG_ 395 MRR_FL_CAN_HRZNTL_ALIGN_UPDATES_ "Number of alignment updates done.";
BA_ "SystemSignalLongSymbol" SG_ 395 MRR_FL_CAN_HRZNTL_ALIGN_UPDATES_ "MRR_FL_CAN_HRZNTL_ALIGN_UPDATES_Nbr";
BA_ "SystemSignalLongSymbol" SG_ 395 MRR_FL_Horizontal_Alignment_Stat "MRR_FL_Horizontal_Alignment_Status";
BA_ "SystemSignalLongSymbol" SG_ 395 MRR_FL_Horizontal_Alignment_0000 "MRR_FL_Horizontal_Alignment_State";
BA_ "GenSigStartValue" SG_ 395 MRR_FL_Align_Vertical_Ref 511.500000000001;
BA_ "GenSigStartValue" SG_ 395 MRR_FL_Align_Vertical_Angle 511.500000000001;
BA_ "GenSigStartValue" SG_ 395 MRR_FL_Align_Horizontal_Angle 511.5;
BA_ "GenSigStartValue" SG_ 395 MRR_FL_Align_Horizontal_Ref 511.5;
BA_ "GenSigSendType" SG_ 459 MRR_FR_CAN_VRTCL_ALIGN_UPDATES_N 1;
BA_ "GenSigCmt" SG_ 459 MRR_FR_CAN_VRTCL_ALIGN_UPDATES_N "Number of alignment updates done.";
BA_ "SystemSignalLongSymbol" SG_ 459 MRR_FR_CAN_VRTCL_ALIGN_UPDATES_N "MRR_FR_CAN_VRTCL_ALIGN_UPDATES_Nbr";
BA_ "GenSigCmt" SG_ 459 MRR_FR_CAN_HRZNTL_ALIGN_UPDATES_ "Number of alignment updates done.";
BA_ "SystemSignalLongSymbol" SG_ 459 MRR_FR_CAN_HRZNTL_ALIGN_UPDATES_ "MRR_FR_CAN_HRZNTL_ALIGN_UPDATES_Nbr";
BA_ "SystemSignalLongSymbol" SG_ 459 MRR_FR_Horizontal_Alignment_Stat "MRR_FR_Horizontal_Alignment_Status";
BA_ "SystemSignalLongSymbol" SG_ 459 MRR_FR_Horizontal_Alignment_0000 "MRR_FR_Horizontal_Alignment_State";
BA_ "GenSigStartValue" SG_ 459 MRR_FR_Align_Vertical_Ref 511.500000000001;
BA_ "GenSigStartValue" SG_ 459 MRR_FR_Align_Vertical_Angle 511.500000000001;
BA_ "GenSigStartValue" SG_ 459 MRR_FR_Align_Horizontal_Angle 511.5;
BA_ "GenSigStartValue" SG_ 459 MRR_FR_Align_Horizontal_Ref 511.5;
BA_ "GenSigCycleTime" SG_ 4 Radar_Trig_Control_CRC 50;
BA_ "GenSigSendType" SG_ 4 Radar_Trig_Control_CRC 0;
BA_ "GenSigCycleTime" SG_ 4 Radar_Trig_Control_MC 50;
BA_ "GenSigSendType" SG_ 4 Radar_Trig_Control_MC 0;
BA_ "GenSigSendType" SG_ 4 CADM_TimeSync_Timer_Count 0;
BA_ "GenSigCycleTime" SG_ 4 CADM_TimeSync_Timer_Count 50;
BA_ "SystemSignalLongSymbol" SG_ 384 MRR_FL_CAN_TX_VEH_SPEED_DIRECTIO "MRR_FL_CAN_TX_VEH_SPEED_DIRECTION";
BA_ "SystemSignalLongSymbol" SG_ 384 MRR_FL_CAN_TX_STEERING_ANGLE_SIG "MRR_FL_CAN_TX_STEERING_ANGLE_SIGN";
BA_ "GenSigSendType" SG_ 384 MRR_FL_CAN_TX_STEERING_ANGLE 1;
BA_ "GenSigCycleTime" SG_ 385 MRR_FL_Dolphin_Chip_ID_Part2 1000;
BA_ "GenSigSendType" SG_ 385 MRR_FL_Dolphin_Chip_ID_Part2 0;
BA_ "GenSigCycleTime" SG_ 385 MRR_FL_Dolphin_Chip_ID_Part1 1000;
BA_ "GenSigSendType" SG_ 385 MRR_FL_Dolphin_Chip_ID_Part1 0;
BA_ "GenSigCycleTime" SG_ 385 MRR_FL_RRU_Chip_ID_Part4 1000;
BA_ "GenSigSendType" SG_ 385 MRR_FL_RRU_Chip_ID_Part4 0;
BA_ "GenSigCycleTime" SG_ 385 MRR_FL_RRU_Chip_ID_Part3 1000;
BA_ "GenSigSendType" SG_ 385 MRR_FL_RRU_Chip_ID_Part3 0;
BA_ "GenSigCycleTime" SG_ 385 MRR_FL_RRU_Chip_ID_Part2 1000;
BA_ "GenSigSendType" SG_ 385 MRR_FL_RRU_Chip_ID_Part2 0;
BA_ "GenSigCycleTime" SG_ 385 MRR_FL_RRU_Chip_ID_Part1 1000;
BA_ "GenSigSendType" SG_ 385 MRR_FL_RRU_Chip_ID_Part1 0;
BA_ "GenSigCycleTime" SG_ 385 MRR_FL_CAN_TX_HW_VERSION 1000;
BA_ "GenSigSendType" SG_ 385 MRR_FL_CAN_TX_HW_VERSION 0;
BA_ "GenSigSendType" SG_ 386 MRR_FL_CAN_PCAN_PROTOCOL_PROMOTE 0;
BA_ "GenSigCycleTime" SG_ 386 MRR_FL_CAN_PCAN_PROTOCOL_PROMOTE 1000;
BA_ "GenSigCycleTime" SG_ 386 MRR_FL_CAN_TX_SW_VERSION_DSP 1000;
BA_ "GenSigSendType" SG_ 386 MRR_FL_CAN_TX_SW_VERSION_DSP 0;
BA_ "GenSigSendType" SG_ 386 MRR_FL_CAN_TX_SW_VERSION_ARM 0;
BA_ "GenSigCycleTime" SG_ 386 MRR_FL_CAN_TX_SW_VERSION_ARM 1000;
BA_ "GenSigSendType" SG_ 386 MRR_FL_CAN_TX_PCAN_PROTOCOL_MINO 0;
BA_ "GenSigCycleTime" SG_ 386 MRR_FL_CAN_TX_PCAN_PROTOCOL_MINO 1000;
BA_ "SystemSignalLongSymbol" SG_ 386 MRR_FL_CAN_TX_PCAN_PROTOCOL_MINO "MRR_FL_CAN_TX_PCAN_PROTOCOL_MINOR";
BA_ "GenSigSendType" SG_ 386 MRR_FL_CAN_TX_PCAN_PROTOCOL_MAJO 0;
BA_ "GenSigCycleTime" SG_ 386 MRR_FL_CAN_TX_PCAN_PROTOCOL_MAJO 1000;
BA_ "SystemSignalLongSymbol" SG_ 386 MRR_FL_CAN_TX_PCAN_PROTOCOL_MAJO "MRR_FL_CAN_TX_PCAN_PROTOCOL_MAJOR";
BA_ "GenSigSendType" SG_ 386 MRR_FL_CAN_Dyn_Align_Algorithm_V 0;
BA_ "GenSigCycleTime" SG_ 386 MRR_FL_CAN_Dyn_Align_Algorithm_V 1000;
BA_ "SystemSignalLongSymbol" SG_ 386 MRR_FL_CAN_Dyn_Align_Algorithm_V "MRR_FL_CAN_Dyn_Align_Algorithm_Version_Major";
BA_ "GenSigSendType" SG_ 386 MRR_FL_CAN_Dyn_Align_Algori_0000 0;
BA_ "GenSigCycleTime" SG_ 386 MRR_FL_CAN_Dyn_Align_Algori_0000 1000;
BA_ "SystemSignalLongSymbol" SG_ 386 MRR_FL_CAN_Dyn_Align_Algori_0000 "MRR_FL_CAN_Dyn_Align_Algorithm_Version_Minor";
BA_ "GenSigSendType" SG_ 386 MRR_FL_CAN_Dyn_Align_Algori_0001 0;
BA_ "GenSigCycleTime" SG_ 386 MRR_FL_CAN_Dyn_Align_Algori_0001 1000;
BA_ "SystemSignalLongSymbol" SG_ 386 MRR_FL_CAN_Dyn_Align_Algori_0001 "MRR_FL_CAN_Dyn_Align_Algorithm_Version_Promote";
BA_ "GenSigSendType" SG_ 386 MRR_FL_Core_Radar_BB_Version_Fie 0;
BA_ "GenSigCycleTime" SG_ 386 MRR_FL_Core_Radar_BB_Version_Fie 1000;
BA_ "SystemSignalLongSymbol" SG_ 386 MRR_FL_Core_Radar_BB_Version_Fie "MRR_FL_Core_Radar_BB_Version_Field";
BA_ "GenSigSendType" SG_ 386 MRR_FL_Core_Radar_BB_Version_Pro 0;
BA_ "GenSigCycleTime" SG_ 386 MRR_FL_Core_Radar_BB_Version_Pro 1000;
BA_ "SystemSignalLongSymbol" SG_ 386 MRR_FL_Core_Radar_BB_Version_Pro "MRR_FL_Core_Radar_BB_Version_Promote";
BA_ "GenSigSendType" SG_ 386 MRR_FL_Core_Radar_BB_Version_Min 0;
BA_ "GenSigCycleTime" SG_ 386 MRR_FL_Core_Radar_BB_Version_Min 1000;
BA_ "SystemSignalLongSymbol" SG_ 386 MRR_FL_Core_Radar_BB_Version_Min "MRR_FL_Core_Radar_BB_Version_Minor";
BA_ "GenSigSendType" SG_ 386 MRR_FL_Core_Radar_BB_Version_Maj 0;
BA_ "GenSigCycleTime" SG_ 386 MRR_FL_Core_Radar_BB_Version_Maj 1000;
BA_ "SystemSignalLongSymbol" SG_ 386 MRR_FL_Core_Radar_BB_Version_Maj "MRR_FL_Core_Radar_BB_Version_Major";
BA_ "GenSigSendType" SG_ 386 MRR_FL_CAN_USC_Field 0;
BA_ "GenSigCycleTime" SG_ 386 MRR_FL_CAN_USC_Field 1000;
BA_ "GenSigSendType" SG_ 386 MRR_FL_CAN_USC_Promote 0;
BA_ "GenSigCycleTime" SG_ 386 MRR_FL_CAN_USC_Promote 1000;
BA_ "GenSigSendType" SG_ 386 MRR_FL_CAN_USC_Minor 0;
BA_ "GenSigCycleTime" SG_ 386 MRR_FL_CAN_USC_Minor 1000;
BA_ "GenSigSendType" SG_ 386 MRR_FL_CAN_USC_Major 0;
BA_ "GenSigCycleTime" SG_ 386 MRR_FL_CAN_USC_Major 1000;
BA_ "GenSigSendType" SG_ 386 MRR_FL_CAN_SMC_Field 0;
BA_ "GenSigCycleTime" SG_ 386 MRR_FL_CAN_SMC_Field 1000;
BA_ "GenSigSendType" SG_ 386 MRR_FL_CAN_SMC_Promote 0;
BA_ "GenSigCycleTime" SG_ 386 MRR_FL_CAN_SMC_Promote 1000;
BA_ "GenSigSendType" SG_ 386 MRR_FL_CAN_SMC_Minor 0;
BA_ "GenSigCycleTime" SG_ 386 MRR_FL_CAN_SMC_Minor 1000;
BA_ "GenSigSendType" SG_ 386 MRR_FL_CAN_SMC_Major 0;
BA_ "GenSigCycleTime" SG_ 386 MRR_FL_CAN_SMC_Major 1000;
BA_ "GenSigCycleTime" SG_ 386 MRR_FL_CAN_TX_Field 1000;
BA_ "GenSigSendType" SG_ 386 MRR_FL_CAN_TX_Field 0;
BA_ "GenSigCycleTime" SG_ 386 MRR_FL_CAN_TX_Promote 1000;
BA_ "GenSigSendType" SG_ 386 MRR_FL_CAN_TX_Promote 0;
BA_ "GenSigCycleTime" SG_ 386 MRR_FL_CAN_TX_Major 1000;
BA_ "GenSigSendType" SG_ 386 MRR_FL_CAN_TX_Major 0;
BA_ "GenSigCycleTime" SG_ 386 MRR_FL_CAN_TX_Hardware 1000;
BA_ "GenSigSendType" SG_ 386 MRR_FL_CAN_TX_Hardware 0;
BA_ "GenSigCycleTime" SG_ 386 MRR_FL_CAN_TX_SERIAL_NUMBER_SEQU 1000;
BA_ "GenSigSendType" SG_ 386 MRR_FL_CAN_TX_SERIAL_NUMBER_SEQU 0;
BA_ "SystemSignalLongSymbol" SG_ 386 MRR_FL_CAN_TX_SERIAL_NUMBER_SEQU "MRR_FL_CAN_TX_SERIAL_NUMBER_SEQUENCE";
BA_ "GenSigCycleTime" SG_ 386 MRR_FL_CAN_TX_SERIAL_NUM_JULIAN_ 1000;
BA_ "GenSigSendType" SG_ 386 MRR_FL_CAN_TX_SERIAL_NUM_JULIAN_ 0;
BA_ "SystemSignalLongSymbol" SG_ 386 MRR_FL_CAN_TX_SERIAL_NUM_JULIAN_ "MRR_FL_CAN_TX_SERIAL_NUM_JULIAN_YEAR";
BA_ "GenSigCycleTime" SG_ 386 MRR_FL_CAN_TX_SERIAL_NUM_JU_0000 1000;
BA_ "GenSigSendType" SG_ 386 MRR_FL_CAN_TX_SERIAL_NUM_JU_0000 0;
BA_ "SystemSignalLongSymbol" SG_ 386 MRR_FL_CAN_TX_SERIAL_NUM_JU_0000 "MRR_FL_CAN_TX_SERIAL_NUM_JULIAN_DAY";
BA_ "GenSigCycleTime" SG_ 386 MRR_FL_CAN_TX_ARM_THROUGHPUT 1000;
BA_ "GenSigSendType" SG_ 386 MRR_FL_CAN_TX_ARM_THROUGHPUT 0;
BA_ "GenSigCycleTime" SG_ 386 MRR_FL_CAN_TX_SYSTEM_STATUS 1000;
BA_ "GenSigSendType" SG_ 386 MRR_FL_CAN_TX_SYSTEM_STATUS 0;
BA_ "GenSigCycleTime" SG_ 386 MRR_FL_CAN_TX_LOOK_TYPE_1 1000;
BA_ "GenSigSendType" SG_ 386 MRR_FL_CAN_TX_LOOK_TYPE_1 0;
BA_ "GenSigCycleTime" SG_ 386 MRR_FL_CAN_TX_OVERHEAT_ERROR 1000;
BA_ "GenSigSendType" SG_ 386 MRR_FL_CAN_TX_OVERHEAT_ERROR 0;
BA_ "GenSigCycleTime" SG_ 386 MRR_FL_CAN_TX_RANGE_PERF_ERROR 1000;
BA_ "GenSigSendType" SG_ 386 MRR_FL_CAN_TX_RANGE_PERF_ERROR 0;
BA_ "GenSigCycleTime" SG_ 386 MRR_FL_CAN_TX_COMM_ERROR 1000;
BA_ "GenSigSendType" SG_ 386 MRR_FL_CAN_TX_COMM_ERROR 0;
BA_ "GenSigCycleTime" SG_ 386 MRR_FL_CAN_TX_INTERNAL_ERROR 1000;
BA_ "GenSigSendType" SG_ 386 MRR_FL_CAN_TX_INTERNAL_ERROR 0;
BA_ "GenSigCycleTime" SG_ 386 MRR_FL_CAN_TX_XCVR_OPERATIONAL 1000;
BA_ "GenSigSendType" SG_ 386 MRR_FL_CAN_TX_XCVR_OPERATIONAL 0;
BA_ "GenSigSendType" SG_ 386 MRR_FL_CAN_PBL_Field_Revision 0;
BA_ "GenSigCycleTime" SG_ 386 MRR_FL_CAN_PBL_Field_Revision 1000;
BA_ "GenSigCycleTime" SG_ 386 MRR_FL_CAN_PBL_Promote_Revision 1000;
BA_ "GenSigSendType" SG_ 386 MRR_FL_CAN_PBL_Promote_Revision 0;
BA_ "GenSigCycleTime" SG_ 386 MRR_FL_CAN_SW_Field_Revision 1000;
BA_ "GenSigSendType" SG_ 386 MRR_FL_CAN_SW_Field_Revision 0;
BA_ "GenSigCycleTime" SG_ 386 MRR_FL_CAN_SW_Promote_Revision 1000;
BA_ "GenSigSendType" SG_ 386 MRR_FL_CAN_SW_Promote_Revision 0;
BA_ "GenSigCycleTime" SG_ 386 MRR_FL_CAN_SW_Field 1000;
BA_ "GenSigSendType" SG_ 386 MRR_FL_CAN_SW_Field 0;
BA_ "GenSigCycleTime" SG_ 386 MRR_FL_CAN_SW_Release_Revision 1000;
BA_ "GenSigSendType" SG_ 386 MRR_FL_CAN_SW_Release_Revision 0;
BA_ "GenSigCycleTime" SG_ 386 MRR_FL_CAN_PBL_Release_Revision 1000;
BA_ "GenSigSendType" SG_ 386 MRR_FL_CAN_PBL_Release_Revision 0;
BA_ "GenSigSendType" SG_ 387 MRR_FL_Alignment_Status_CRC 0;
BA_ "GenSigCycleTime" SG_ 387 MRR_FL_Alignment_Status_CRC 50;
BA_ "GenSigSendType" SG_ 387 MRR_FL_Alignment_Status_MC 0;
BA_ "GenSigCycleTime" SG_ 387 MRR_FL_Alignment_Status_MC 50;
BA_ "GenSigSendType" SG_ 387 MRR_FL_CAN_TX_DRIVING_ENVIRONMEN 0;
BA_ "GenSigCycleTime" SG_ 387 MRR_FL_CAN_TX_DRIVING_ENVIRONMEN 50;
BA_ "SystemSignalLongSymbol" SG_ 387 MRR_FL_CAN_TX_DRIVING_ENVIRONMEN "MRR_FL_CAN_TX_DRIVING_ENVIRONMENT";
BA_ "GenSigSendType" SG_ 387 MRR_FL_CAN_TX_ROLLING_COUNT_1 0;
BA_ "GenSigCycleTime" SG_ 387 MRR_FL_CAN_TX_ROLLING_COUNT_1 50;
BA_ "GenSigSendType" SG_ 387 MRR_FL_CAN_TX_Temperature 0;
BA_ "GenSigCycleTime" SG_ 387 MRR_FL_CAN_TX_Temperature 50;
BA_ "GenSigSendType" SG_ 387 MRR_FL_CAN_TX_YAW_RATE_BIAS 0;
BA_ "GenSigCycleTime" SG_ 387 MRR_FL_CAN_TX_YAW_RATE_BIAS 50;
BA_ "GenSigSendType" SG_ 387 MRR_FL_CAN_TX_VEH_SPD_COMP_FACTO 0;
BA_ "GenSigCycleTime" SG_ 387 MRR_FL_CAN_TX_VEH_SPD_COMP_FACTO 50;
BA_ "SystemSignalLongSymbol" SG_ 387 MRR_FL_CAN_TX_VEH_SPD_COMP_FACTO "MRR_FL_CAN_TX_VEH_SPD_COMP_FACTOR";
BA_ "GenSigSendType" SG_ 387 MRR_FL_CAN_TX_AUTO_ALIGN_QUA_FAC 0;
BA_ "GenSigCycleTime" SG_ 387 MRR_FL_CAN_TX_AUTO_ALIGN_QUA_FAC 50;
BA_ "SystemSignalLongSymbol" SG_ 387 MRR_FL_CAN_TX_AUTO_ALIGN_QUA_FAC "MRR_FL_CAN_TX_AUTO_ALIGN_QUA_FACTOR";
BA_ "GenSigSendType" SG_ 387 MRR_FL_CAN_TX_Alignment_MODE 0;
BA_ "GenSigCycleTime" SG_ 387 MRR_FL_CAN_TX_Alignment_MODE 50;
BA_ "GenSigSendType" SG_ 387 MRR_FL_CAN_TX_CURRENT_MISALIGN_A 0;
BA_ "GenSigCycleTime" SG_ 387 MRR_FL_CAN_TX_CURRENT_MISALIGN_A 50;
BA_ "SystemSignalLongSymbol" SG_ 387 MRR_FL_CAN_TX_CURRENT_MISALIGN_A "MRR_FL_CAN_TX_CURRENT_MISALIGN_ANGLE";
BA_ "GenSigSendType" SG_ 387 MRR_FL_CAN_TX_SAVED_MISALIGN_ANG 0;
BA_ "GenSigCycleTime" SG_ 387 MRR_FL_CAN_TX_SAVED_MISALIGN_ANG 50;
BA_ "SystemSignalLongSymbol" SG_ 387 MRR_FL_CAN_TX_SAVED_MISALIGN_ANG "MRR_FL_CAN_TX_SAVED_MISALIGN_ANGLE";
BA_ "GenSigSendType" SG_ 388 MRR_FL_TO_SystemTDBlockage_Flt 0;
BA_ "GenSigCycleTime" SG_ 388 MRR_FL_TO_SystemTDBlockage_Flt 20;
BA_ "GenSigCycleTime" SG_ 388 MRR_FL_TO_CADMSWVersion_Flt 20;
BA_ "GenSigSendType" SG_ 388 MRR_FL_TO_CADMSWVersion_Flt 0;
BA_ "GenSigCycleTime" SG_ 388 MRR_FL_TO_RADARCfgParameter_Flt 20;
BA_ "GenSigSendType" SG_ 388 MRR_FL_TO_RADARCfgParameter_Flt 0;
BA_ "GenSigCycleTime" SG_ 388 MRR_FL_TO_SATCADMVIN_Flt 20;
BA_ "GenSigSendType" SG_ 388 MRR_FL_TO_SATCADMVIN_Flt 0;
BA_ "GenSigCycleTime" SG_ 388 MRR_FL_TO_CADMTracksChange_Flt 20;
BA_ "GenSigSendType" SG_ 388 MRR_FL_TO_CADMTracksChange_Flt 0;
BA_ "GenSigCycleTime" SG_ 388 MRR_FL_Active_Fault_Status_CRC 20;
BA_ "GenSigSendType" SG_ 388 MRR_FL_Active_Fault_Status_CRC 0;
BA_ "GenSigCycleTime" SG_ 388 MRR_FL_Active_Fault_Status_MC 20;
BA_ "GenSigSendType" SG_ 388 MRR_FL_Active_Fault_Status_MC 0;
BA_ "GenSigCycleTime" SG_ 388 MRR_FL_Dolphin_Flt 20;
BA_ "GenSigSendType" SG_ 388 MRR_FL_Dolphin_Flt 0;
BA_ "GenSigCycleTime" SG_ 388 MRR_FL_RRUCore_Flt 20;
BA_ "GenSigSendType" SG_ 388 MRR_FL_RRUCore_Flt 0;
BA_ "GenSigCycleTime" SG_ 388 MRR_FL_RRUBIST_Flt 20;
BA_ "GenSigSendType" SG_ 388 MRR_FL_RRUBIST_Flt 0;
BA_ "GenSigCycleTime" SG_ 388 MRR_FL_PINPosition_Flt 20;
BA_ "GenSigSendType" SG_ 388 MRR_FL_PINPosition_Flt 0;
BA_ "GenSigCycleTime" SG_ 388 MRR_FL_PCANDataRangeChk_Flt 20;
BA_ "GenSigSendType" SG_ 388 MRR_FL_PCANDataRangeChk_Flt 0;
BA_ "GenSigSendType" SG_ 388 MRR_FL_TO_AngleAdjustmentTable_F 0;
BA_ "GenSigCycleTime" SG_ 388 MRR_FL_TO_AngleAdjustmentTable_F 20;
BA_ "SystemSignalLongSymbol" SG_ 388 MRR_FL_TO_AngleAdjustmentTable_F "MRR_FL_TO_AngleAdjustmentTable_Flt";
BA_ "GenSigSendType" SG_ 388 MRR_FL_TO_CADMSgnlActlVal_Flt 0;
BA_ "GenSigCycleTime" SG_ 388 MRR_FL_TO_CADMSgnlActlVal_Flt 20;
BA_ "GenSigSendType" SG_ 388 MRR_FL_TO_TrigControl_Flt 0;
BA_ "GenSigCycleTime" SG_ 388 MRR_FL_TO_TrigControl_Flt 20;
BA_ "GenSigSendType" SG_ 388 MRR_FL_TO_VehicleState_Flt 0;
BA_ "GenSigCycleTime" SG_ 388 MRR_FL_TO_VehicleState_Flt 20;
BA_ "GenSigSendType" SG_ 388 MRR_FL_MC_AngleAdjTable_Flt 0;
BA_ "GenSigCycleTime" SG_ 388 MRR_FL_MC_AngleAdjTable_Flt 20;
BA_ "GenSigSendType" SG_ 388 MRR_FL_CRC_AngleAdjTable_Flt 0;
BA_ "GenSigCycleTime" SG_ 388 MRR_FL_CRC_AngleAdjTable_Flt 20;
BA_ "GenSigSendType" SG_ 388 MRR_FL_MC_VehicleState_Flt 0;
BA_ "GenSigCycleTime" SG_ 388 MRR_FL_MC_VehicleState_Flt 20;
BA_ "GenSigSendType" SG_ 388 MRR_FL_CRC_VehicleState_Flt 0;
BA_ "GenSigCycleTime" SG_ 388 MRR_FL_CRC_VehicleState_Flt 20;
BA_ "GenSigSendType" SG_ 388 MRR_FL_MC_TrigControl_Flt 0;
BA_ "GenSigCycleTime" SG_ 388 MRR_FL_MC_TrigControl_Flt 20;
BA_ "GenSigSendType" SG_ 388 MRR_FL_CRC_TrigControl_Flt 0;
BA_ "GenSigCycleTime" SG_ 388 MRR_FL_CRC_TrigControl_Flt 20;
BA_ "GenSigSendType" SG_ 388 MRR_FL_CRC_RadarCfgParameter_Flt 0;
BA_ "GenSigCycleTime" SG_ 388 MRR_FL_CRC_RadarCfgParameter_Flt 20;
BA_ "GenSigSendType" SG_ 388 MRR_FL_MC_CADMSgnlActlVal_Flt 0;
BA_ "GenSigCycleTime" SG_ 388 MRR_FL_MC_CADMSgnlActlVal_Flt 20;
BA_ "GenSigSendType" SG_ 388 MRR_FL_CRC_CADMSgnlActlVal_Flt 0;
BA_ "GenSigCycleTime" SG_ 388 MRR_FL_CRC_CADMSgnlActlVal_Flt 20;
BA_ "GenSigSendType" SG_ 388 MRR_FL_VINSignalCompare_Flt 0;
BA_ "GenSigCycleTime" SG_ 388 MRR_FL_VINSignalCompare_Flt 20;
BA_ "GenSigSendType" SG_ 388 MRR_FL_BatteryLow_Flt 0;
BA_ "GenSigCycleTime" SG_ 388 MRR_FL_BatteryLow_Flt 20;
BA_ "GenSigSendType" SG_ 388 MRR_FL_BatteryHigh_Flt 0;
BA_ "GenSigCycleTime" SG_ 388 MRR_FL_BatteryHigh_Flt 20;
BA_ "GenSigSendType" SG_ 388 MRR_FL_Core0_To_Core1_IPC_Flt 0;
BA_ "GenSigCycleTime" SG_ 388 MRR_FL_Core0_To_Core1_IPC_Flt 20;
BA_ "GenSigCycleTime" SG_ 388 MRR_FL_Core1_To_Core0_IPC_Flt 20;
BA_ "GenSigSendType" SG_ 388 MRR_FL_Core1_To_Core0_IPC_Flt 0;
BA_ "GenSigCycleTime" SG_ 388 MRR_FL_Core1_To_Core2_IPC_Flt 20;
BA_ "GenSigSendType" SG_ 388 MRR_FL_Core1_To_Core2_IPC_Flt 0;
BA_ "GenSigCycleTime" SG_ 388 MRR_FL_Core2_To_Core1_IPC_Flt 20;
BA_ "GenSigSendType" SG_ 388 MRR_FL_Core2_To_Core1_IPC_Flt 0;
BA_ "GenSigCycleTime" SG_ 388 MRR_FL_Core2_To_Core0_IPC_Flt 20;
BA_ "GenSigSendType" SG_ 388 MRR_FL_Core2_To_Core0_IPC_Flt 0;
BA_ "GenSigCycleTime" SG_ 388 MRR_FL_Core2Halted_Flt 20;
BA_ "GenSigSendType" SG_ 388 MRR_FL_Core2Halted_Flt 0;
BA_ "GenSigCycleTime" SG_ 388 MRR_FL_Core1Halted_Flt 20;
BA_ "GenSigSendType" SG_ 388 MRR_FL_Core1Halted_Flt 0;
BA_ "GenSigCycleTime" SG_ 388 MRR_FL_LocalOscPower_Flt 20;
BA_ "GenSigSendType" SG_ 388 MRR_FL_LocalOscPower_Flt 0;
BA_ "GenSigCycleTime" SG_ 388 MRR_FL_DSPLoopOverrun_Flt 20;
BA_ "GenSigSendType" SG_ 388 MRR_FL_DSPLoopOverrun_Flt 0;
BA_ "GenSigCycleTime" SG_ 388 MRR_FL_TransmitterPower_Flt 20;
BA_ "GenSigSendType" SG_ 388 MRR_FL_TransmitterPower_Flt 0;
BA_ "GenSigCycleTime" SG_ 388 MRR_FL_Core0_To_Core2_IPC_Flt 20;
BA_ "GenSigSendType" SG_ 388 MRR_FL_Core0_To_Core2_IPC_Flt 0;
BA_ "GenSigCycleTime" SG_ 388 MRR_FL_XCVRDeviceSPI_Flt 20;
BA_ "GenSigSendType" SG_ 388 MRR_FL_XCVRDeviceSPI_Flt 0;
BA_ "GenSigCycleTime" SG_ 388 MRR_FL_MNRBlockage_Flt 20;
BA_ "GenSigSendType" SG_ 388 MRR_FL_MNRBlockage_Flt 0;
BA_ "GenSigCycleTime" SG_ 388 MRR_FL_TransmitterTempHigh_Flt 20;
BA_ "GenSigSendType" SG_ 388 MRR_FL_TransmitterTempHigh_Flt 0;
BA_ "GenSigCycleTime" SG_ 388 MRR_FL_AlignRoutineFailed_Flt 20;
BA_ "GenSigSendType" SG_ 388 MRR_FL_AlignRoutineFailed_Flt 0;
BA_ "GenSigCycleTime" SG_ 388 MRR_FL_MicroTempHigh_Flt 20;
BA_ "GenSigSendType" SG_ 388 MRR_FL_MicroTempHigh_Flt 0;
BA_ "GenSigCycleTime" SG_ 388 MRR_FL_HAlignOutofRange_Flt 20;
BA_ "GenSigSendType" SG_ 388 MRR_FL_HAlignOutofRange_Flt 0;
BA_ "GenSigCycleTime" SG_ 388 MRR_FL_v1p1_SupplyOutOfRange_Flt 20;
BA_ "GenSigSendType" SG_ 388 MRR_FL_v1p1_SupplyOutOfRange_Flt 0;
BA_ "GenSigCycleTime" SG_ 388 MRR_FL_v1p25_SupplyOutOfRange_Fl 20;
BA_ "GenSigSendType" SG_ 388 MRR_FL_v1p25_SupplyOutOfRange_Fl 0;
BA_ "SystemSignalLongSymbol" SG_ 388 MRR_FL_v1p25_SupplyOutOfRange_Fl "MRR_FL_v1p25_SupplyOutOfRange_Flt";
BA_ "GenSigCycleTime" SG_ 388 MRR_FL_v1p8_SupplyOutOfRange_Flt 20;
BA_ "GenSigSendType" SG_ 388 MRR_FL_v1p8_SupplyOutOfRange_Flt 0;
BA_ "GenSigCycleTime" SG_ 388 MRR_FL_v2p3_SupplyOutOfRange_Flt 20;
BA_ "GenSigSendType" SG_ 388 MRR_FL_v2p3_SupplyOutOfRange_Flt 0;
BA_ "GenSigCycleTime" SG_ 388 MRR_FL_v_5_SupplyOutOfRange_Flt 20;
BA_ "GenSigSendType" SG_ 388 MRR_FL_v_5_SupplyOutOfRange_Flt 0;
BA_ "GenSigCycleTime" SG_ 388 MRR_FL_TransmitterID_Flt 20;
BA_ "GenSigSendType" SG_ 388 MRR_FL_TransmitterID_Flt 0;
BA_ "GenSigCycleTime" SG_ 388 MRR_FL_PCANBusOff_Flt 20;
BA_ "GenSigSendType" SG_ 388 MRR_FL_PCANBusOff_Flt 0;
BA_ "GenSigCycleTime" SG_ 388 MRR_FL_InstructionSetCheck_Flt 20;
BA_ "GenSigSendType" SG_ 388 MRR_FL_InstructionSetCheck_Flt 0;
BA_ "GenSigCycleTime" SG_ 388 MRR_FL_StackOverflow_Flt 20;
BA_ "GenSigSendType" SG_ 388 MRR_FL_StackOverflow_Flt 0;
BA_ "GenSigCycleTime" SG_ 388 MRR_FL_Watchdog_Flt 20;
BA_ "GenSigSendType" SG_ 388 MRR_FL_Watchdog_Flt 0;
BA_ "GenSigCycleTime" SG_ 388 MRR_FL_PLLLock_Flt 20;
BA_ "GenSigSendType" SG_ 388 MRR_FL_PLLLock_Flt 0;
BA_ "GenSigCycleTime" SG_ 388 MRR_FL_RAMMemoryTest_Flt 20;
BA_ "GenSigSendType" SG_ 388 MRR_FL_RAMMemoryTest_Flt 0;
BA_ "GenSigVtEn" SG_ 388 MRR_FL_USCValidation_Flt "*";
BA_ "GenSigCycleTime" SG_ 388 MRR_FL_USCValidation_Flt 20;
BA_ "GenSigSendType" SG_ 388 MRR_FL_USCValidation_Flt 0;
BA_ "GenSigCycleTime" SG_ 388 MRR_FL_SMCChecksum_Flt 20;
BA_ "GenSigSendType" SG_ 388 MRR_FL_SMCChecksum_Flt 0;
BA_ "GenSigCycleTime" SG_ 388 MRR_FL_KeepAliveChecksum_Flt 20;
BA_ "GenSigSendType" SG_ 388 MRR_FL_KeepAliveChecksum_Flt 0;
BA_ "GenSigCycleTime" SG_ 388 MRR_FL_ApplicationFlashChksum_Fl 20;
BA_ "GenSigSendType" SG_ 388 MRR_FL_ApplicationFlashChksum_Fl 0;
BA_ "SystemSignalLongSymbol" SG_ 388 MRR_FL_ApplicationFlashChksum_Fl "MRR_FL_ApplicationFlashChksum_Flt";
BA_ "GenSigSendType" SG_ 389 MRR_FL_XBAR_cfg_failure 0;
BA_ "GenSigCycleTime" SG_ 389 MRR_FL_XBAR_cfg_failure 20;
BA_ "GenSigSendType" SG_ 389 MRR_FL_Stack_OVF_fault_reason 0;
BA_ "GenSigCycleTime" SG_ 389 MRR_FL_Stack_OVF_fault_reason 20;
BA_ "GenSigSendType" SG_ 389 MRR_FL_App_flash_checksum_reason 0;
BA_ "GenSigCycleTime" SG_ 389 MRR_FL_App_flash_checksum_reason 20;
BA_ "GenSigSendType" SG_ 389 MRR_FL_KAM_fault_reason 0;
BA_ "GenSigCycleTime" SG_ 389 MRR_FL_KAM_fault_reason 20;
BA_ "GenSigSendType" SG_ 389 MRR_FL_RRU_Self_Test_Faults_reas 0;
BA_ "GenSigCycleTime" SG_ 389 MRR_FL_RRU_Self_Test_Faults_reas 20;
BA_ "SystemSignalLongSymbol" SG_ 389 MRR_FL_RRU_Self_Test_Faults_reas "MRR_FL_RRU_Self_Test_Faults_reason1";
BA_ "GenSigSendType" SG_ 389 MRR_FL_RRU_Core_Faults_reason3 0;
BA_ "GenSigCycleTime" SG_ 389 MRR_FL_RRU_Core_Faults_reason3 20;
BA_ "GenSigSendType" SG_ 389 MRR_FL_RRU_Core_Faults_reason2 0;
BA_ "GenSigCycleTime" SG_ 389 MRR_FL_RRU_Core_Faults_reason2 20;
BA_ "GenSigSendType" SG_ 389 MRR_FL_RRU_Core_Faults_reason1 0;
BA_ "GenSigCycleTime" SG_ 389 MRR_FL_RRU_Core_Faults_reason1 20;
BA_ "GenSigSendType" SG_ 389 MRR_FL_Rx_Radar_Mount_Msg_Fault 0;
BA_ "GenSigCycleTime" SG_ 389 MRR_FL_Rx_Radar_Mount_Msg_Fault 20;
BA_ "GenSigCycleTime" SG_ 389 MRR_FL_Dolphin_Fault_Detection 20;
BA_ "GenSigSendType" SG_ 389 MRR_FL_Dolphin_Fault_Detection 0;
BA_ "GenSigSendType" SG_ 389 MRR_FL_RRU_Self_Test_Faults_0000 0;
BA_ "GenSigCycleTime" SG_ 389 MRR_FL_RRU_Self_Test_Faults_0000 20;
BA_ "SystemSignalLongSymbol" SG_ 389 MRR_FL_RRU_Self_Test_Faults_0000 "MRR_FL_RRU_Self_Test_Faults_reason0";
BA_ "GenSigSendType" SG_ 389 MRR_FL_RRU_Core_Faults_reason0 0;
BA_ "GenSigCycleTime" SG_ 389 MRR_FL_RRU_Core_Faults_reason0 20;
BA_ "GenSigSendType" SG_ 389 MRR_FL_USC_Load_Error 0;
BA_ "GenSigCycleTime" SG_ 389 MRR_FL_USC_Load_Error 20;
BA_ "GenSigSendType" SG_ 389 MRR_FL_SMC_Load_Error 0;
BA_ "GenSigCycleTime" SG_ 389 MRR_FL_SMC_Load_Error 20;
BA_ "GenSigCycleTime" SG_ 389 MRR_FL_TX_Temperature_Flt 20;
BA_ "GenSigSendType" SG_ 389 MRR_FL_TX_Temperature_Flt 0;
BA_ "GenSigSendType" SG_ 389 MRR_FL_Dsp_Unit_Cal_Blk_Chcksm_E 0;
BA_ "GenSigCycleTime" SG_ 389 MRR_FL_Dsp_Unit_Cal_Blk_Chcksm_E 20;
BA_ "SystemSignalLongSymbol" SG_ 389 MRR_FL_Dsp_Unit_Cal_Blk_Chcksm_E "MRR_FL_Dsp_Unit_Cal_Blk_Chcksm_Error";
BA_ "GenSigSendType" SG_ 389 MRR_FL_Dsp_Unit_Cal_Checksum_Err 0;
BA_ "GenSigCycleTime" SG_ 389 MRR_FL_Dsp_Unit_Cal_Checksum_Err 20;
BA_ "SystemSignalLongSymbol" SG_ 389 MRR_FL_Dsp_Unit_Cal_Checksum_Err "MRR_FL_Dsp_Unit_Cal_Checksum_Error";
BA_ "GenSigSendType" SG_ 389 MRR_FL_Vertical_Misalignment_err 0;
BA_ "GenSigCycleTime" SG_ 389 MRR_FL_Vertical_Misalignment_err 20;
BA_ "SystemSignalLongSymbol" SG_ 389 MRR_FL_Vertical_Misalignment_err "MRR_FL_Vertical_Misalignment_error";
BA_ "GenSigSendType" SG_ 389 MRR_FL_RTN_SPI_Transfer_Error 0;
BA_ "GenSigCycleTime" SG_ 389 MRR_FL_RTN_SPI_Transfer_Error 20;
BA_ "GenSigSendType" SG_ 389 MRR_FL_RRN_SPI_Transfer_Error 0;
BA_ "GenSigCycleTime" SG_ 389 MRR_FL_RRN_SPI_Transfer_Error 20;
BA_ "GenSigSendType" SG_ 389 MRR_FL_Linearizer_SPI_Transfer_E 0;
BA_ "GenSigCycleTime" SG_ 389 MRR_FL_Linearizer_SPI_Transfer_E 20;
BA_ "SystemSignalLongSymbol" SG_ 389 MRR_FL_Linearizer_SPI_Transfer_E "MRR_FL_Linearizer_SPI_Transfer_Error";
BA_ "GenSigSendType" SG_ 389 MRR_FL_ADC_SPI_Transfer_Error 0;
BA_ "GenSigCycleTime" SG_ 389 MRR_FL_ADC_SPI_Transfer_Error 20;
BA_ "GenSigSendType" SG_ 389 MRR_FL_Transmitter_ID_Error 0;
BA_ "GenSigCycleTime" SG_ 389 MRR_FL_Transmitter_ID_Error 20;
BA_ "GenSigSendType" SG_ 389 MRR_FL_Dsp_Loop_Overrun_Error 0;
BA_ "GenSigCycleTime" SG_ 389 MRR_FL_Dsp_Loop_Overrun_Error 20;
BA_ "GenSigSendType" SG_ 389 MRR_FL_Saturated_Tuning_Freq_Err 0;
BA_ "GenSigCycleTime" SG_ 389 MRR_FL_Saturated_Tuning_Freq_Err 20;
BA_ "SystemSignalLongSymbol" SG_ 389 MRR_FL_Saturated_Tuning_Freq_Err "MRR_FL_Saturated_Tuning_Freq_Error";
BA_ "GenSigSendType" SG_ 389 MRR_FL_Radar_Data_sync_error 0;
BA_ "GenSigCycleTime" SG_ 389 MRR_FL_Radar_Data_sync_error 20;
BA_ "GenSigSendType" SG_ 389 MRR_FL_Dsp_Tuning_Sensitivity_Er 0;
BA_ "GenSigCycleTime" SG_ 389 MRR_FL_Dsp_Tuning_Sensitivity_Er 20;
BA_ "SystemSignalLongSymbol" SG_ 389 MRR_FL_Dsp_Tuning_Sensitivity_Er "MRR_FL_Dsp_Tuning_Sensitivity_Error";
BA_ "GenSigSendType" SG_ 389 MRR_FL_Radar_LO_Power_Error 0;
BA_ "GenSigCycleTime" SG_ 389 MRR_FL_Radar_LO_Power_Error 20;
BA_ "GenSigSendType" SG_ 389 MRR_FL_Radar_TX_Power_Error 0;
BA_ "GenSigCycleTime" SG_ 389 MRR_FL_Radar_TX_Power_Error 20;
BA_ "GenSigSendType" SG_ 389 MRR_FL_Timer_Create_Error 0;
BA_ "GenSigCycleTime" SG_ 389 MRR_FL_Timer_Create_Error 20;
BA_ "GenSigSendType" SG_ 389 MRR_FL_Thread_Create_Error 0;
BA_ "GenSigCycleTime" SG_ 389 MRR_FL_Thread_Create_Error 20;
BA_ "GenSigSendType" SG_ 389 MRR_FL_ARM_Calibration_Error 0;
BA_ "GenSigCycleTime" SG_ 389 MRR_FL_ARM_Calibration_Error 20;
BA_ "GenSigSendType" SG_ 389 MRR_FL_SPI_FEE_Error 0;
BA_ "GenSigCycleTime" SG_ 389 MRR_FL_SPI_FEE_Error 20;
BA_ "GenSigSendType" SG_ 389 MRR_FL_SPI_Comm_Error 0;
BA_ "GenSigCycleTime" SG_ 389 MRR_FL_SPI_Comm_Error 20;
BA_ "GenSigSendType" SG_ 389 MRR_FL_Socket_Write_Error 0;
BA_ "GenSigCycleTime" SG_ 389 MRR_FL_Socket_Write_Error 20;
BA_ "GenSigSendType" SG_ 389 MRR_FL_Socket_Read_error 0;
BA_ "GenSigCycleTime" SG_ 389 MRR_FL_Socket_Read_error 20;
BA_ "GenSigSendType" SG_ 389 MRR_FL_Socket_Init_Error 0;
BA_ "GenSigCycleTime" SG_ 389 MRR_FL_Socket_Init_Error 20;
BA_ "GenSigSendType" SG_ 389 MRR_FL_Signal_Wait_Error 0;
BA_ "GenSigCycleTime" SG_ 389 MRR_FL_Signal_Wait_Error 20;
BA_ "GenSigSendType" SG_ 389 MRR_FL_Signal_Send_Error 0;
BA_ "GenSigCycleTime" SG_ 389 MRR_FL_Signal_Send_Error 20;
BA_ "GenSigSendType" SG_ 389 MRR_FL_Signal_Create_Error 0;
BA_ "GenSigCycleTime" SG_ 389 MRR_FL_Signal_Create_Error 20;
BA_ "GenSigSendType" SG_ 389 MRR_FL_Shared_Mem_Write_Error 0;
BA_ "GenSigCycleTime" SG_ 389 MRR_FL_Shared_Mem_Write_Error 20;
BA_ "GenSigSendType" SG_ 389 MRR_FL_Shared_Mem_Read_Error 0;
BA_ "GenSigCycleTime" SG_ 389 MRR_FL_Shared_Mem_Read_Error 20;
BA_ "GenSigSendType" SG_ 389 MRR_FL_Shared_Mem_Config_Error 0;
BA_ "GenSigCycleTime" SG_ 389 MRR_FL_Shared_Mem_Config_Error 20;
BA_ "GenSigSendType" SG_ 389 MRR_FL_Share_Mem_Init_Error 0;
BA_ "GenSigCycleTime" SG_ 389 MRR_FL_Share_Mem_Init_Error 20;
BA_ "GenSigSendType" SG_ 389 MRR_FL_RAM_Test_Error 0;
BA_ "GenSigCycleTime" SG_ 389 MRR_FL_RAM_Test_Error 20;
BA_ "GenSigSendType" SG_ 389 MRR_FL_Num_Errors 0;
BA_ "GenSigCycleTime" SG_ 389 MRR_FL_Num_Errors 20;
BA_ "GenSigSendType" SG_ 389 MRR_FL_MMAP_Memory_Error 0;
BA_ "GenSigCycleTime" SG_ 389 MRR_FL_MMAP_Memory_Error 20;
BA_ "GenSigSendType" SG_ 389 MRR_FL_ISR_Attach_Error 0;
BA_ "GenSigCycleTime" SG_ 389 MRR_FL_ISR_Attach_Error 20;
BA_ "GenSigSendType" SG_ 389 MRR_FL_IPC_DRV_Write_Error 0;
BA_ "GenSigCycleTime" SG_ 389 MRR_FL_IPC_DRV_Write_Error 20;
BA_ "GenSigSendType" SG_ 389 MRR_FL_IPC_DRV_Trigger_Error 0;
BA_ "GenSigCycleTime" SG_ 389 MRR_FL_IPC_DRV_Trigger_Error 20;
BA_ "GenSigSendType" SG_ 389 MRR_FL_IPC_DRV_Sync_Error 0;
BA_ "GenSigCycleTime" SG_ 389 MRR_FL_IPC_DRV_Sync_Error 20;
BA_ "GenSigSendType" SG_ 389 MRR_FL_IPC_DRV_Read_Error 0;
BA_ "GenSigCycleTime" SG_ 389 MRR_FL_IPC_DRV_Read_Error 20;
BA_ "GenSigSendType" SG_ 389 MRR_FL_IPC_DRV_Init_Error 0;
BA_ "GenSigCycleTime" SG_ 389 MRR_FL_IPC_DRV_Init_Error 20;
BA_ "GenSigSendType" SG_ 389 MRR_FL_Interrupt_Enable_Error 0;
BA_ "GenSigCycleTime" SG_ 389 MRR_FL_Interrupt_Enable_Error 20;
BA_ "GenSigSendType" SG_ 389 MRR_FL_HIL_Format_Error 0;
BA_ "GenSigCycleTime" SG_ 389 MRR_FL_HIL_Format_Error 20;
BA_ "GenSigSendType" SG_ 389 MRR_FL_Flash_Filesystem_Error 0;
BA_ "GenSigCycleTime" SG_ 389 MRR_FL_Flash_Filesystem_Error 20;
BA_ "GenSigSendType" SG_ 389 MRR_FL_Error_none 0;
BA_ "GenSigCycleTime" SG_ 389 MRR_FL_Error_none 20;
BA_ "GenSigSendType" SG_ 389 MRR_FL_Dsp_Load_Read_Error 0;
BA_ "GenSigCycleTime" SG_ 389 MRR_FL_Dsp_Load_Read_Error 20;
BA_ "GenSigSendType" SG_ 389 MRR_FL_Dsp_Load_Open_Error 0;
BA_ "GenSigCycleTime" SG_ 389 MRR_FL_Dsp_Load_Open_Error 20;
BA_ "GenSigSendType" SG_ 389 MRR_FL_Dsp_Load_Address_Error 0;
BA_ "GenSigCycleTime" SG_ 389 MRR_FL_Dsp_Load_Address_Error 20;
BA_ "GenSigSendType" SG_ 389 MRR_FL_Dsp_ISP_Write_Error 0;
BA_ "GenSigCycleTime" SG_ 389 MRR_FL_Dsp_ISP_Write_Error 20;
BA_ "GenSigSendType" SG_ 389 MRR_FL_Dsp_IPC_Read_Error 0;
BA_ "GenSigCycleTime" SG_ 389 MRR_FL_Dsp_IPC_Read_Error 20;
BA_ "GenSigSendType" SG_ 389 MRR_FL_Dsp_IPC_Init 0;
BA_ "GenSigCycleTime" SG_ 389 MRR_FL_Dsp_IPC_Init 20;
BA_ "GenSigSendType" SG_ 389 MRR_FL_Dsp_Init_Error 0;
BA_ "GenSigCycleTime" SG_ 389 MRR_FL_Dsp_Init_Error 20;
BA_ "GenSigSendType" SG_ 389 MRR_FL_Dsp_DRV_Start_Error 0;
BA_ "GenSigCycleTime" SG_ 389 MRR_FL_Dsp_DRV_Start_Error 20;
BA_ "GenSigSendType" SG_ 389 MRR_FL_Dsp_DRV_Load_Error 0;
BA_ "GenSigCycleTime" SG_ 389 MRR_FL_Dsp_DRV_Load_Error 20;
BA_ "GenSigSendType" SG_ 389 MRR_FL_Dsp_DRV_Init_Error 0;
BA_ "GenSigCycleTime" SG_ 389 MRR_FL_Dsp_DRV_Init_Error 20;
BA_ "GenSigSendType" SG_ 389 MRR_FL_Dsp_DRV_Init2_error 0;
BA_ "GenSigCycleTime" SG_ 389 MRR_FL_Dsp_DRV_Init2_error 20;
BA_ "GenSigSendType" SG_ 389 MRR_FL_Dsp_DRV_Init1_error 0;
BA_ "GenSigCycleTime" SG_ 389 MRR_FL_Dsp_DRV_Init1_error 20;
BA_ "GenSigSendType" SG_ 389 MRR_FL_CAN_XMT_Error 0;
BA_ "GenSigCycleTime" SG_ 389 MRR_FL_CAN_XMT_Error 20;
BA_ "GenSigSendType" SG_ 389 MRR_FL_CAN_RCV_Error 0;
BA_ "GenSigCycleTime" SG_ 389 MRR_FL_CAN_RCV_Error 20;
BA_ "GenSigSendType" SG_ 389 MRR_FL_CAN_Hardware_Error 0;
BA_ "GenSigCycleTime" SG_ 389 MRR_FL_CAN_Hardware_Error 20;
BA_ "GenSigSendType" SG_ 389 MRR_FL_Always_True 0;
BA_ "GenSigCycleTime" SG_ 389 MRR_FL_Always_True 20;
BA_ "GenSigSendType" SG_ 392 MRR_CAN_RadarWaveform_FL 1;
BA_ "GenSigCmt" SG_ 392 MRR_FL_CAN_RANGE_COVERAGE "CAN range coverage";
BA_ "GenSigCmt" SG_ 392 MRR_FL_CAN_DOPPLER_COVERAGE "CAN range coverage";
BA_ "GenSigCmt" SG_ 392 MRR_FL_CAN_FOV_HOR "CAN range coverage";
BA_ "GenSigCmt" SG_ 392 MRR_FL_CAN_FOV_VER "CAN range coverage";
BA_ "GenSigCycleTime" SG_ 397 MRR_FL_CAN_Dolphin_AFC 100;
BA_ "GenSigSendType" SG_ 397 MRR_FL_CAN_Dolphin_AFC 0;
BA_ "GenSigCycleTime" SG_ 397 MRR_FL_CAN_Dolphin_Tx3 100;
BA_ "GenSigSendType" SG_ 397 MRR_FL_CAN_Dolphin_Tx3 0;
BA_ "GenSigCycleTime" SG_ 397 MRR_FL_CAN_Dolphin_Tx2 100;
BA_ "GenSigSendType" SG_ 397 MRR_FL_CAN_Dolphin_Tx2 0;
BA_ "GenSigCycleTime" SG_ 397 MRR_FL_CAN_1_8_V 100;
BA_ "GenSigSendType" SG_ 397 MRR_FL_CAN_1_8_V 0;
BA_ "GenSigCycleTime" SG_ 397 MRR_FL_CAN_BATT_VOLTS 100;
BA_ "GenSigSendType" SG_ 397 MRR_FL_CAN_BATT_VOLTS 0;
BA_ "GenSigCycleTime" SG_ 397 MRR_FL_CAN_1_25_V 100;
BA_ "GenSigSendType" SG_ 397 MRR_FL_CAN_1_25_V 0;
BA_ "GenSigCycleTime" SG_ 397 MRR_FL_CAN_5_V 100;
BA_ "GenSigSendType" SG_ 397 MRR_FL_CAN_5_V 0;
BA_ "GenSigCycleTime" SG_ 397 MRR_FL_CAN_1_1_V 100;
BA_ "GenSigSendType" SG_ 397 MRR_FL_CAN_1_1_V 0;
BA_ "GenSigCycleTime" SG_ 397 MRR_FL_CAN_2_3_V 100;
BA_ "GenSigSendType" SG_ 397 MRR_FL_CAN_2_3_V 0;
BA_ "GenSigCycleTime" SG_ 397 MRR_FL_CAN_Dolphin_Tx1 100;
BA_ "GenSigSendType" SG_ 397 MRR_FL_CAN_Dolphin_Tx1 0;
BA_ "GenSigCycleTime" SG_ 397 MRR_FL_CAN_RRU_Temp1 100;
BA_ "GenSigSendType" SG_ 397 MRR_FL_CAN_RRU_Temp1 0;
BA_ "SystemSignalLongSymbol" SG_ 448 MRR_FR_CAN_TX_VEH_SPEED_DIRECTIO "MRR_FR_CAN_TX_VEH_SPEED_DIRECTION";
BA_ "SystemSignalLongSymbol" SG_ 448 MRR_FR_CAN_TX_STEERING_ANGLE_SIG "MRR_FR_CAN_TX_STEERING_ANGLE_SIGN";
BA_ "GenSigSendType" SG_ 448 MRR_FR_CAN_TX_STEERING_ANGLE 1;
BA_ "GenSigCycleTime" SG_ 449 MRR_FR_Dolphin_Chip_ID_Part2 1000;
BA_ "GenSigSendType" SG_ 449 MRR_FR_Dolphin_Chip_ID_Part2 0;
BA_ "GenSigCycleTime" SG_ 449 MRR_FR_Dolphin_Chip_ID_Part1 1000;
BA_ "GenSigSendType" SG_ 449 MRR_FR_Dolphin_Chip_ID_Part1 0;
BA_ "GenSigCycleTime" SG_ 449 MRR_FR_RRU_Chip_ID_Part4 1000;
BA_ "GenSigSendType" SG_ 449 MRR_FR_RRU_Chip_ID_Part4 0;
BA_ "GenSigCycleTime" SG_ 449 MRR_FR_RRU_Chip_ID_Part3 1000;
BA_ "GenSigSendType" SG_ 449 MRR_FR_RRU_Chip_ID_Part3 0;
BA_ "GenSigCycleTime" SG_ 449 MRR_FR_RRU_Chip_ID_Part2 1000;
BA_ "GenSigSendType" SG_ 449 MRR_FR_RRU_Chip_ID_Part2 0;
BA_ "GenSigCycleTime" SG_ 449 MRR_FR_RRU_Chip_ID_Part1 1000;
BA_ "GenSigSendType" SG_ 449 MRR_FR_RRU_Chip_ID_Part1 0;
BA_ "GenSigCycleTime" SG_ 449 MRR_FR_CAN_TX_HW_VERSION 1000;
BA_ "GenSigSendType" SG_ 449 MRR_FR_CAN_TX_HW_VERSION 0;
BA_ "GenSigCycleTime" SG_ 450 MRR_FR_CAN_PCAN_PROTOCOL_PROMOTE 1000;
BA_ "GenSigSendType" SG_ 450 MRR_FR_CAN_PCAN_PROTOCOL_PROMOTE 0;
BA_ "GenSigSendType" SG_ 450 MRR_FR_CAN_TX_SW_VERSION_DSP 0;
BA_ "GenSigCycleTime" SG_ 450 MRR_FR_CAN_TX_SW_VERSION_DSP 1000;
BA_ "GenSigCycleTime" SG_ 450 MRR_FR_CAN_TX_SW_VERSION_ARM 1000;
BA_ "GenSigSendType" SG_ 450 MRR_FR_CAN_TX_SW_VERSION_ARM 0;
BA_ "GenSigCycleTime" SG_ 450 MRR_FR_CAN_TX_PCAN_PROTOCOL_MINO 1000;
BA_ "GenSigSendType" SG_ 450 MRR_FR_CAN_TX_PCAN_PROTOCOL_MINO 0;
BA_ "SystemSignalLongSymbol" SG_ 450 MRR_FR_CAN_TX_PCAN_PROTOCOL_MINO "MRR_FR_CAN_TX_PCAN_PROTOCOL_MINOR";
BA_ "GenSigCycleTime" SG_ 450 MRR_FR_CAN_TX_PCAN_PROTOCOL_MAJO 1000;
BA_ "GenSigSendType" SG_ 450 MRR_FR_CAN_TX_PCAN_PROTOCOL_MAJO 0;
BA_ "SystemSignalLongSymbol" SG_ 450 MRR_FR_CAN_TX_PCAN_PROTOCOL_MAJO "MRR_FR_CAN_TX_PCAN_PROTOCOL_MAJOR";
BA_ "GenSigCycleTime" SG_ 450 MRR_FR_CAN_Dyn_Align_Algorithm_V 1000;
BA_ "GenSigSendType" SG_ 450 MRR_FR_CAN_Dyn_Align_Algorithm_V 0;
BA_ "SystemSignalLongSymbol" SG_ 450 MRR_FR_CAN_Dyn_Align_Algorithm_V "MRR_FR_CAN_Dyn_Align_Algorithm_Version_Major";
BA_ "GenSigCycleTime" SG_ 450 MRR_FR_CAN_Dyn_Align_Algori_0000 1000;
BA_ "GenSigSendType" SG_ 450 MRR_FR_CAN_Dyn_Align_Algori_0000 0;
BA_ "SystemSignalLongSymbol" SG_ 450 MRR_FR_CAN_Dyn_Align_Algori_0000 "MRR_FR_CAN_Dyn_Align_Algorithm_Version_Minor";
BA_ "GenSigCycleTime" SG_ 450 MRR_FR_CAN_Dyn_Align_Algori_0001 1000;
BA_ "GenSigSendType" SG_ 450 MRR_FR_CAN_Dyn_Align_Algori_0001 0;
BA_ "SystemSignalLongSymbol" SG_ 450 MRR_FR_CAN_Dyn_Align_Algori_0001 "MRR_FR_CAN_Dyn_Align_Algorithm_Version_Promote";
BA_ "GenSigCycleTime" SG_ 450 MRR_FR_Core_Radar_BB_Version_Fie 1000;
BA_ "GenSigSendType" SG_ 450 MRR_FR_Core_Radar_BB_Version_Fie 0;
BA_ "SystemSignalLongSymbol" SG_ 450 MRR_FR_Core_Radar_BB_Version_Fie "MRR_FR_Core_Radar_BB_Version_Field";
BA_ "GenSigCycleTime" SG_ 450 MRR_FR_Core_Radar_BB_Version_Pro 1000;
BA_ "GenSigSendType" SG_ 450 MRR_FR_Core_Radar_BB_Version_Pro 0;
BA_ "SystemSignalLongSymbol" SG_ 450 MRR_FR_Core_Radar_BB_Version_Pro "MRR_FR_Core_Radar_BB_Version_Promote";
BA_ "GenSigCycleTime" SG_ 450 MRR_FR_Core_Radar_BB_Version_Min 1000;
BA_ "GenSigSendType" SG_ 450 MRR_FR_Core_Radar_BB_Version_Min 0;
BA_ "SystemSignalLongSymbol" SG_ 450 MRR_FR_Core_Radar_BB_Version_Min "MRR_FR_Core_Radar_BB_Version_Minor";
BA_ "GenSigCycleTime" SG_ 450 MRR_FR_Core_Radar_BB_Version_Maj 1000;
BA_ "GenSigSendType" SG_ 450 MRR_FR_Core_Radar_BB_Version_Maj 0;
BA_ "SystemSignalLongSymbol" SG_ 450 MRR_FR_Core_Radar_BB_Version_Maj "MRR_FR_Core_Radar_BB_Version_Major";
BA_ "GenSigCycleTime" SG_ 450 MRR_FR_CAN_USC_Field 1000;
BA_ "GenSigSendType" SG_ 450 MRR_FR_CAN_USC_Field 0;
BA_ "GenSigCycleTime" SG_ 450 MRR_FR_CAN_USC_Promote 1000;
BA_ "GenSigSendType" SG_ 450 MRR_FR_CAN_USC_Promote 0;
BA_ "GenSigCycleTime" SG_ 450 MRR_FR_CAN_USC_Minor 1000;
BA_ "GenSigSendType" SG_ 450 MRR_FR_CAN_USC_Minor 0;
BA_ "GenSigCycleTime" SG_ 450 MRR_FR_CAN_USC_Major 1000;
BA_ "GenSigSendType" SG_ 450 MRR_FR_CAN_USC_Major 0;
BA_ "GenSigCycleTime" SG_ 450 MRR_FR_CAN_SMC_Field 1000;
BA_ "GenSigSendType" SG_ 450 MRR_FR_CAN_SMC_Field 0;
BA_ "GenSigCycleTime" SG_ 450 MRR_FR_CAN_SMC_Promote 1000;
BA_ "GenSigSendType" SG_ 450 MRR_FR_CAN_SMC_Promote 0;
BA_ "GenSigCycleTime" SG_ 450 MRR_FR_CAN_SMC_Minor 1000;
BA_ "GenSigSendType" SG_ 450 MRR_FR_CAN_SMC_Minor 0;
BA_ "GenSigCycleTime" SG_ 450 MRR_FR_CAN_SMC_Major 1000;
BA_ "GenSigSendType" SG_ 450 MRR_FR_CAN_SMC_Major 0;
BA_ "GenSigSendType" SG_ 450 MRR_FR_CAN_TX_Field 0;
BA_ "GenSigCycleTime" SG_ 450 MRR_FR_CAN_TX_Field 1000;
BA_ "GenSigSendType" SG_ 450 MRR_FR_CAN_TX_Promote 0;
BA_ "GenSigCycleTime" SG_ 450 MRR_FR_CAN_TX_Promote 1000;
BA_ "GenSigSendType" SG_ 450 MRR_FR_CAN_TX_Major 0;
BA_ "GenSigCycleTime" SG_ 450 MRR_FR_CAN_TX_Major 1000;
BA_ "GenSigSendType" SG_ 450 MRR_FR_CAN_TX_Hardware 0;
BA_ "GenSigCycleTime" SG_ 450 MRR_FR_CAN_TX_Hardware 1000;
BA_ "GenSigSendType" SG_ 450 MRR_FR_CAN_TX_SERIAL_NUMBER_SEQU 0;
BA_ "GenSigCycleTime" SG_ 450 MRR_FR_CAN_TX_SERIAL_NUMBER_SEQU 1000;
BA_ "SystemSignalLongSymbol" SG_ 450 MRR_FR_CAN_TX_SERIAL_NUMBER_SEQU "MRR_FR_CAN_TX_SERIAL_NUMBER_SEQUENCE";
BA_ "GenSigSendType" SG_ 450 MRR_FR_CAN_TX_SERIAL_NUM_JULIAN_ 0;
BA_ "GenSigCycleTime" SG_ 450 MRR_FR_CAN_TX_SERIAL_NUM_JULIAN_ 1000;
BA_ "SystemSignalLongSymbol" SG_ 450 MRR_FR_CAN_TX_SERIAL_NUM_JULIAN_ "MRR_FR_CAN_TX_SERIAL_NUM_JULIAN_YEAR";
BA_ "GenSigSendType" SG_ 450 MRR_FR_CAN_TX_SERIAL_NUM_JU_0000 0;
BA_ "GenSigCycleTime" SG_ 450 MRR_FR_CAN_TX_SERIAL_NUM_JU_0000 1000;
BA_ "SystemSignalLongSymbol" SG_ 450 MRR_FR_CAN_TX_SERIAL_NUM_JU_0000 "MRR_FR_CAN_TX_SERIAL_NUM_JULIAN_DAY";
BA_ "GenSigSendType" SG_ 450 MRR_FR_CAN_TX_ARM_THROUGHPUT 0;
BA_ "GenSigCycleTime" SG_ 450 MRR_FR_CAN_TX_ARM_THROUGHPUT 1000;
BA_ "GenSigSendType" SG_ 450 MRR_FR_CAN_TX_SYSTEM_STATUS 0;
BA_ "GenSigCycleTime" SG_ 450 MRR_FR_CAN_TX_SYSTEM_STATUS 1000;
BA_ "GenSigSendType" SG_ 450 MRR_FR_CAN_TX_LOOK_TYPE_1 0;
BA_ "GenSigCycleTime" SG_ 450 MRR_FR_CAN_TX_LOOK_TYPE_1 1000;
BA_ "GenSigSendType" SG_ 450 MRR_FR_CAN_TX_OVERHEAT_ERROR 0;
BA_ "GenSigCycleTime" SG_ 450 MRR_FR_CAN_TX_OVERHEAT_ERROR 1000;
BA_ "GenSigSendType" SG_ 450 MRR_FR_CAN_TX_RANGE_PERF_ERROR 0;
BA_ "GenSigCycleTime" SG_ 450 MRR_FR_CAN_TX_RANGE_PERF_ERROR 1000;
BA_ "GenSigSendType" SG_ 450 MRR_FR_CAN_TX_COMM_ERROR 0;
BA_ "GenSigCycleTime" SG_ 450 MRR_FR_CAN_TX_COMM_ERROR 1000;
BA_ "GenSigSendType" SG_ 450 MRR_FR_CAN_TX_INTERNAL_ERROR 0;
BA_ "GenSigCycleTime" SG_ 450 MRR_FR_CAN_TX_INTERNAL_ERROR 1000;
BA_ "GenSigSendType" SG_ 450 MRR_FR_CAN_TX_XCVR_OPERATIONAL 0;
BA_ "GenSigCycleTime" SG_ 450 MRR_FR_CAN_TX_XCVR_OPERATIONAL 1000;
BA_ "GenSigCycleTime" SG_ 450 MRR_FR_CAN_PBL_Field_Revision 1000;
BA_ "GenSigSendType" SG_ 450 MRR_FR_CAN_PBL_Field_Revision 0;
BA_ "GenSigSendType" SG_ 450 MRR_FR_CAN_PBL_Promote_Revision 0;
BA_ "GenSigCycleTime" SG_ 450 MRR_FR_CAN_PBL_Promote_Revision 1000;
BA_ "GenSigSendType" SG_ 450 MRR_FR_CAN_SW_Field_Revision 0;
BA_ "GenSigCycleTime" SG_ 450 MRR_FR_CAN_SW_Field_Revision 1000;
BA_ "GenSigSendType" SG_ 450 MRR_FR_CAN_SW_Promote_Revision 0;
BA_ "GenSigCycleTime" SG_ 450 MRR_FR_CAN_SW_Promote_Revision 1000;
BA_ "GenSigSendType" SG_ 450 MRR_FR_CAN_SW_Field 0;
BA_ "GenSigCycleTime" SG_ 450 MRR_FR_CAN_SW_Field 1000;
BA_ "GenSigSendType" SG_ 450 MRR_FR_CAN_SW_Release_Revision 0;
BA_ "GenSigCycleTime" SG_ 450 MRR_FR_CAN_SW_Release_Revision 1000;
BA_ "GenSigSendType" SG_ 450 MRR_FR_CAN_PBL_Release_Revision 0;
BA_ "GenSigCycleTime" SG_ 450 MRR_FR_CAN_PBL_Release_Revision 1000;
BA_ "GenSigSendType" SG_ 451 MRR_FR_Alignment_Status_CRC 0;
BA_ "GenSigCycleTime" SG_ 451 MRR_FR_Alignment_Status_CRC 50;
BA_ "GenSigSendType" SG_ 451 MRR_FR_Alignment_Status_MC 0;
BA_ "GenSigCycleTime" SG_ 451 MRR_FR_Alignment_Status_MC 50;
BA_ "GenSigSendType" SG_ 451 MRR_FR_CAN_TX_DRIVING_ENVIRONMEN 0;
BA_ "GenSigCycleTime" SG_ 451 MRR_FR_CAN_TX_DRIVING_ENVIRONMEN 50;
BA_ "SystemSignalLongSymbol" SG_ 451 MRR_FR_CAN_TX_DRIVING_ENVIRONMEN "MRR_FR_CAN_TX_DRIVING_ENVIRONMENT";
BA_ "GenSigSendType" SG_ 451 MRR_FR_CAN_TX_ROLLING_COUNT_1 0;
BA_ "GenSigCycleTime" SG_ 451 MRR_FR_CAN_TX_ROLLING_COUNT_1 50;
BA_ "GenSigSendType" SG_ 451 MRR_FR_CAN_TX_Temperature 0;
BA_ "GenSigCycleTime" SG_ 451 MRR_FR_CAN_TX_Temperature 50;
BA_ "GenSigSendType" SG_ 451 MRR_FR_CAN_TX_YAW_RATE_BIAS 0;
BA_ "GenSigCycleTime" SG_ 451 MRR_FR_CAN_TX_YAW_RATE_BIAS 50;
BA_ "GenSigSendType" SG_ 451 MRR_FR_CAN_TX_VEH_SPD_COMP_FACTO 0;
BA_ "GenSigCycleTime" SG_ 451 MRR_FR_CAN_TX_VEH_SPD_COMP_FACTO 50;
BA_ "SystemSignalLongSymbol" SG_ 451 MRR_FR_CAN_TX_VEH_SPD_COMP_FACTO "MRR_FR_CAN_TX_VEH_SPD_COMP_FACTOR";
BA_ "GenSigSendType" SG_ 451 MRR_FR_CAN_TX_AUTO_ALIGN_QUA_FAC 0;
BA_ "GenSigCycleTime" SG_ 451 MRR_FR_CAN_TX_AUTO_ALIGN_QUA_FAC 50;
BA_ "SystemSignalLongSymbol" SG_ 451 MRR_FR_CAN_TX_AUTO_ALIGN_QUA_FAC "MRR_FR_CAN_TX_AUTO_ALIGN_QUA_FACTOR";
BA_ "GenSigSendType" SG_ 451 MRR_FR_CAN_TX_Alignment_MODE 0;
BA_ "GenSigCycleTime" SG_ 451 MRR_FR_CAN_TX_Alignment_MODE 50;
BA_ "GenSigSendType" SG_ 451 MRR_FR_CAN_TX_CURRENT_MISALIGN_A 0;
BA_ "GenSigCycleTime" SG_ 451 MRR_FR_CAN_TX_CURRENT_MISALIGN_A 50;
BA_ "SystemSignalLongSymbol" SG_ 451 MRR_FR_CAN_TX_CURRENT_MISALIGN_A "MRR_FR_CAN_TX_CURRENT_MISALIGN_ANGLE";
BA_ "GenSigSendType" SG_ 451 MRR_FR_CAN_TX_SAVED_MISALIGN_ANG 0;
BA_ "GenSigCycleTime" SG_ 451 MRR_FR_CAN_TX_SAVED_MISALIGN_ANG 50;
BA_ "SystemSignalLongSymbol" SG_ 451 MRR_FR_CAN_TX_SAVED_MISALIGN_ANG "MRR_FR_CAN_TX_SAVED_MISALIGN_ANGLE";
BA_ "GenSigSendType" SG_ 452 MRR_FR_TO_SystemTDBlockage_Flt 0;
BA_ "GenSigCycleTime" SG_ 452 MRR_FR_TO_SystemTDBlockage_Flt 20;
BA_ "GenSigCycleTime" SG_ 452 MRR_FR_TO_CADMSWVersion_Flt 20;
BA_ "GenSigSendType" SG_ 452 MRR_FR_TO_CADMSWVersion_Flt 0;
BA_ "GenSigCycleTime" SG_ 452 MRR_FR_TO_RADARCfgParameter_Flt 20;
BA_ "GenSigSendType" SG_ 452 MRR_FR_TO_RADARCfgParameter_Flt 0;
BA_ "GenSigCycleTime" SG_ 452 MRR_FR_TO_SATCADMVIN_Flt 20;
BA_ "GenSigSendType" SG_ 452 MRR_FR_TO_SATCADMVIN_Flt 0;
BA_ "GenSigCycleTime" SG_ 452 MRR_FR_TO_CADMTracksChange_Flt 20;
BA_ "GenSigSendType" SG_ 452 MRR_FR_TO_CADMTracksChange_Flt 0;
BA_ "GenSigCycleTime" SG_ 452 MRR_FR_Active_Fault_Status_CRC 20;
BA_ "GenSigSendType" SG_ 452 MRR_FR_Active_Fault_Status_CRC 0;
BA_ "GenSigCycleTime" SG_ 452 MRR_FR_Active_Fault_Status_MC 20;
BA_ "GenSigSendType" SG_ 452 MRR_FR_Active_Fault_Status_MC 0;
BA_ "GenSigCycleTime" SG_ 452 MRR_FR_Dolphin_Flt 20;
BA_ "GenSigSendType" SG_ 452 MRR_FR_Dolphin_Flt 0;
BA_ "GenSigCycleTime" SG_ 452 MRR_FR_RRUCore_Flt 20;
BA_ "GenSigSendType" SG_ 452 MRR_FR_RRUCore_Flt 0;
BA_ "GenSigCycleTime" SG_ 452 MRR_FR_RRUBIST_Flt 20;
BA_ "GenSigSendType" SG_ 452 MRR_FR_RRUBIST_Flt 0;
BA_ "GenSigCycleTime" SG_ 452 MRR_FR_PINPosition_Flt 20;
BA_ "GenSigSendType" SG_ 452 MRR_FR_PINPosition_Flt 0;
BA_ "GenSigCycleTime" SG_ 452 MRR_FR_PCANDataRangeChk_Flt 20;
BA_ "GenSigSendType" SG_ 452 MRR_FR_PCANDataRangeChk_Flt 0;
BA_ "GenSigSendType" SG_ 452 MRR_FR_TO_AngleAdjustmentTable_F 0;
BA_ "GenSigCycleTime" SG_ 452 MRR_FR_TO_AngleAdjustmentTable_F 20;
BA_ "SystemSignalLongSymbol" SG_ 452 MRR_FR_TO_AngleAdjustmentTable_F "MRR_FR_TO_AngleAdjustmentTable_Flt";
BA_ "GenSigSendType" SG_ 452 MRR_FR_TO_CADMSgnlActlVal_Flt 0;
BA_ "GenSigCycleTime" SG_ 452 MRR_FR_TO_CADMSgnlActlVal_Flt 20;
BA_ "GenSigSendType" SG_ 452 MRR_FR_TO_TrigControl_Flt 0;
BA_ "GenSigCycleTime" SG_ 452 MRR_FR_TO_TrigControl_Flt 20;
BA_ "GenSigSendType" SG_ 452 MRR_FR_TO_VehicleState_Flt 0;
BA_ "GenSigCycleTime" SG_ 452 MRR_FR_TO_VehicleState_Flt 20;
BA_ "GenSigSendType" SG_ 452 MRR_FR_MC_AngleAdjTable_Flt 0;
BA_ "GenSigCycleTime" SG_ 452 MRR_FR_MC_AngleAdjTable_Flt 20;
BA_ "GenSigSendType" SG_ 452 MRR_FR_CRC_AngleAdjTable_Flt 0;
BA_ "GenSigCycleTime" SG_ 452 MRR_FR_CRC_AngleAdjTable_Flt 20;
BA_ "GenSigSendType" SG_ 452 MRR_FR_MC_VehicleState_Flt 0;
BA_ "GenSigCycleTime" SG_ 452 MRR_FR_MC_VehicleState_Flt 20;
BA_ "GenSigSendType" SG_ 452 MRR_FR_CRC_VehicleState_Flt 0;
BA_ "GenSigCycleTime" SG_ 452 MRR_FR_CRC_VehicleState_Flt 20;
BA_ "GenSigSendType" SG_ 452 MRR_FR_MC_TrigControl_Flt 0;
BA_ "GenSigCycleTime" SG_ 452 MRR_FR_MC_TrigControl_Flt 20;
BA_ "GenSigSendType" SG_ 452 MRR_FR_CRC_TrigControl_Flt 0;
BA_ "GenSigCycleTime" SG_ 452 MRR_FR_CRC_TrigControl_Flt 20;
BA_ "GenSigSendType" SG_ 452 MRR_FR_CRC_RadarCfgParameter_Flt 0;
BA_ "GenSigCycleTime" SG_ 452 MRR_FR_CRC_RadarCfgParameter_Flt 20;
BA_ "GenSigSendType" SG_ 452 MRR_FR_MC_CADMSgnlActlVal_Flt 0;
BA_ "GenSigCycleTime" SG_ 452 MRR_FR_MC_CADMSgnlActlVal_Flt 20;
BA_ "GenSigSendType" SG_ 452 MRR_FR_CRC_CADMSgnlActlVal_Flt 0;
BA_ "GenSigCycleTime" SG_ 452 MRR_FR_CRC_CADMSgnlActlVal_Flt 20;
BA_ "GenSigSendType" SG_ 452 MRR_FR_VINSignalCompare_Flt 0;
BA_ "GenSigCycleTime" SG_ 452 MRR_FR_VINSignalCompare_Flt 20;
BA_ "GenSigSendType" SG_ 452 MRR_FR_BatteryLow_Flt 0;
BA_ "GenSigCycleTime" SG_ 452 MRR_FR_BatteryLow_Flt 20;
BA_ "GenSigSendType" SG_ 452 MRR_FR_BatteryHigh_Flt 0;
BA_ "GenSigCycleTime" SG_ 452 MRR_FR_BatteryHigh_Flt 20;
BA_ "GenSigSendType" SG_ 452 MRR_FR_Core0_To_Core1_IPC_Flt 0;
BA_ "GenSigCycleTime" SG_ 452 MRR_FR_Core0_To_Core1_IPC_Flt 20;
BA_ "GenSigCycleTime" SG_ 452 MRR_FR_Core1_To_Core0_IPC_Flt 20;
BA_ "GenSigSendType" SG_ 452 MRR_FR_Core1_To_Core0_IPC_Flt 0;
BA_ "GenSigCycleTime" SG_ 452 MRR_FR_Core1_To_Core2_IPC_Flt 20;
BA_ "GenSigSendType" SG_ 452 MRR_FR_Core1_To_Core2_IPC_Flt 0;
BA_ "GenSigCycleTime" SG_ 452 MRR_FR_Core2_To_Core1_IPC_Flt 20;
BA_ "GenSigSendType" SG_ 452 MRR_FR_Core2_To_Core1_IPC_Flt 0;
BA_ "GenSigCycleTime" SG_ 452 MRR_FR_Core2_To_Core0_IPC_Flt 20;
BA_ "GenSigSendType" SG_ 452 MRR_FR_Core2_To_Core0_IPC_Flt 0;
BA_ "GenSigCycleTime" SG_ 452 MRR_FR_Core2Halted_Flt 20;
BA_ "GenSigSendType" SG_ 452 MRR_FR_Core2Halted_Flt 0;
BA_ "GenSigCycleTime" SG_ 452 MRR_FR_Core1Halted_Flt 20;
BA_ "GenSigSendType" SG_ 452 MRR_FR_Core1Halted_Flt 0;
BA_ "GenSigCycleTime" SG_ 452 MRR_FR_LocalOscPower_Flt 20;
BA_ "GenSigSendType" SG_ 452 MRR_FR_LocalOscPower_Flt 0;
BA_ "GenSigCycleTime" SG_ 452 MRR_FR_DSPLoopOverrun_Flt 20;
BA_ "GenSigSendType" SG_ 452 MRR_FR_DSPLoopOverrun_Flt 0;
BA_ "GenSigCycleTime" SG_ 452 MRR_FR_TransmitterPower_Flt 20;
BA_ "GenSigSendType" SG_ 452 MRR_FR_TransmitterPower_Flt 0;
BA_ "GenSigCycleTime" SG_ 452 MRR_FR_Core0_To_Core2_IPC_Flt 20;
BA_ "GenSigSendType" SG_ 452 MRR_FR_Core0_To_Core2_IPC_Flt 0;
BA_ "GenSigCycleTime" SG_ 452 MRR_FR_XCVRDeviceSPI_Flt 20;
BA_ "GenSigSendType" SG_ 452 MRR_FR_XCVRDeviceSPI_Flt 0;
BA_ "GenSigCycleTime" SG_ 452 MRR_FR_MNRBlockage_Flt 20;
BA_ "GenSigSendType" SG_ 452 MRR_FR_MNRBlockage_Flt 0;
BA_ "GenSigCycleTime" SG_ 452 MRR_FR_TransmitterTempHigh_Flt 20;
BA_ "GenSigSendType" SG_ 452 MRR_FR_TransmitterTempHigh_Flt 0;
BA_ "GenSigCycleTime" SG_ 452 MRR_FR_AlignRoutineFailed_Flt 20;
BA_ "GenSigSendType" SG_ 452 MRR_FR_AlignRoutineFailed_Flt 0;
BA_ "GenSigCycleTime" SG_ 452 MRR_FR_MicroTempHigh_Flt 20;
BA_ "GenSigSendType" SG_ 452 MRR_FR_MicroTempHigh_Flt 0;
BA_ "GenSigCycleTime" SG_ 452 MRR_FR_HAlignOutofRange_Flt 20;
BA_ "GenSigSendType" SG_ 452 MRR_FR_HAlignOutofRange_Flt 0;
BA_ "GenSigCycleTime" SG_ 452 MRR_FR_v1p1_SupplyOutOfRange_Flt 20;
BA_ "GenSigSendType" SG_ 452 MRR_FR_v1p1_SupplyOutOfRange_Flt 0;
BA_ "GenSigCycleTime" SG_ 452 MRR_FR_v1p25_SupplyOutOfRange_Fl 20;
BA_ "GenSigSendType" SG_ 452 MRR_FR_v1p25_SupplyOutOfRange_Fl 0;
BA_ "SystemSignalLongSymbol" SG_ 452 MRR_FR_v1p25_SupplyOutOfRange_Fl "MRR_FR_v1p25_SupplyOutOfRange_Flt";
BA_ "GenSigCycleTime" SG_ 452 MRR_FR_v1p8_SupplyOutOfRange_Flt 20;
BA_ "GenSigSendType" SG_ 452 MRR_FR_v1p8_SupplyOutOfRange_Flt 0;
BA_ "GenSigCycleTime" SG_ 452 MRR_FR_v2p3_SupplyOutOfRange_Flt 20;
BA_ "GenSigSendType" SG_ 452 MRR_FR_v2p3_SupplyOutOfRange_Flt 0;
BA_ "GenSigCycleTime" SG_ 452 MRR_FR_v_5_SupplyOutOfRange_Flt 20;
BA_ "GenSigSendType" SG_ 452 MRR_FR_v_5_SupplyOutOfRange_Flt 0;
BA_ "GenSigCycleTime" SG_ 452 MRR_FR_TransmitterID_Flt 20;
BA_ "GenSigSendType" SG_ 452 MRR_FR_TransmitterID_Flt 0;
BA_ "GenSigCycleTime" SG_ 452 MRR_FR_PCANBusOff_Flt 20;
BA_ "GenSigSendType" SG_ 452 MRR_FR_PCANBusOff_Flt 0;
BA_ "GenSigCycleTime" SG_ 452 MRR_FR_InstructionSetCheck_Flt 20;
BA_ "GenSigSendType" SG_ 452 MRR_FR_InstructionSetCheck_Flt 0;
BA_ "GenSigCycleTime" SG_ 452 MRR_FR_StackOverflow_Flt 20;
BA_ "GenSigSendType" SG_ 452 MRR_FR_StackOverflow_Flt 0;
BA_ "GenSigCycleTime" SG_ 452 MRR_FR_Watchdog_Flt 20;
BA_ "GenSigSendType" SG_ 452 MRR_FR_Watchdog_Flt 0;
BA_ "GenSigCycleTime" SG_ 452 MRR_FR_PLLLock_Flt 20;
BA_ "GenSigSendType" SG_ 452 MRR_FR_PLLLock_Flt 0;
BA_ "GenSigCycleTime" SG_ 452 MRR_FR_RAMMemoryTest_Flt 20;
BA_ "GenSigSendType" SG_ 452 MRR_FR_RAMMemoryTest_Flt 0;
BA_ "GenSigVtEn" SG_ 452 MRR_FR_USCValidation_Flt "*";
BA_ "GenSigCycleTime" SG_ 452 MRR_FR_USCValidation_Flt 20;
BA_ "GenSigSendType" SG_ 452 MRR_FR_USCValidation_Flt 0;
BA_ "GenSigCycleTime" SG_ 452 MRR_FR_SMCChecksum_Flt 20;
BA_ "GenSigSendType" SG_ 452 MRR_FR_SMCChecksum_Flt 0;
BA_ "GenSigCycleTime" SG_ 452 MRR_FR_KeepAliveChecksum_Flt 20;
BA_ "GenSigSendType" SG_ 452 MRR_FR_KeepAliveChecksum_Flt 0;
BA_ "GenSigCycleTime" SG_ 452 MRR_FR_ApplicationFlashChksum_Fl 20;
BA_ "GenSigSendType" SG_ 452 MRR_FR_ApplicationFlashChksum_Fl 0;
BA_ "SystemSignalLongSymbol" SG_ 452 MRR_FR_ApplicationFlashChksum_Fl "MRR_FR_ApplicationFlashChksum_Flt";
BA_ "GenSigSendType" SG_ 453 MRR_FR_XBAR_cfg_failure 0;
BA_ "GenSigCycleTime" SG_ 453 MRR_FR_XBAR_cfg_failure 20;
BA_ "GenSigSendType" SG_ 453 MRR_FR_Stack_OVF_fault_reason 0;
BA_ "GenSigCycleTime" SG_ 453 MRR_FR_Stack_OVF_fault_reason 20;
BA_ "GenSigSendType" SG_ 453 MRR_FR_App_flash_checksum_reason 0;
BA_ "GenSigCycleTime" SG_ 453 MRR_FR_App_flash_checksum_reason 20;
BA_ "GenSigSendType" SG_ 453 MRR_FR_KAM_fault_reason 0;
BA_ "GenSigCycleTime" SG_ 453 MRR_FR_KAM_fault_reason 20;
BA_ "GenSigSendType" SG_ 453 MRR_FR_RRU_Self_Test_Faults_reas 0;
BA_ "GenSigCycleTime" SG_ 453 MRR_FR_RRU_Self_Test_Faults_reas 20;
BA_ "SystemSignalLongSymbol" SG_ 453 MRR_FR_RRU_Self_Test_Faults_reas "MRR_FR_RRU_Self_Test_Faults_reason1";
BA_ "GenSigSendType" SG_ 453 MRR_FR_RRU_Core_Faults_reason3 0;
BA_ "GenSigCycleTime" SG_ 453 MRR_FR_RRU_Core_Faults_reason3 20;
BA_ "GenSigSendType" SG_ 453 MRR_FR_RRU_Core_Faults_reason2 0;
BA_ "GenSigCycleTime" SG_ 453 MRR_FR_RRU_Core_Faults_reason2 20;
BA_ "GenSigSendType" SG_ 453 MRR_FR_RRU_Core_Faults_reason1 0;
BA_ "GenSigCycleTime" SG_ 453 MRR_FR_RRU_Core_Faults_reason1 20;
BA_ "GenSigCycleTime" SG_ 453 MRR_FR_Rx_Radar_Mount_Msg_Fault 20;
BA_ "GenSigSendType" SG_ 453 MRR_FR_Rx_Radar_Mount_Msg_Fault 0;
BA_ "GenSigSendType" SG_ 453 MRR_FR_Dolphin_Fault_Detection 0;
BA_ "GenSigCycleTime" SG_ 453 MRR_FR_Dolphin_Fault_Detection 20;
BA_ "GenSigCycleTime" SG_ 453 MRR_FR_RRU_Self_Test_Faults_0000 20;
BA_ "GenSigSendType" SG_ 453 MRR_FR_RRU_Self_Test_Faults_0000 0;
BA_ "SystemSignalLongSymbol" SG_ 453 MRR_FR_RRU_Self_Test_Faults_0000 "MRR_FR_RRU_Self_Test_Faults_reason0";
BA_ "GenSigCycleTime" SG_ 453 MRR_FR_RRU_Core_Faults_reason0 20;
BA_ "GenSigSendType" SG_ 453 MRR_FR_RRU_Core_Faults_reason0 0;
BA_ "GenSigCycleTime" SG_ 453 MRR_FR_USC_Load_Error 20;
BA_ "GenSigSendType" SG_ 453 MRR_FR_USC_Load_Error 0;
BA_ "GenSigCycleTime" SG_ 453 MRR_FR_SMC_Load_Error 20;
BA_ "GenSigSendType" SG_ 453 MRR_FR_SMC_Load_Error 0;
BA_ "GenSigSendType" SG_ 453 MRR_FR_TX_Temperature_Flt 0;
BA_ "GenSigCycleTime" SG_ 453 MRR_FR_TX_Temperature_Flt 20;
BA_ "GenSigCycleTime" SG_ 453 MRR_FR_Dsp_Unit_Cal_Blk_Chcksm_E 20;
BA_ "GenSigSendType" SG_ 453 MRR_FR_Dsp_Unit_Cal_Blk_Chcksm_E 0;
BA_ "SystemSignalLongSymbol" SG_ 453 MRR_FR_Dsp_Unit_Cal_Blk_Chcksm_E "MRR_FR_Dsp_Unit_Cal_Blk_Chcksm_Error";
BA_ "GenSigCycleTime" SG_ 453 MRR_FR_Dsp_Unit_Cal_Checksum_Err 20;
BA_ "GenSigSendType" SG_ 453 MRR_FR_Dsp_Unit_Cal_Checksum_Err 0;
BA_ "SystemSignalLongSymbol" SG_ 453 MRR_FR_Dsp_Unit_Cal_Checksum_Err "MRR_FR_Dsp_Unit_Cal_Checksum_Error";
BA_ "GenSigCycleTime" SG_ 453 MRR_FR_Vertical_Misalignment_err 20;
BA_ "GenSigSendType" SG_ 453 MRR_FR_Vertical_Misalignment_err 0;
BA_ "SystemSignalLongSymbol" SG_ 453 MRR_FR_Vertical_Misalignment_err "MRR_FR_Vertical_Misalignment_error";
BA_ "GenSigCycleTime" SG_ 453 MRR_FR_RTN_SPI_Transfer_Error 20;
BA_ "GenSigSendType" SG_ 453 MRR_FR_RTN_SPI_Transfer_Error 0;
BA_ "GenSigCycleTime" SG_ 453 MRR_FR_RRN_SPI_Transfer_Error 20;
BA_ "GenSigSendType" SG_ 453 MRR_FR_RRN_SPI_Transfer_Error 0;
BA_ "GenSigCycleTime" SG_ 453 MRR_FR_Linearizer_SPI_Transfer_E 20;
BA_ "GenSigSendType" SG_ 453 MRR_FR_Linearizer_SPI_Transfer_E 0;
BA_ "SystemSignalLongSymbol" SG_ 453 MRR_FR_Linearizer_SPI_Transfer_E "MRR_FR_Linearizer_SPI_Transfer_Error";
BA_ "GenSigCycleTime" SG_ 453 MRR_FR_ADC_SPI_Transfer_Error 20;
BA_ "GenSigSendType" SG_ 453 MRR_FR_ADC_SPI_Transfer_Error 0;
BA_ "GenSigCycleTime" SG_ 453 MRR_FR_Transmitter_ID_Error 20;
BA_ "GenSigSendType" SG_ 453 MRR_FR_Transmitter_ID_Error 0;
BA_ "GenSigCycleTime" SG_ 453 MRR_FR_Dsp_Loop_Overrun_Error 20;
BA_ "GenSigSendType" SG_ 453 MRR_FR_Dsp_Loop_Overrun_Error 0;
BA_ "GenSigCycleTime" SG_ 453 MRR_FR_Saturated_Tuning_Freq_Err 20;
BA_ "GenSigSendType" SG_ 453 MRR_FR_Saturated_Tuning_Freq_Err 0;
BA_ "SystemSignalLongSymbol" SG_ 453 MRR_FR_Saturated_Tuning_Freq_Err "MRR_FR_Saturated_Tuning_Freq_Error";
BA_ "GenSigCycleTime" SG_ 453 MRR_FR_Radar_Data_sync_error 20;
BA_ "GenSigSendType" SG_ 453 MRR_FR_Radar_Data_sync_error 0;
BA_ "GenSigCycleTime" SG_ 453 MRR_FR_Dsp_Tuning_Sensitivity_Er 20;
BA_ "GenSigSendType" SG_ 453 MRR_FR_Dsp_Tuning_Sensitivity_Er 0;
BA_ "SystemSignalLongSymbol" SG_ 453 MRR_FR_Dsp_Tuning_Sensitivity_Er "MRR_FR_Dsp_Tuning_Sensitivity_Error";
BA_ "GenSigCycleTime" SG_ 453 MRR_FR_Radar_LO_Power_Error 20;
BA_ "GenSigSendType" SG_ 453 MRR_FR_Radar_LO_Power_Error 0;
BA_ "GenSigCycleTime" SG_ 453 MRR_FR_Radar_TX_Power_Error 20;
BA_ "GenSigSendType" SG_ 453 MRR_FR_Radar_TX_Power_Error 0;
BA_ "GenSigCycleTime" SG_ 453 MRR_FR_Timer_Create_Error 20;
BA_ "GenSigSendType" SG_ 453 MRR_FR_Timer_Create_Error 0;
BA_ "GenSigCycleTime" SG_ 453 MRR_FR_Thread_Create_Error 20;
BA_ "GenSigSendType" SG_ 453 MRR_FR_Thread_Create_Error 0;
BA_ "GenSigCycleTime" SG_ 453 MRR_FR_ARM_Calibration_Error 20;
BA_ "GenSigSendType" SG_ 453 MRR_FR_ARM_Calibration_Error 0;
BA_ "GenSigCycleTime" SG_ 453 MRR_FR_SPI_FEE_Error 20;
BA_ "GenSigSendType" SG_ 453 MRR_FR_SPI_FEE_Error 0;
BA_ "GenSigCycleTime" SG_ 453 MRR_FR_SPI_Comm_Error 20;
BA_ "GenSigSendType" SG_ 453 MRR_FR_SPI_Comm_Error 0;
BA_ "GenSigCycleTime" SG_ 453 MRR_FR_Socket_Write_Error 20;
BA_ "GenSigSendType" SG_ 453 MRR_FR_Socket_Write_Error 0;
BA_ "GenSigCycleTime" SG_ 453 MRR_FR_Socket_Read_error 20;
BA_ "GenSigSendType" SG_ 453 MRR_FR_Socket_Read_error 0;
BA_ "GenSigCycleTime" SG_ 453 MRR_FR_Socket_Init_Error 20;
BA_ "GenSigSendType" SG_ 453 MRR_FR_Socket_Init_Error 0;
BA_ "GenSigCycleTime" SG_ 453 MRR_FR_Signal_Wait_Error 20;
BA_ "GenSigSendType" SG_ 453 MRR_FR_Signal_Wait_Error 0;
BA_ "GenSigCycleTime" SG_ 453 MRR_FR_Signal_Send_Error 20;
BA_ "GenSigSendType" SG_ 453 MRR_FR_Signal_Send_Error 0;
BA_ "GenSigCycleTime" SG_ 453 MRR_FR_Signal_Create_Error 20;
BA_ "GenSigSendType" SG_ 453 MRR_FR_Signal_Create_Error 0;
BA_ "GenSigCycleTime" SG_ 453 MRR_FR_Shared_Mem_Write_Error 20;
BA_ "GenSigSendType" SG_ 453 MRR_FR_Shared_Mem_Write_Error 0;
BA_ "GenSigCycleTime" SG_ 453 MRR_FR_Shared_Mem_Read_Error 20;
BA_ "GenSigSendType" SG_ 453 MRR_FR_Shared_Mem_Read_Error 0;
BA_ "GenSigCycleTime" SG_ 453 MRR_FR_Shared_Mem_Config_Error 20;
BA_ "GenSigSendType" SG_ 453 MRR_FR_Shared_Mem_Config_Error 0;
BA_ "GenSigCycleTime" SG_ 453 MRR_FR_Share_Mem_Init_Error 20;
BA_ "GenSigSendType" SG_ 453 MRR_FR_Share_Mem_Init_Error 0;
BA_ "GenSigCycleTime" SG_ 453 MRR_FR_RAM_Test_Error 20;
BA_ "GenSigSendType" SG_ 453 MRR_FR_RAM_Test_Error 0;
BA_ "GenSigCycleTime" SG_ 453 MRR_FR_Num_Errors 20;
BA_ "GenSigSendType" SG_ 453 MRR_FR_Num_Errors 0;
BA_ "GenSigCycleTime" SG_ 453 MRR_FR_MMAP_Memory_Error 20;
BA_ "GenSigSendType" SG_ 453 MRR_FR_MMAP_Memory_Error 0;
BA_ "GenSigCycleTime" SG_ 453 MRR_FR_ISR_Attach_Error 20;
BA_ "GenSigSendType" SG_ 453 MRR_FR_ISR_Attach_Error 0;
BA_ "GenSigCycleTime" SG_ 453 MRR_FR_IPC_DRV_Write_Error 20;
BA_ "GenSigSendType" SG_ 453 MRR_FR_IPC_DRV_Write_Error 0;
BA_ "GenSigCycleTime" SG_ 453 MRR_FR_IPC_DRV_Trigger_Error 20;
BA_ "GenSigSendType" SG_ 453 MRR_FR_IPC_DRV_Trigger_Error 0;
BA_ "GenSigCycleTime" SG_ 453 MRR_FR_IPC_DRV_Sync_Error 20;
BA_ "GenSigSendType" SG_ 453 MRR_FR_IPC_DRV_Sync_Error 0;
BA_ "GenSigCycleTime" SG_ 453 MRR_FR_IPC_DRV_Read_Error 20;
BA_ "GenSigSendType" SG_ 453 MRR_FR_IPC_DRV_Read_Error 0;
BA_ "GenSigCycleTime" SG_ 453 MRR_FR_IPC_DRV_Init_Error 20;
BA_ "GenSigSendType" SG_ 453 MRR_FR_IPC_DRV_Init_Error 0;
BA_ "GenSigCycleTime" SG_ 453 MRR_FR_Interrupt_Enable_Error 20;
BA_ "GenSigSendType" SG_ 453 MRR_FR_Interrupt_Enable_Error 0;
BA_ "GenSigCycleTime" SG_ 453 MRR_FR_HIL_Format_Error 20;
BA_ "GenSigSendType" SG_ 453 MRR_FR_HIL_Format_Error 0;
BA_ "GenSigCycleTime" SG_ 453 MRR_FR_Flash_Filesystem_Error 20;
BA_ "GenSigSendType" SG_ 453 MRR_FR_Flash_Filesystem_Error 0;
BA_ "GenSigCycleTime" SG_ 453 MRR_FR_Error_none 20;
BA_ "GenSigSendType" SG_ 453 MRR_FR_Error_none 0;
BA_ "GenSigCycleTime" SG_ 453 MRR_FR_Dsp_Load_Read_Error 20;
BA_ "GenSigSendType" SG_ 453 MRR_FR_Dsp_Load_Read_Error 0;
BA_ "GenSigCycleTime" SG_ 453 MRR_FR_Dsp_Load_Open_Error 20;
BA_ "GenSigSendType" SG_ 453 MRR_FR_Dsp_Load_Open_Error 0;
BA_ "GenSigCycleTime" SG_ 453 MRR_FR_Dsp_Load_Address_Error 20;
BA_ "GenSigSendType" SG_ 453 MRR_FR_Dsp_Load_Address_Error 0;
BA_ "GenSigCycleTime" SG_ 453 MRR_FR_Dsp_ISP_Write_Error 20;
BA_ "GenSigSendType" SG_ 453 MRR_FR_Dsp_ISP_Write_Error 0;
BA_ "GenSigCycleTime" SG_ 453 MRR_FR_Dsp_IPC_Read_Error 20;
BA_ "GenSigSendType" SG_ 453 MRR_FR_Dsp_IPC_Read_Error 0;
BA_ "GenSigCycleTime" SG_ 453 MRR_FR_Dsp_IPC_Init 20;
BA_ "GenSigSendType" SG_ 453 MRR_FR_Dsp_IPC_Init 0;
BA_ "GenSigCycleTime" SG_ 453 MRR_FR_Dsp_Init_Error 20;
BA_ "GenSigSendType" SG_ 453 MRR_FR_Dsp_Init_Error 0;
BA_ "GenSigCycleTime" SG_ 453 MRR_FR_Dsp_DRV_Start_Error 20;
BA_ "GenSigSendType" SG_ 453 MRR_FR_Dsp_DRV_Start_Error 0;
BA_ "GenSigCycleTime" SG_ 453 MRR_FR_Dsp_DRV_Load_Error 20;
BA_ "GenSigSendType" SG_ 453 MRR_FR_Dsp_DRV_Load_Error 0;
BA_ "GenSigCycleTime" SG_ 453 MRR_FR_Dsp_DRV_Init_Error 20;
BA_ "GenSigSendType" SG_ 453 MRR_FR_Dsp_DRV_Init_Error 0;
BA_ "GenSigCycleTime" SG_ 453 MRR_FR_Dsp_DRV_Init2_error 20;
BA_ "GenSigSendType" SG_ 453 MRR_FR_Dsp_DRV_Init2_error 0;
BA_ "GenSigCycleTime" SG_ 453 MRR_FR_Dsp_DRV_Init1_error 20;
BA_ "GenSigSendType" SG_ 453 MRR_FR_Dsp_DRV_Init1_error 0;
BA_ "GenSigCycleTime" SG_ 453 MRR_FR_CAN_XMT_Error 20;
BA_ "GenSigSendType" SG_ 453 MRR_FR_CAN_XMT_Error 0;
BA_ "GenSigCycleTime" SG_ 453 MRR_FR_CAN_RCV_Error 20;
BA_ "GenSigSendType" SG_ 453 MRR_FR_CAN_RCV_Error 0;
BA_ "GenSigCycleTime" SG_ 453 MRR_FR_CAN_Hardware_Error 20;
BA_ "GenSigSendType" SG_ 453 MRR_FR_CAN_Hardware_Error 0;
BA_ "GenSigCycleTime" SG_ 453 MRR_FR_Always_True 20;
BA_ "GenSigSendType" SG_ 453 MRR_FR_Always_True 0;
VAL_ 680 MRR_FL_Radar_Reset 1 "Logic high  - Normal Operaton/Deafult " 0 "Reset Pending" ;
VAL_ 679 MRR_FR_Radar_Reset 1 " Normal Operaton/Deafult " 0 "Reset Pending" ;
VAL_ 768 MRR_FL_CAN_DET_CONFID_AZIMUTH_00 3 "Low" 2 "MidLow" 1 "MidHigh" 0 "High" ;
VAL_ 768 MRR_FL_CAN_DET_CONFID_AZIMU_0000 3 "Low" 2 "MidLow" 1 "MidHigh" 0 "High" ;
VAL_ 768 MRR_FL_CAN_DET_CONFID_AZIMU_0001 3 "Low" 2 "MidLow" 1 "MidHigh" 0 "High" ;
VAL_ 768 MRR_FL_CAN_DET_CONFID_AZIMU_0002 3 "Low" 2 "MidLow" 1 "MidHigh" 0 "High" ;
VAL_ 768 MRR_FL_CAN_DET_CONFID_AZIMU_0003 3 "Low" 2 "MidLow" 1 "MidHigh" 0 "High" ;
VAL_ 768 MRR_FL_CAN_DET_CONFID_AZIMU_0004 3 "Low" 2 "MidLow" 1 "MidHigh" 0 "High" ;
VAL_ 768 MRR_FL_CAN_DET_CONFID_AZIMU_0005 3 "Low" 2 "MidLow" 1 "MidHigh" 0 "High" ;
VAL_ 1346 SensorCfg_MRRRL_Orientation 255 "-1 Connector Up (Upside Down)" 1 "+1 Connector Down (Normal Orientation)

" ;
VAL_ 1346 SensorCfg_MRRRR_Orientation 255 "-1 Connector Up (Upside Down)" 1 "+1 Connector Down (Normal Orientation)

" ;
VAL_ 1346 SensorCfg_MRRFL_Orientation 255 "-1 Connector Up (Upside Down)" 1 "+1 Connector Down (Normal Orientation)

" ;
VAL_ 1346 SensorCfg_MRRFR_Orientation 255 "-1 Connector Up (Upside Down)" 1 "+1 Connector Down (Normal Orientation)

" ;
VAL_ 22 RadarWaveform_MRRFR 4 "Unused" 3 "AutoHitch" 2 "Standard_Rear" 1 "Standard_Front" 0 "Unknown" ;
VAL_ 22 MRR_FR_CAN_FOUND_TARGET 1 "Target found" 0 "Target not found" ;
VAL_ 22 MRR_FR_CAN_BLOCKAGE_TD 1 "TD blockage" 0 "No blockage" ;
VAL_ 23 RadarWaveform_MRRFL 4 "Unused" 3 "AutoHitch" 2 "Standard_Rear" 1 "Standard_Front" 0 "Unknown" ;
VAL_ 23 MRR_FL_CAN_FOUND_TARGET 1 "Target found" 0 "Target not found" ;
VAL_ 23 MRR_FL_CAN_BLOCKAGE_TD 1 "TD blockage" 0 "No blockage" ;
VAL_ 48 VehOverGnd_V_Est 65535 "Invalid" 65534 "Unknown" ;
VAL_ 48 CAN_IGN_STATUS 15 "Invalid" 8 "Start" 4 "Run" 2 "Accessory" 1 "Off" 0 "Unknown" ;
VAL_ 48 CAN_PRND_POSITION 15 "Fault" 14 "Unknown_Position" 13 "NotUsed_2" 12 "NotUsed_1" 11 "sixth" 10 "fifth" 9 "fourth" 8 "third" 7 "second" 6 "first" 5 "Low" 4 "Sport_DriveSport" 3 "Drive" 2 "Neutral" 1 "Reverse" 0 "Park" ;
VAL_ 48 CAN_VEH_BATT_VOLT 255 "Fault" ;
VAL_ 185 CAN_CADM_Master 3 "Error" 2 "CADM MAP" 1 "CADM MID" 0 "No request - (Default MID or  LO in single CADM)" ;
VAL_ 185 CAN_VEHICLE_MODE 1 "MODE_ROLLING " 0 "

STANDARD_MODE " ;
VAL_ 185 CAN_WIPER_STATUS 1 "On" 0 "Off" ;
VAL_ 185 CAN_YAW_RATE_VALIDITY 1 "Veh Yaw Rate Available or Valid" 0 "No Vehicle Yaw Rate or Invalid" ;
VAL_ 185 CAN_VEHICLE_STAT 1 "Yes" 0 "No" ;
VAL_ 185 CAN_CADM_DrivingDirection 3 "Unknown/Error" 2 "Forward" 1 "Backward" 0 "Standstill" ;
VAL_ 185 CAN_VEHICLE_SPEED_VALIDITY 1 "Valid" 0 "Invalid" ;
VAL_ 185 CAN_VEHICLE_SPEED_DIRECTION 1 "Reverse" 0 "Forward" ;
VAL_ 185 CAN_VEHICLE_SPEED_CALC_QF 3 "Accurate" 2 "Innaccurate" 1 "Temporarily Undefined" 0 "Undefined" ;
VAL_ 185 CAN_YAW_RATE_CALC_QF 3 "Accurate" 2 "Innaccurate" 1 "Temporarily Undefined" 0 "Undefined" ;
VAL_ 185 Yaw_Rate_Reference_Valid 1 "Valid" 0 "Invalid" ;
VAL_ 185 CAN_VEH_LONG_ACCEL_QF 3 "Accurate" 2 "Innacurate" 1 "Temporarily Undefined" 0 "Undefined (faulty)" ;
VAL_ 185 CAN_STEERING_WHL_ANGLE_QF 1 "Valid" 0 "Invalid" ;
VAL_ 185 CAN_BRAKE_PEDAL 2 "Pressed" 1 "Not Pressed" 0 "Unknown" ;
VAL_ 185 CAN_TURN_SIGNAL_STATUS 3 "Left and Rigth, both on" 2 "Right" 1 "Left" 0 "None" ;
VAL_ 1795 SAT_CAN_ODOMETER 16777216 "Description for the value '0x1000000'" 16777215 "Invalid" ;
VAL_ 16 MRR_FL_CAN_INST_MODE 43605 "Instrumentation mode is set" ;
VAL_ 17 MRR_FR_CAN_INST_MODE 43605 "Instrumentation mode is set" ;
VAL_ 395 MRR_FL_Horizontal_Alignment_Stat 15 "Undefined" 14 "Undefined" 13 "Low Amplitude (Flat-plate only)" 12 "No Peak (Flat-plate only)" 11 "Fail Ver and Hor OutOfRange" 10 "Fail Vertical Align OutOfRange" 9 "Fail Horizontal Align OutOfRange" 8 "Fail Time Out" 7 "Fail Only MRRR Target Found" 6 "Fail Only MRRL Target Found" 5 "Fail Variance Too Large" 4 "Fail Deviation Too Large" 3 "Fail No Target" 2 "Success" 1 "Busy" 0 "Off" ;
VAL_ 395 MRR_FL_Vertical_Alignment_Status 15 "Undefined" 14 "Undefined" 13 "Low Amplitude (Flat-plate only)" 12 "No Peak (Flat-plate only)" 11 "Fail Ver and Hor OutOfRange" 10 "Fail Vertical Align OutOfRange" 9 "Fail Horizontal Align OutOfRange" 8 "Fail Time Out" 7 "Fail Only MRRR Target Found" 6 "Fail Only MRRL Target Found" 5 "Fail Variance Too Large" 4 "Fail Deviation Too Large" 3 "Fail No Target" 2 "Success" 1 "Busy" 0 "Off" ;
VAL_ 395 MRR_FL_Vertical_Alignment_State 6 "Static alignment flat-plate" 5 "Static alignment 2-target" 4 "Static alignment 1-target" 3 "Service alignment" 2 "Short track alignment" 1 "Auto alignment" 0 "Off" ;
VAL_ 395 MRR_FL_Horizontal_Alignment_0000 6 "Static alignment flat-plate" 5 "Static alignment 2-target" 4 "Static alignment 1-target" 3 "Service alignment" 2 "Short track alignment" 1 "Auto alignment" 0 "Off" ;
VAL_ 395 MRR_FL_Align_Vertical_QF 3 "Accurate" 2 "Innacurate" 1 "Temporarily undefined (Faulty)" 0 "Undefined" ;
VAL_ 395 MRR_FL_Align_Horizontal_QF 3 "Accurate" 2 "Innacurate" 1 "Temporarily undefined (Faulty)" 0 "Undefined" ;
VAL_ 459 MRR_FR_Horizontal_Alignment_Stat 15 "Undefined" 14 "Undefined" 13 "Low Amplitude (Flat-plate only)" 12 "No Peak (Flat-plate only)" 11 "Fail Ver and Hor OutOfRange" 10 "Fail Vertical Align OutOfRange" 9 "Fail Horizontal Align OutOfRange" 8 "Fail Time Out" 7 "Fail Only MRRR Target Found" 6 "Fail Only MRRL Target Found" 5 "Fail Variance Too Large" 4 "Fail Deviation Too Large" 3 "Fail No Target" 2 "Success" 1 "Busy" 0 "Off" ;
VAL_ 459 MRR_FR_Vertical_Alignment_Status 15 "Undefined" 14 "Undefined" 13 "Low Amplitude (Flat-plate only)" 12 "No Peak (Flat-plate only)" 11 "Fail Ver and Hor OutOfRange" 10 "Fail Vertical Align OutOfRange" 9 "Fail Horizontal Align OutOfRange" 8 "Fail Time Out" 7 "Fail Only MRRR Target Found" 6 "Fail Only MRRL Target Found" 5 "Fail Variance Too Large" 4 "Fail Deviation Too Large" 3 "Fail No Target" 2 "Success" 1 "Busy" 0 "Off" ;
VAL_ 459 MRR_FR_Vertical_Alignment_State 6 "Static alignment flat-plate" 5 "Static alignment 2-target" 4 "Static alignment 1-target" 3 "Service alignment" 2 "Short track alignment" 1 "Auto alignment" 0 "Off" ;
VAL_ 459 MRR_FR_Horizontal_Alignment_0000 6 "Static alignment flat-plate" 5 "Static alignment 2-target" 4 "Static alignment 1-target" 3 "Service alignment" 2 "Short track alignment" 1 "Auto alignment" 0 "Off" ;
VAL_ 459 MRR_FR_Align_Vertical_QF 3 "Accurate" 2 "Innacurate" 1 "Temporarily undefined (Faulty)" 0 "Undefined" ;
VAL_ 459 MRR_FR_Align_Horizontal_QF 3 "Accurate" 2 "Innacurate" 1 "Temporarily undefined (Faulty)" 0 "Undefined" ;
VAL_ 386 MRR_FL_CAN_TX_SW_VERSION_DSP 71426 "2.23.1" 71170 "2.22.1" 5890 "2.23" ;
VAL_ 386 MRR_FL_CAN_TX_SW_VERSION_ARM 66827 "1.5.11" 66826 "1.5.10" ;
VAL_ 389 MRR_FL_Dolphin_Fault_Detection 2 "Dolphin Sensor Dead" 1 "Dolphin Start_up Error" 0 "No Faults" ;
VAL_ 392 MRR_CAN_RadarWaveform_FL 4 "Unused" 3 "AutoHitch" 2 "Standard_Rear" 1 "Standard_Front" 0 "Unknown" ;
VAL_ 450 MRR_FR_CAN_TX_SW_VERSION_DSP 71426 "2.23.1" 71170 "2.22.1" 5890 "2.23" ;
VAL_ 450 MRR_FR_CAN_TX_SW_VERSION_ARM 66827 "1.5.11" 66826 "1.5.10" ;
VAL_ 453 MRR_FR_Dolphin_Fault_Detection 2 "Dolphin Sensor Dead" 1 "Dolphin Start_up Error" 0 "No Faults" ;
SIG_GROUP_ 37 MRR_FR_Angle_Adjustment_Table 1 : MRR_FR_AAT_MC MRR_FR_AAT_CRC MRR_FR_POS_80 MRR_FR_POS_70 MRR_FR_POS_60 MRR_FR_POS_50 MRR_FR_POS_40 MRR_FR_POS_30 MRR_FR_POS_20 MRR_FR_POS_10 MRR_FR_0 MRR_FR_NEG_10 MRR_FR_NEG_20 MRR_FR_NEG_30 MRR_FR_NEG_40 MRR_FR_NEG_50 MRR_FR_NEG_60 MRR_FR_NEG_70 MRR_FR_NEG_80;
SIG_GROUP_ 36 MRR_FL_Angle_Adjustment_Table 1 : MRR_FL_AAT_CRC MRR_FL_AAT_MC MRR_FL_POS_80 MRR_FL_POS_70 MRR_FL_POS_60 MRR_FL_POS_50 MRR_FL_POS_40 MRR_FL_POS_30 MRR_FL_POS_20 MRR_FL_POS_10 MRR_FL_0 MRR_FL_NEG_80 MRR_FL_NEG_70 MRR_FL_NEG_60 MRR_FL_NEG_50 MRR_FL_NEG_40 MRR_FL_NEG_30 MRR_FL_NEG_20 MRR_FL_NEG_10;
SIG_GROUP_ 768 MRR_FL_Detection_001_007 1 : MRR_FL_CAN_DET_Near_TARGET_001 MRR_FL_CAN_DET_Near_TARGET_002 MRR_FL_CAN_DET_Near_TARGET_003 MRR_FL_CAN_DET_Near_TARGET_004 MRR_FL_CAN_DET_Near_TARGET_005 MRR_FL_CAN_DET_Near_TARGET_006 MRR_FL_CAN_DET_Near_TARGET_007 MRR_FL_CAN_DET_MID_TARGET_001 MRR_FL_CAN_DET_MID_TARGET_002 MRR_FL_CAN_DET_MID_TARGET_003 MRR_FL_CAN_DET_MID_TARGET_004 MRR_FL_CAN_DET_MID_TARGET_005 MRR_FL_CAN_DET_MID_TARGET_006 MRR_FL_CAN_DET_MID_TARGET_007 MRR_FL_CAN_DET_ELEVATION_001 MRR_FL_CAN_DET_CONFID_AZIMUTH_00 MRR_FL_CAN_DET_HOST_VEH_CLUTTER_ MRR_FL_CAN_DET_VALID_LEVEL_001 MRR_FL_CAN_DET_RANGE_001 MRR_FL_DET_MC_001 MRR_FL_CAN_DET_RANGE_007 MRR_FL_CAN_DET_RANGE_006 MRR_FL_CAN_DET_RANGE_005 MRR_FL_CAN_DET_AMPLITUDE_005 MRR_FL_CAN_DET_VALID_LEVEL_005 MRR_FL_CAN_DET_ELEVATION_004 MRR_FL_CAN_SCAN_INDEX_2LSB_004 MRR_FL_CAN_DET_AMPLITUDE_004 MRR_FL_CAN_DET_CONFID_ELEVA_0004 MRR_FL_CAN_DET_RANGE_003 MRR_FL_CAN_DET_CONFID_AZIMU_0004 MRR_FL_CAN_DET_RANGE_RATE_003 MRR_FL_CAN_DET_AMPLITUDE_003 MRR_FL_CAN_DET_VALID_LEVEL_003 MRR_FL_CAN_DET_ELEVATION_002 MRR_FL_CAN_DET_AZIMUTH_002 MRR_FL_CAN_DET_RANGE_002 MRR_FL_CAN_DET_CONFID_ELEVA_0005 MRR_FL_CAN_DET_CONFID_AZIMU_0005 MRR_FL_CAN_DET_SUPER_RES_TA_0005 MRR_FL_CAN_SCAN_INDEX_2LSB_003 MRR_FL_CAN_DET_CONFID_ELEVATION_ MRR_FL_CAN_DET_RANGE_004 MRR_FL_CAN_DET_AZIMUTH_003 MRR_FL_CAN_DET_HOST_VEH_CLU_0004 MRR_FL_CAN_DET_ELEVATION_003 MRR_FL_CAN_DET_SUPER_RES_TA_0004 MRR_FL_CAN_DET_VALID_LEVEL_004 MRR_FL_CAN_DET_CONFID_AZIMU_0003 MRR_FL_CAN_DET_RANGE_RATE_004 MRR_FL_CAN_DET_AZIMUTH_004 MRR_FL_CAN_DET_AZIMUTH_006 MRR_FL_CAN_DET_VALID_LEVEL_006 MRR_FL_CAN_DET_CONFID_ELEVA_0003 MRR_FL_CAN_DET_CONFID_AZIMU_0001 MRR_FL_CAN_DET_CONFID_ELEVA_0002 MRR_FL_CAN_DET_RANGE_RATE_005 MRR_FL_CAN_DET_AMPLITUDE_006 MRR_FL_CAN_DET_HOST_VEH_CLU_0003 MRR_FL_CAN_DET_SUPER_RES_TA_0003 MRR_FL_CAN_SCAN_INDEX_2LSB_005 MRR_FL_CAN_DET_CONFID_AZIMU_0002 MRR_FL_CAN_DET_RANGE_RATE_002 MRR_FL_CAN_DET_ELEVATION_005 MRR_FL_CAN_DET_SUPER_RES_TA_0002 MRR_FL_CAN_DET_HOST_VEH_CLU_0002 MRR_FL_CAN_DET_AZIMUTH_005 MRR_FL_CAN_SCAN_INDEX_2LSB_002 MRR_FL_DET_CRC_001 MRR_FL_CAN_DET_VALID_LEVEL_007 MRR_FL_CAN_DET_AMPLITUDE_001 MRR_FL_CAN_DET_CONFID_ELEVA_0000 MRR_FL_CAN_DET_HOST_VEH_CLU_0000 MRR_FL_CAN_DET_AZIMUTH_001 MRR_FL_CAN_DET_SUPER_RES_TARGET_ MRR_FL_CAN_DET_RANGE_RATE_006 MRR_FL_CAN_SCAN_INDEX_2LSB_006 MRR_FL_CAN_DET_HOST_VEH_CLU_0005 MRR_FL_CAN_DET_AZIMUTH_007 MRR_FL_CAN_DET_RANGE_RATE_001 MRR_FL_CAN_SCAN_INDEX_2LSB_001 MRR_FL_CAN_DET_SUPER_RES_TA_0000 MRR_FL_CAN_DET_HOST_VEH_CLU_0001 MRR_FL_CAN_DET_CONFID_ELEVA_0001 MRR_FL_CAN_DET_SUPER_RES_TA_0001 MRR_FL_CAN_DET_ELEVATION_006 MRR_FL_CAN_DET_CONFID_AZIMU_0000 MRR_FL_CAN_DET_RANGE_RATE_007 MRR_FL_CAN_SCAN_INDEX_2LSB_007 MRR_FL_CAN_DET_AMPLITUDE_007 MRR_FL_CAN_DET_AMPLITUDE_002 MRR_FL_CAN_DET_VALID_LEVEL_002 MRR_FL_CAN_DET_ELEVATION_007;
SIG_GROUP_ 1346 MRR_Radar_Cfg_Parameters 1 : SensorCfg_MRRFR_Orientation SensorCfg_MRRFL_Orientation SensorCfg_MRRRR_Orientation SensorCfg_MRRRL_Orientation SensorCfg_MRRFR_Yaw SensorCfg_MRRFL_Yaw SensorCfg_MRRRR_Yaw SensorCfg_MRRRL_Yaw SensorCfg_MRRFR_VertPos SensorCfg_MRRFL_VertPos SensorCfg_MRRRR_VertPos SensorCfg_MRRRL_VertPos SensorCfg_MRRFR_LongPos SensorCfg_MRRFL_LongPos SensorCfg_MRRRR_LongPos SensorCfg_MRRRL_LongPos SensorCfg_MRRFR_LatPos SensorCfg_MRRFL_LatPos SensorCfg_MRRRR_LatPos SensorCfg_MRRRL_LatPos SensorCfg_MRRRL_Pitch SensorCfg_MRRFR_Pitch SensorCfg_MRRFL_Pitch SensorCfg_MRRRR_Pitch MRR_SENSR_CFG_CRC SensorCfg_MRRRL_AlignRngTolHorz SensorCfg_MRRRR_AlignRngTolHorz SensorCfg_MRRFL_AlignRngTolHorz SensorCfg_MRRFR_AlignRngTolHorz SensorCfg_MRRRL_AlignRngTolVert SensorCfg_MRRRR_AlignRngTolVert SensorCfg_MRRFL_AlignRngTolVert SensorCfg_MRRFR_AlignRngTolVert;
SIG_GROUP_ 48 CADM_SignalsActualValues_2 1 : VehOverGnd_V_Est CAN_IGN_STATUS CAN_PRND_POSITION CAN_VEH_BATT_VOLT CAN_sigactualvalues_CRC CAN_sigactualvalues_MC CAN_Outside_Air_Temp;
SIG_GROUP_ 185 VEHICLE_STATE_MSG_2 1 : CAN_CADM_Master CAN_VEHICLE_SPEED CAN_STEERING_ANGLE CAN_VEHICLE_MODE CAN_WIPER_STATUS CAN_YAW_RATE CAN_STEERING_ANGLE_SIGN CAN_YAW_RATE_VALIDITY CAN_VEHICLE_STAT CAN_CADM_DrivingDirection CAN_VEHICLE_SPEED_VALIDITY CAN_VEHICLE_SPEED_DIRECTION CAN_VEHICLE_SPEED_CALC_QF CAN_VEHICLE_SPEED_CALC CAN_YAW_RATE_CALC CAN_YAW_RATE_CALC_QF VEH_STATE_MSG_CRC VEH_STATE_MSG_MC Yaw_Rate_Reference Yaw_Rate_Reference_Valid CAN_VEH_LONG_ACCEL_QF CAN_VEH_LONG_ACCEL CAN_STEERING_WHL_ANGLE CAN_STEERING_WHL_ANGLE_QF CAN_BRAKE_PEDAL CAN_TURN_SIGNAL_STATUS;
SIG_GROUP_ 395 MRR_FL_Header_AlignmentState 1 : MRR_FL_CAN_HRZNTL_ALIGN_UPDATES_ MRR_FL_CAN_VRTCL_ALIGN_UPDATES_N MRR_FL_Header_AlignmentState_CRC MRR_FL_Header_AlignmentState_MC MRR_FL_Horizontal_Alignment_Stat MRR_FL_Vertical_Alignment_Status MRR_FL_Vertical_Alignment_State MRR_FL_Horizontal_Alignment_0000 MRR_FL_Align_Vertical_Ref MRR_FL_Align_Vertical_QF MRR_FL_Align_Vertical_Angle MRR_FL_Align_Horizontal_Angle MRR_FL_Align_Horizontal_Ref MRR_FL_Align_Horizontal_QF;
SIG_GROUP_ 459 MRR_FR_Header_AlignmentState 1 : MRR_FR_CAN_HRZNTL_ALIGN_UPDATES_ MRR_FR_CAN_VRTCL_ALIGN_UPDATES_N MRR_FR_Header_AlignmentState_CRC MRR_FR_Header_AlignmentState_MC MRR_FR_Horizontal_Alignment_Stat MRR_FR_Vertical_Alignment_Status MRR_FR_Vertical_Alignment_State MRR_FR_Horizontal_Alignment_0000 MRR_FR_Align_Vertical_Ref MRR_FR_Align_Vertical_QF MRR_FR_Align_Vertical_Angle MRR_FR_Align_Horizontal_Angle MRR_FR_Align_Horizontal_Ref MRR_FR_Align_Horizontal_QF;
SIG_GROUP_ 4 Radar_Trig_Control 1 : Radar_Trig_Control_CRC Radar_Trig_Control_MC CADM_TimeSync_Timer_Count;
SIG_GROUP_ 387 MRR_FL_Alignment_Status 1 : MRR_FL_Alignment_Status_CRC MRR_FL_Alignment_Status_MC MRR_FL_CAN_TX_DRIVING_ENVIRONMEN MRR_FL_CAN_TX_ROLLING_COUNT_1 MRR_FL_CAN_TX_Temperature MRR_FL_CAN_TX_YAW_RATE_BIAS MRR_FL_CAN_TX_VEH_SPD_COMP_FACTO MRR_FL_CAN_TX_AUTO_ALIGN_QUA_FAC MRR_FL_CAN_TX_Alignment_MODE MRR_FL_CAN_TX_CURRENT_MISALIGN_A MRR_FL_CAN_TX_SAVED_MISALIGN_ANG;
SIG_GROUP_ 388 MRR_FL_Active_Fault_Status 1 : MRR_FL_TO_AngleAdjustmentTable_F MRR_FL_TO_TrigControl_Flt MRR_FL_CRC_CADMSgnlActlVal_Flt MRR_FL_Core2_To_Core0_IPC_Flt MRR_FL_v1p1_SupplyOutOfRange_Flt MRR_FL_TransmitterID_Flt MRR_FL_InstructionSetCheck_Flt MRR_FL_SMCChecksum_Flt MRR_FL_KeepAliveChecksum_Flt MRR_FL_ApplicationFlashChksum_Fl MRR_FL_RAMMemoryTest_Flt MRR_FL_Watchdog_Flt MRR_FL_StackOverflow_Flt MRR_FL_USCValidation_Flt MRR_FL_PLLLock_Flt MRR_FL_MC_CADMSgnlActlVal_Flt MRR_FL_PCANBusOff_Flt MRR_FL_v1p8_SupplyOutOfRange_Flt MRR_FL_v_5_SupplyOutOfRange_Flt MRR_FL_TransmitterPower_Flt MRR_FL_CRC_TrigControl_Flt MRR_FL_MC_AngleAdjTable_Flt MRR_FL_TO_CADMSgnlActlVal_Flt MRR_FL_TO_VehicleState_Flt MRR_FL_MC_TrigControl_Flt MRR_FL_CRC_AngleAdjTable_Flt MRR_FL_CRC_VehicleState_Flt MRR_FL_Core2Halted_Flt MRR_FL_XCVRDeviceSPI_Flt MRR_FL_MicroTempHigh_Flt MRR_FL_Core1Halted_Flt MRR_FL_AlignRoutineFailed_Flt MRR_FL_MNRBlockage_Flt MRR_FL_LocalOscPower_Flt MRR_FL_Core1_To_Core2_IPC_Flt MRR_FL_v1p25_SupplyOutOfRange_Fl MRR_FL_v2p3_SupplyOutOfRange_Flt MRR_FL_HAlignOutofRange_Flt MRR_FL_TransmitterTempHigh_Flt MRR_FL_Core0_To_Core2_IPC_Flt MRR_FL_DSPLoopOverrun_Flt MRR_FL_MC_VehicleState_Flt MRR_FL_Core2_To_Core1_IPC_Flt MRR_FL_BatteryLow_Flt MRR_FL_BatteryHigh_Flt MRR_FL_VINSignalCompare_Flt MRR_FL_CRC_RadarCfgParameter_Flt MRR_FL_Core1_To_Core0_IPC_Flt MRR_FL_Core0_To_Core1_IPC_Flt MRR_FL_PCANDataRangeChk_Flt MRR_FL_PINPosition_Flt MRR_FL_RRUBIST_Flt MRR_FL_RRUCore_Flt MRR_FL_Dolphin_Flt MRR_FL_Active_Fault_Status_MC MRR_FL_Active_Fault_Status_CRC MRR_FL_TO_CADMTracksChange_Flt MRR_FL_TO_SATCADMVIN_Flt MRR_FL_TO_RADARCfgParameter_Flt MRR_FL_TO_CADMSWVersion_Flt MRR_FL_TO_SystemTDBlockage_Flt;
SIG_GROUP_ 392 MRR_FL_Header_SensorCoverage 1 : MRR_FL_Radar_Spec_Status_MC MRR_FL_Radar_Spec_Status_CRC MRR_CAN_RadarWaveform_FL MRR_FL_CAN_RANGE_COVERAGE MRR_FL_CAN_DOPPLER_COVERAGE MRR_FL_CAN_FOV_HOR MRR_FL_CAN_FOV_VER;
SIG_GROUP_ 451 MRR_FR_Alignment_Status 1 : MRR_FR_Alignment_Status_CRC MRR_FR_Alignment_Status_MC MRR_FR_CAN_TX_DRIVING_ENVIRONMEN MRR_FR_CAN_TX_ROLLING_COUNT_1 MRR_FR_CAN_TX_Temperature MRR_FR_CAN_TX_YAW_RATE_BIAS MRR_FR_CAN_TX_VEH_SPD_COMP_FACTO MRR_FR_CAN_TX_AUTO_ALIGN_QUA_FAC MRR_FR_CAN_TX_Alignment_MODE MRR_FR_CAN_TX_CURRENT_MISALIGN_A MRR_FR_CAN_TX_SAVED_MISALIGN_ANG;
SIG_GROUP_ 452 MRR_FR_Active_Fault_Status 1 : MRR_FR_TO_SATCADMVIN_Flt MRR_FR_TO_CADMTracksChange_Flt MRR_FR_Active_Fault_Status_MC MRR_FR_Dolphin_Flt MRR_FR_TO_VehicleState_Flt MRR_FR_CRC_VehicleState_Flt MRR_FR_VINSignalCompare_Flt MRR_FR_Core1Halted_Flt MRR_FR_LocalOscPower_Flt MRR_FR_DSPLoopOverrun_Flt MRR_FR_TransmitterPower_Flt MRR_FR_Core0_To_Core2_IPC_Flt MRR_FR_XCVRDeviceSPI_Flt MRR_FR_MNRBlockage_Flt MRR_FR_AlignRoutineFailed_Flt MRR_FR_v2p3_SupplyOutOfRange_Flt MRR_FR_TransmitterID_Flt MRR_FR_PLLLock_Flt MRR_FR_RAMMemoryTest_Flt MRR_FR_USCValidation_Flt MRR_FR_SMCChecksum_Flt MRR_FR_KeepAliveChecksum_Flt MRR_FR_ApplicationFlashChksum_Fl MRR_FR_v_5_SupplyOutOfRange_Flt MRR_FR_PCANBusOff_Flt MRR_FR_StackOverflow_Flt MRR_FR_InstructionSetCheck_Flt MRR_FR_Watchdog_Flt MRR_FR_v1p8_SupplyOutOfRange_Flt MRR_FR_v1p25_SupplyOutOfRange_Fl MRR_FR_MicroTempHigh_Flt MRR_FR_HAlignOutofRange_Flt MRR_FR_v1p1_SupplyOutOfRange_Flt MRR_FR_TransmitterTempHigh_Flt MRR_FR_Core2Halted_Flt MRR_FR_RRUBIST_Flt MRR_FR_PINPosition_Flt MRR_FR_TO_TrigControl_Flt MRR_FR_MC_AngleAdjTable_Flt MRR_FR_CRC_AngleAdjTable_Flt MRR_FR_Core1_To_Core2_IPC_Flt MRR_FR_Core1_To_Core0_IPC_Flt MRR_FR_CRC_RadarCfgParameter_Flt MRR_FR_CRC_TrigControl_Flt MRR_FR_MC_VehicleState_Flt MRR_FR_MC_TrigControl_Flt MRR_FR_CRC_CADMSgnlActlVal_Flt MRR_FR_MC_CADMSgnlActlVal_Flt MRR_FR_BatteryHigh_Flt MRR_FR_Core0_To_Core1_IPC_Flt MRR_FR_Core2_To_Core0_IPC_Flt MRR_FR_Core2_To_Core1_IPC_Flt MRR_FR_BatteryLow_Flt MRR_FR_RRUCore_Flt MRR_FR_TO_CADMSgnlActlVal_Flt MRR_FR_TO_AngleAdjustmentTable_F MRR_FR_PCANDataRangeChk_Flt MRR_FR_Active_Fault_Status_CRC MRR_FR_TO_RADARCfgParameter_Flt MRR_FR_TO_CADMSWVersion_Flt MRR_FR_TO_SystemTDBlockage_Flt;
